VERSION "JSON_REFERENCE_OPTIONAL_3.1.2"

NS_ :

BS_:

BU_:

BO_ 1177 APP_cameraTemperatures: 8 gtw
 SG_ APP_lRepeaterCameraTemperature : 32|8@1+ (1.0,-60.0) [-60|195] "C"  odin
 SG_ APP_rRepeaterCameraTemperature : 24|8@1+ (1.0,-60.0) [-60|195] "C"  odin

BO_ 970 APS_status: 7 gtw
 SG_ APS_canMaster : 8|2@1+ (1.0,0.0) [0|3] ""  odin,sui,ui,vitals

BO_ 818 BMS_bmbMinMax: 6 gtw
 SG_ BMS_bmbMinMaxMultiplexer M : 0|2@1+ (1.0,0.0) [0|2] "" Vector__XXX
 SG_ BMS_brickNumVoltageMax m1 : 32|7@1+ (1,1) [1|128] ""  odin,ui
 SG_ BMS_brickNumVoltageMin m1 : 40|7@1+ (1,1) [1|128] ""  odin,ui
 SG_ BMS_brickVoltageMax m1 : 2|12@1+ (0.002,0.0) [0|5] "V"  odin,ui,vitals
 SG_ BMS_brickVoltageMin m1 : 16|12@1+ (0.002,0.0) [0|5] "V"  odin,ui,vitals

BO_ 562 BMS_contactorRequest: 8 gtw
 SG_ BMS_hvilCoverVSense : 32|16@1+ (0.001,0.0) [0.0|65.534] "V"  odin
 SG_ BMS_internalHvilSenseV : 16|16@1+ (0.001,0.0) [0.0|65.534] "V"  odin

BO_ 306 BMS_hvBusStatus: 8 gtw
 SG_ BMS_packCurrent : 16|16@1- (0.1,0.0) [-3276.7|3276.7] "A"  odin,ui,vitals

BO_ 884 BMS_log1: 8 gtw
 SG_ BMS_log1MuxId M : 0|8@1+ (1.0,0.0) [0|27] "" Vector__XXX
 SG_ BMS_maxModeledPackTemp m10 : 19|11@1+ (0.1,-50.0) [-50|154.7] "C"  odin
 SG_ BMS_minModeledPackTemp m10 : 8|11@1+ (0.1,-50.0) [-50|154.7] "C"  odin

BO_ 914 BMS_packConfig: 8 gtw
 SG_ BMS_packConfigMultiplexer M : 0|8@1+ (1.0,0.0) [0|1] ""  ui
 SG_ BMS_reservedConfig_0 m0 : 8|5@1+ (1.0,0.0) [0|31] ""  odin,ui

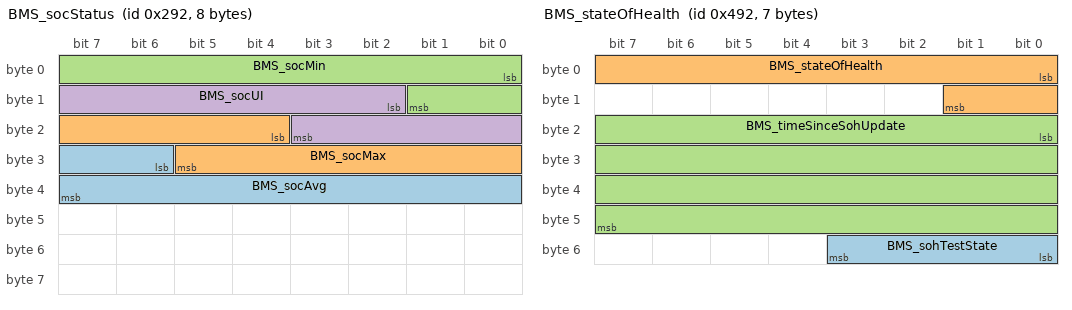
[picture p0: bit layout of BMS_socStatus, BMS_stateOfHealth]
BO_ 658 BMS_socStatus: 8 gtw
 SG_ BMS_socAvg : 30|10@1+ (0.1,0.0) [0|102.2] "%"  odin
 SG_ BMS_socMax : 20|10@1+ (0.1,0.0) [0|102.2] "%"  odin,sui,vitals
 SG_ BMS_socMin : 0|10@1+ (0.1,0.0) [0|102.2] "%"  odin,sui,ui,vitals
 SG_ BMS_socUI : 10|10@1+ (0.1,0.0) [0|100] "%"  odin,ui

BO_ 1170 BMS_stateOfHealth: 7 gtw
 SG_ BMS_sohTestState : 48|4@1+ (1.0,0.0) [0|8] ""  sui
 SG_ BMS_stateOfHealth : 0|10@1+ (0.1,0.0) [0|100] "%"  odin,sui,vitals
 SG_ BMS_timeSinceSohUpdate : 16|32@1+ (1,0) [0|4294967295] "min"  odin,sui,vitals

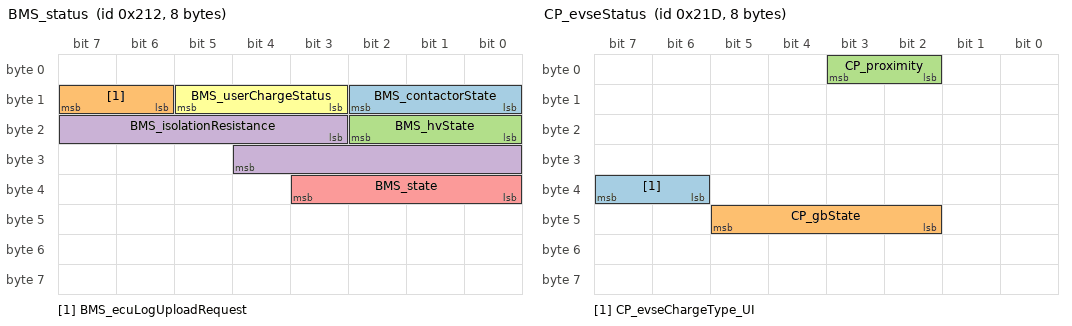
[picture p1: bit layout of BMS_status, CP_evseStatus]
BO_ 530 BMS_status: 8 gtw
 SG_ BMS_contactorState : 8|3@1+ (1.0,0.0) [0|6] ""  odin,sui,ui,vitals
 SG_ BMS_ecuLogUploadRequest : 14|2@1+ (1.0,0.0) [0|3] ""  odin,ui
 SG_ BMS_hvState : 16|3@1+ (1.0,0.0) [0|6] ""  odin,sui,ui,vitals
 SG_ BMS_isolationResistance : 19|10@1+ (10.0,0.0) [0|10000] "kOhm"  odin,sui,ui,vitals
 SG_ BMS_state : 32|4@1+ (1.0,0.0) [0|10] ""  odin,sui,ui,vitals
 SG_ BMS_userChargeStatus : 11|3@1+ (1.0,0.0) [0|6] ""  odin,ui

BO_ 1554 BMS_udsResponse: 8 gtw
 SG_ BMS_udsResponseData : 0|64@0+ (1,0) [0|18446744073709551615] ""  odin

BO_ 1559 CMPD_udsResponse: 8 gtw
 SG_ CMPD_udsResponseData : 7|64@0+ (1,0) [0|18446744073709551615] ""  odin

BO_ 1555 CMP_udsResponse: 8 gtw
 SG_ CMP_udsResponseData : 0|64@0+ (1,0) [0|18446744073709551615] ""  odin

BO_ 541 CP_evseStatus: 8 gtw
 SG_ CP_evseChargeType_UI : 38|2@1+ (1.0,0.0) [0|2] ""  odin,sui,ui
 SG_ CP_gbState : 42|4@1+ (1.0,0.0) [0|15] ""  odin
 SG_ CP_proximity : 2|2@1+ (1.0,0.0) [0|3] ""  odin,sui,ui,vitals

BO_ 1885 CP_loggingFast: 8 gtw
 SG_ CP_chargeCablePresent m0 : 61|1@1+ (1.0,0.0) [0|1] ""  odin,vitals
 SG_ CP_loggingFastSelect M : 0|4@1+ (1.0,0.0) [0|4] "" Vector__XXX

BO_ 528 CP_status: 8 gtw
 SG_ CP_chargeCableState : 14|2@1+ (1.0,0.0) [0|2] ""  odin,ui,vitals

BO_ 1566 CP_udsResponse: 8 gtw
 SG_ CP_udsResponseData : 0|64@0+ (1,0) [0|18446744073709551615] ""  gtwu,odin

BO_ 1625 DAS_udsResponse: 8 gtw
 SG_ DAS_udsResponseData : 0|64@0+ (1,0) [0|18446744073709551615] ""  odin

BO_ 858 DIF_alertMatrix3: 8 gtw
 SG_ DIF_a154_resolver : 25|1@1+ (1,0) [0|1] ""  odin,ui

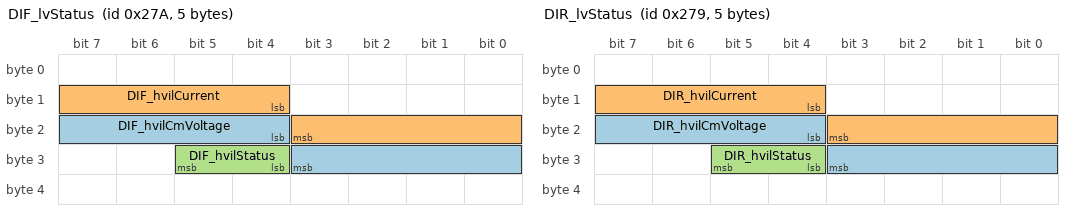
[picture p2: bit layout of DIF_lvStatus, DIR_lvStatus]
BO_ 634 DIF_lvStatus: 5 gtw
 SG_ DIF_hvilCmVoltage : 20|8@1+ (0.08,0.0) [0.0|20.4] "V"  odin
 SG_ DIF_hvilCurrent : 12|8@1+ (0.1,0.0) [0.0|25.5] "mA"  odin
 SG_ DIF_hvilStatus : 28|2@1+ (1.0,0.0) [0|3] ""  odin,vitals

BO_ 725 DIF_status: 7 gtw
 SG_ DIF_wasteState : 32|2@1+ (1.0,0.0) [0|3] ""  odin,sui

BO_ 1557 DIF_udsResponse: 8 gtw
 SG_ DIF_udsResponseData : 7|64@0+ (1,0) [0|18446744073709551615] ""  odin

BO_ 965 DIR_alertMatrix3: 8 gtw
 SG_ DIR_a154_resolver : 25|1@1+ (1,0) [0|1] ""  odin,ui

BO_ 633 DIR_lvStatus: 5 gtw
 SG_ DIR_hvilCmVoltage : 20|8@1+ (0.08,0.0) [0.0|20.4] "V"  odin
 SG_ DIR_hvilCurrent : 12|8@1+ (0.1,0.0) [0.0|25.5] "mA"  odin
 SG_ DIR_hvilStatus : 28|2@1+ (1.0,0.0) [0|3] ""  odin,sui,vitals

BO_ 598 DIR_status: 7 gtw
 SG_ DIR_state : 12|3@1+ (1.0,0.0) [0|4] ""  odin,sui,ui
 SG_ DIR_wasteState : 32|2@1+ (1.0,0.0) [0|3] ""  odin

BO_ 1558 DIR_udsResponse: 8 gtw
 SG_ DIR_udsResponseData : 7|64@0+ (1,0) [0|18446744073709551615] ""  odin

BO_ 599 DI_speed: 8 gtw
 SG_ DI_vehicleSpeed : 43|13@1+ (0.08,-40.0) [-40|480] "kph"  adsp,odin,ui

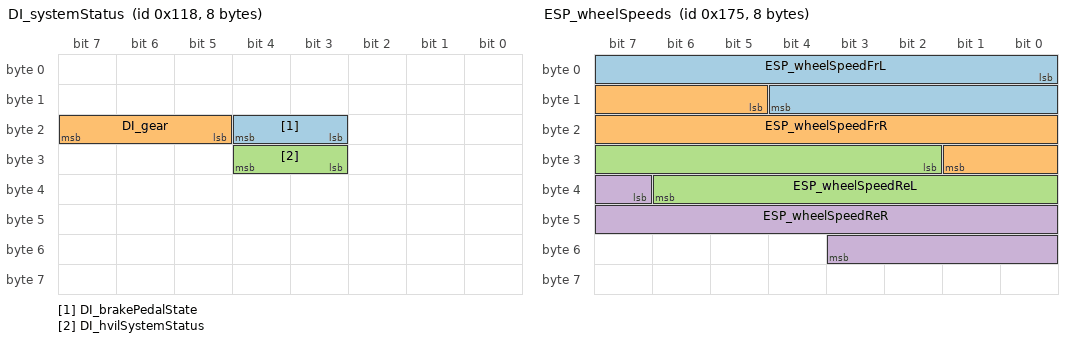
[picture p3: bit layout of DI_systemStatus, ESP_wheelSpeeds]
BO_ 280 DI_systemStatus: 8 gtw
 SG_ DI_brakePedalState : 19|2@1+ (1.0,0.0) [0|2] ""  odin
 SG_ DI_gear : 21|3@1+ (1.0,0.0) [0|7] ""  adsp,odin,sui,ui
 SG_ DI_hvilSystemStatus : 27|2@1+ (1.0,0.0) [0|3] ""  odin

BO_ 615 DI_vehicleEstimates: 8 gtw
 SG_ DI_steeringAngleOffset : 56|8@1- (0.2,0.0) [-25.6|25.4] "Deg"  odin,vitals

BO_ 977 EPAS3P_angleCalibration: 8 gtw
 SG_ EPAS3P_appliedAngleOffset : 0|8@1+ (0.1,-12.8) [-12.8|12.7] "deg"  odin,sui,vitals

BO_ 883 EPAS3P_sysStatus: 8 gtw
 SG_ EPAS3P_internalSAS : 32|14@0+ (0.1,-819.2) [-819.2|819] "deg"  odin
 SG_ EPAS3P_torsionBarTorque : 16|12@0+ (0.01,-20.5) [-20.5|20.45] "Nm"  odin

BO_ 1592 EPAS3P_udsResponseCH: 8 gtw
 SG_ EPAS3P_udsResponseDataCH : 0|64@0+ (1,0) [0|18446744073709551615] ""  odin

BO_ 882 EPAS3S_sysStatus: 8 gtw
 SG_ EPAS3S_torsionBarTorque : 16|12@0+ (0.01,-20.5) [-20.5|20.45] "Nm"  odin

BO_ 1848 EPAS3S_udsResponse: 8 gtw
 SG_ EPAS3S_udsResponseData : 0|64@0+ (1,0) [0|18446744073709551615] ""  odin

BO_ 681 EPBL_status: 8 gtw
 SG_ EPBL_systemStatus : 0|4@1+ (1.0,0.0) [0|8] ""  odin,sui,ui,vitals

BO_ 1573 EPBL_udsResponse: 8 gtw
 SG_ EPBL_udsResponseData_H : 0|32@0+ (1,0) [0|4294967295] ""  odin
 SG_ EPBL_udsResponseData_L : 32|32@0+ (1,0) [0|4294967295] ""  odin

BO_ 744 EPBR_status: 8 gtw
 SG_ EPBR_systemStatus : 0|4@1+ (1.0,0.0) [0|8] ""  odin,sui,ui,vitals

BO_ 1575 EPBR_udsResponse: 8 gtw
 SG_ EPBR_udsResponseData_H : 0|32@0+ (1,0) [0|4294967295] ""  odin
 SG_ EPBR_udsResponseData_L : 32|32@0+ (1,0) [0|4294967295] ""  odin

BO_ 325 ESP_status: 8 gtw
 SG_ ESP_stabilityControlSts2 : 14|2@1+ (1.0,0.0) [0|3] ""  odin,sui

BO_ 1621 ESP_udsResponse: 8 gtw
 SG_ ESP_udsResponseData : 0|64@0+ (1,0) [0|18446744073709551615] ""  odin

BO_ 373 ESP_wheelSpeeds: 8 gtw
 SG_ ESP_wheelSpeedFrL : 0|13@1+ (0.042,0.0) [0|343.98] "km/h"  odin
 SG_ ESP_wheelSpeedFrR : 13|13@1+ (0.042,0.0) [0|343.98] "km/h"  odin
 SG_ ESP_wheelSpeedReL : 26|13@1+ (0.042,0.0) [0|343.98] "km/h"  odin
 SG_ ESP_wheelSpeedReR : 39|13@1+ (0.042,0.0) [0|343.98] "km/h"  odin

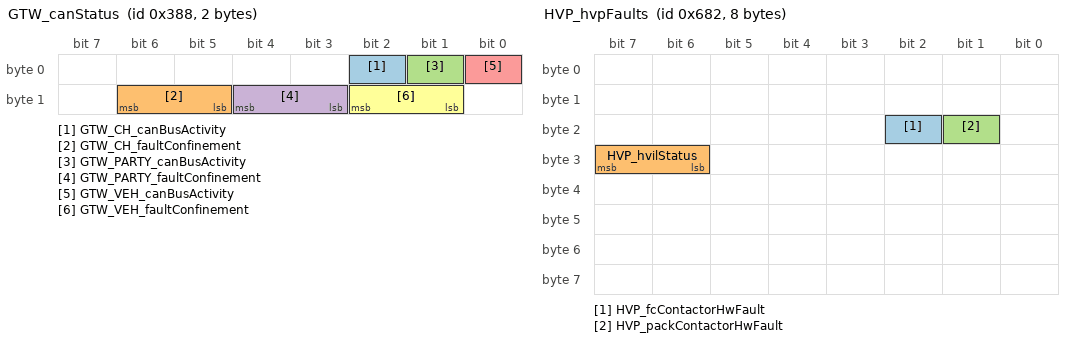
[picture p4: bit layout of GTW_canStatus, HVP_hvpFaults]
BO_ 904 GTW_canStatus: 2 gtw
 SG_ GTW_CH_canBusActivity : 2|1@1+ (1,0) [0|1] ""  odin,sui,ui
 SG_ GTW_CH_faultConfinement : 13|2@1+ (1.0,0.0) [0|2] ""  odin,ui
 SG_ GTW_PARTY_canBusActivity : 1|1@1+ (1,0) [0|1] ""  odin,sui,ui
 SG_ GTW_PARTY_faultConfinement : 11|2@1+ (1.0,0.0) [0|2] ""  odin,ui
 SG_ GTW_VEH_canBusActivity : 0|1@1+ (1,0) [0|1] ""  odin,sui,ui
 SG_ GTW_VEH_faultConfinement : 9|2@1+ (1.0,0.0) [0|2] ""  odin,ui

BO_ 2047 GTW_carConfig: 8 gtw
 SG_ GTW_carConfigMultiplexer M : 0|8@1+ (1,0) [0|255] ""  ui,vitals
 SG_ GTW_chassisType m3 : 18|3@1+ (1.0,0.0) [0|6] ""  odin,ui,vitals
 SG_ GTW_deliveryStatus m1 : 8|1@1+ (1.0,0.0) [0|1] ""  odin,ui,vitals
 SG_ GTW_drivetrainType m1 : 56|4@1+ (1.0,0.0) [0|2] ""  odin,ui,vitals
 SG_ GTW_epasType m6 : 33|3@1+ (1.0,0.0) [0|5] ""  odin,ui,vitals
 SG_ GTW_headlightLevelerType m2 : 59|2@1+ (1.0,0.0) [0|2] ""  odin,ui,vitals
 SG_ GTW_mapRegion m3 : 8|4@1+ (1.0,0.0) [0|12] ""  odin,ui,vitals
 SG_ GTW_numberHVILNodes m2 : 62|2@1+ (1.0,0.0) [0|3] ""  odin,ui,vitals

BO_ 1638 GTW_diagSession: 4 gtw
 SG_ GTW_diagLevel : 17|7@1+ (1.0,0.0) [0|100] ""  odin,sui,ui
 SG_ GTW_diagRemainingSeconds : 0|16@1+ (1,0) [0|65535] "seconds"  odin,sui,ui

BO_ 1376 GTW_factoryEcuPresent: 4 gtw
 SG_ GTW_BMSpresent : 3|1@1+ (1,0) [0|1] ""  odin
 SG_ GTW_CMPpresent : 20|1@1+ (1,0) [0|1] ""  odin
 SG_ GTW_CPpresent : 4|1@1+ (1,0) [0|1] ""  odin
 SG_ GTW_DASpresent : 21|1@1+ (1,0) [0|1] ""  odin
 SG_ GTW_DIFpresent : 28|1@1+ (1,0) [0|1] ""  odin
 SG_ GTW_DIRpresent : 27|1@1+ (1,0) [0|1] ""  odin
 SG_ GTW_EPAS3Ppresent : 8|1@1+ (1,0) [0|1] ""  odin
 SG_ GTW_EPAS3Spresent : 19|1@1+ (1,0) [0|1] ""  odin
 SG_ GTW_EPBLpresent : 9|1@1+ (1,0) [0|1] ""  odin
 SG_ GTW_EPBRpresent : 10|1@1+ (1,0) [0|1] ""  odin
 SG_ GTW_ESPpresent : 11|1@1+ (1,0) [0|1] ""  odin
 SG_ GTW_HVPpresent : 2|1@1+ (1,0) [0|1] ""  odin
 SG_ GTW_IBSTpresent : 12|1@1+ (1,0) [0|1] ""  odin
 SG_ GTW_OCS1Ppresent : 0|1@1+ (1,0) [0|1] ""  odin
 SG_ GTW_PARKpresent : 13|1@1+ (1,0) [0|1] ""  odin
 SG_ GTW_PCSpresent : 1|1@1+ (1,0) [0|1] ""  odin
 SG_ GTW_PMFpresent : 26|1@1+ (1,0) [0|1] ""  odin
 SG_ GTW_PMRpresent : 25|1@1+ (1,0) [0|1] ""  odin
 SG_ GTW_PTCpresent : 22|1@1+ (1,0) [0|1] ""  odin
 SG_ GTW_RADCpresent : 14|1@1+ (1,0) [0|1] ""  odin
 SG_ GTW_RCMpresent : 5|1@1+ (1,0) [0|1] ""  odin
 SG_ GTW_SCCMpresent : 6|1@1+ (1,0) [0|1] ""  odin
 SG_ GTW_SWCpresent : 23|1@1+ (1,0) [0|1] ""  odin
 SG_ GTW_TPMSpresent : 15|1@1+ (1,0) [0|1] ""  odin
 SG_ GTW_VCFRONTpresent : 16|1@1+ (1,0) [0|1] ""  odin
 SG_ GTW_VCLEFTpresent : 17|1@1+ (1,0) [0|1] ""  odin
 SG_ GTW_VCRIGHTpresent : 18|1@1+ (1,0) [0|1] ""  odin
 SG_ GTW_VCSECpresent : 7|1@1+ (1,0) [0|1] ""  odin

BO_ 522 HVP_contactorState: 6 gtw
 SG_ HVP_hvilDiag : 40|4@1+ (1.0,0.0) [0|14] ""  odin,ui,vitals

BO_ 1962 HVP_debugMessage: 8 gtw
 SG_ HVP_debugMessageMultiplexer M : 0|4@1+ (1.0,0.0) [0|12] "" Vector__XXX
 SG_ HVP_ecuLogUploadRequest m0 : 46|2@1+ (1.0,0.0) [0|3] ""  odin,ui
 SG_ HVP_hvilInVoltage m4 : 28|12@1+ (0.1,0.0) [0|30] "V"  odin,ui,vitals
 SG_ HVP_hvilOutVoltage m4 : 40|12@1+ (0.1,0.0) [0|30] "V"  odin,ui,vitals

BO_ 1666 HVP_hvpFaults: 8 gtw
 SG_ HVP_fcContactorHwFault : 18|1@1+ (1,0) [0|1] ""  odin
 SG_ HVP_hvilStatus : 30|2@1+ (1.0,0.0) [0|2] ""  odin,sui
 SG_ HVP_packContactorHwFault : 17|1@1+ (1,0) [0|1] ""  odin

BO_ 1553 HVP_udsResponse: 8 gtw
 SG_ HVP_udsResponseData : 0|64@0+ (1,0) [0|18446744073709551615] ""  gtwu,odin

BO_ 925 IBST_status: 5 gtw
 SG_ IBST_driverBrakeApply : 16|2@1+ (1.0,0.0) [0|3] ""  odin,sui
 SG_ IBST_iBoosterStatus : 12|3@1+ (1.0,0.0) [0|6] ""  odin,sui,ui

BO_ 1629 IBST_udsResponse: 8 gtw
 SG_ IBST_udsResponseData : 0|64@0+ (1,0) [0|18446744073709551615] ""  odin

BO_ 1624 ICR_udsResponse: 8 gtw
 SG_ ICR_udsResponseData : 7|64@0+ (1,0) [0|18446744073709551615] ""  odin

BO_ 771 OCS1P_status: 8 gtw
 SG_ OCS1P_occupiedState : 9|2@1+ (1.0,0.0) [0|3] ""  odin

BO_ 1619 OCS1P_udsResponse: 8 gtw
 SG_ OCS1P_udsResponseData : 0|64@1+ (1,0) [0|18446744073709551615] ""  odin

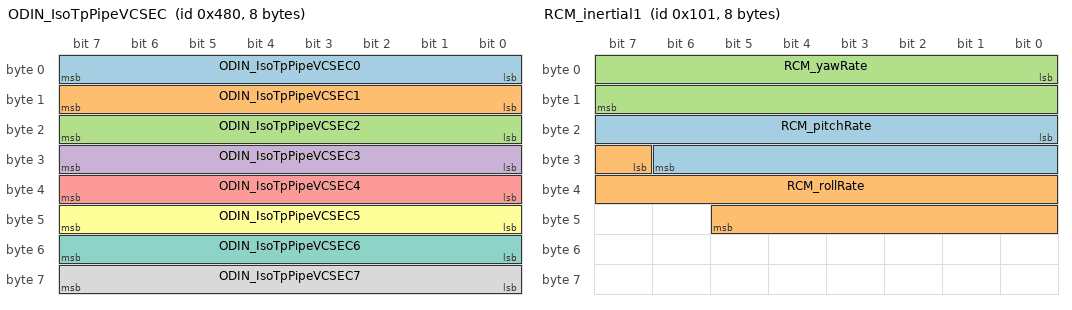
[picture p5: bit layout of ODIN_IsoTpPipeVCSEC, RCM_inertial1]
BO_ 1152 ODIN_IsoTpPipeVCSEC: 8 odin
 SG_ ODIN_IsoTpPipeVCSEC0 : 0|8@1+ (1,0) [0|255] ""  gtw
 SG_ ODIN_IsoTpPipeVCSEC1 : 8|8@1+ (1,0) [0|255] ""  gtw
 SG_ ODIN_IsoTpPipeVCSEC2 : 16|8@1+ (1,0) [0|255] ""  gtw
 SG_ ODIN_IsoTpPipeVCSEC3 : 24|8@1+ (1,0) [0|255] ""  gtw
 SG_ ODIN_IsoTpPipeVCSEC4 : 32|8@1+ (1,0) [0|255] ""  gtw
 SG_ ODIN_IsoTpPipeVCSEC5 : 40|8@1+ (1,0) [0|255] ""  gtw
 SG_ ODIN_IsoTpPipeVCSEC6 : 48|8@1+ (1,0) [0|255] ""  gtw
 SG_ ODIN_IsoTpPipeVCSEC7 : 56|8@1+ (1,0) [0|255] ""  gtw

BO_ 782 PARK_status2: 8 gtw
 SG_ PARK_sdiActive : 24|1@1+ (1.0,0.0) [0|1] ""  odin,sui,ui

BO_ 1630 PARK_udsResponse: 8 gtw
 SG_ PARK_udsResponseData : 0|64@1+ (1,0) [0|18446744073709551615] ""  odin

BO_ 692 PCS_dcdcRailStatus: 6 gtw
 SG_ PCS_dcdcLvBusVolt : 0|13@1+ (0.01,0.0) [0|80] "V"  odin,sui,ui,vitals
 SG_ PCS_dcdcLvOutputCurrent : 32|13@1- (0.1,0.0) [-400|400] "A"  odin,sui,ui,vitals

BO_ 548 PCS_dcdcStatus: 8 gtw
 SG_ PCS_dcdcLvSupportStatus : 2|2@1+ (1.0,0.0) [0|2] ""  odin,sui,ui,vitals
 SG_ PCS_ecuLogUploadRequest : 54|2@1+ (1.0,0.0) [0|3] ""  odin,ui

BO_ 1577 PCS_udsResponse: 8 gtw
 SG_ PCS_udsResponseData : 0|64@0+ (1,0) [0|18446744073709551615] ""  gtwu,odin

BO_ 1635 PLG_udsResponse: 8 gtw
 SG_ PLG_udsResponseData : 7|64@0+ (1,0) [0|18446744073709551615] ""  odin

BO_ 469 PMF_state4: 8 gtw
 SG_ PMF_hvilStatus : 37|2@1+ (1.0,0.0) [0|3] ""  odin

BO_ 1620 PMF_udsResponse: 8 gtw
 SG_ PMF_udsResponseData : 7|64@0+ (1,0) [0|18446744073709551615] ""  odin

BO_ 472 PMR_state4: 8 gtw
 SG_ PMR_hvilStatus : 37|2@1+ (1.0,0.0) [0|3] ""  odin

BO_ 1556 PMR_udsResponse: 8 gtw
 SG_ PMR_udsResponseData : 7|64@0+ (1,0) [0|18446744073709551615] ""  odin

BO_ 463 PM_systemState: 8 gtw
 SG_ PM_hvilSystemStatus : 24|2@1+ (1.0,0.0) [0|3] ""  odin

BO_ 1600 PM_udsResponse: 8 gtw
 SG_ PM_udsResponseData : 7|64@0+ (1,0) [0|18446744073709551615] ""  odin

BO_ 1750 PTC_udsResponse: 8 gtw
 SG_ PTC_udsResponseData : 0|64@0+ (1,0) [0|18446744073709551615] ""  odin

BO_ 1665 RADC_udsResponse: 8 gtw
 SG_ RADC_udsResponseData : 0|64@0+ (1,0) [0|18446744073709551615] ""  gtwu,odin

BO_ 257 RCM_inertial1: 8 gtw
 SG_ RCM_pitchRate : 16|15@1- (0.00025,0.0) [-4.096|4.09575] "rad/s"  odin,ui
 SG_ RCM_rollRate : 31|15@1- (0.00025,0.0) [-4.096|4.09575] "rad/s"  odin,ui
 SG_ RCM_yawRate : 0|16@1- (0.0001,0.0) [-3.2766|3.2766] "rad/s"  odin,ui

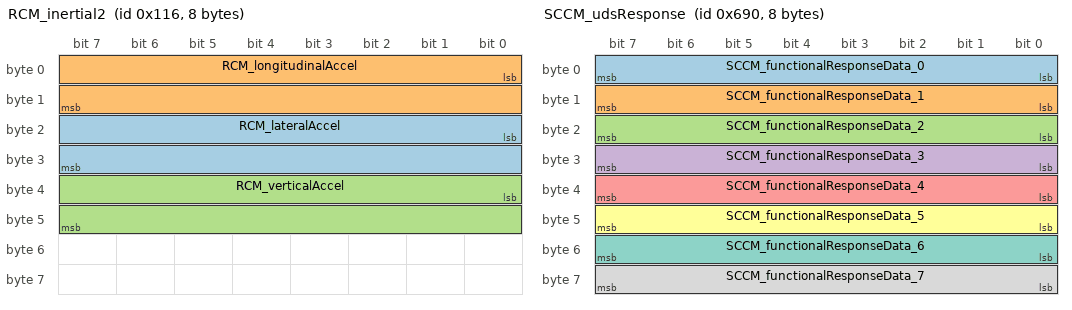
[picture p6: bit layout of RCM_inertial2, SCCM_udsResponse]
BO_ 278 RCM_inertial2: 8 gtw
 SG_ RCM_lateralAccel : 16|16@1- (0.00125,0.0) [-40.9575|40.9575] "m/s^2"  odin,ui
 SG_ RCM_longitudinalAccel : 0|16@1- (0.00125,0.0) [-40.9575|40.9575] "m/s^2"  odin,ui
 SG_ RCM_verticalAccel : 32|16@1- (0.00125,0.0) [-40.9575|40.9575] "m/s^2"  odin,ui

BO_ 529 RCM_status: 6 gtw
 SG_ RCM_armStatus : 12|2@1+ (1.0,0.0) [0|3] ""  odin,sui,ui

BO_ 1617 RCM_udsResponse: 8 gtw
 SG_ RCM_udsResponseData : 0|64@0+ (1,0) [0|18446744073709551615] ""  odin

BO_ 297 SCCM_steeringAngleSensor: 8 gtw
 SG_ SCCM_steeringAngle : 16|14@1+ (0.1,-819.2) [-819.2|819] "deg"  odin,sui,ui

BO_ 1680 SCCM_udsResponse: 8 gtw
 SG_ SCCM_functionalResponseData_0 : 0|8@1+ (1,0) [0|255] ""  odin
 SG_ SCCM_functionalResponseData_1 : 8|8@1+ (1,0) [0|255] ""  odin
 SG_ SCCM_functionalResponseData_2 : 16|8@1+ (1,0) [0|255] ""  odin
 SG_ SCCM_functionalResponseData_3 : 24|8@1+ (1,0) [0|255] ""  odin
 SG_ SCCM_functionalResponseData_4 : 32|8@1+ (1,0) [0|255] ""  odin
 SG_ SCCM_functionalResponseData_5 : 40|8@1+ (1,0) [0|255] ""  odin
 SG_ SCCM_functionalResponseData_6 : 48|8@1+ (1,0) [0|255] ""  odin
 SG_ SCCM_functionalResponseData_7 : 56|8@1+ (1,0) [0|255] ""  odin

BO_ 1787 SDCR_udsResponse: 8 gtw
 SG_ SDCR_udsResponseData : 7|64@0+ (1,0) [0|18446744073709551615] ""  odin

BO_ 1627 TAS_udsResponse: 8 gtw
 SG_ TAS_udsResponseData : 0|64@0+ (1,0) [0|18446744073709551615] ""  odin

BO_ 1631 TPMS_udsResponse: 8 gtw
 SG_ TPMS_udsResponseData : 0|64@0+ (1,0) [0|18446744073709551615] ""  odin

BO_ 1641 UDS_KOSTIAsccmRequest: 8 odin
 SG_ UDS_KOSTIAsccmRequestData : 0|64@0+ (1,0) [0|18446744073709551615] ""  gtw

BO_ 1538 UDS_bmsRequest: 8 odin
 SG_ UDS_bmsRequestData : 0|64@0+ (1,0) [0|18446744073709551615] ""  gtw

BO_ 1579 UDS_ccRequest: 8 odin
 SG_ UDS_ccRequestData : 0|64@0+ (1,0) [0|18446744073709551615] ""  gtw

BO_ 1539 UDS_cmpRequest: 8 odin
 SG_ UDS_cmpRequestData : 0|64@0+ (1,0) [0|18446744073709551615] ""  gtw

BO_ 1543 UDS_cmpdRequest: 8 odin
 SG_ UDS_cmpdRequestData : 7|64@0+ (1,0) [0|18446744073709551615] ""  gtw

BO_ 1550 UDS_cpRequest: 8 odin
 SG_ UDS_cpRequestData : 0|64@0+ (1,0) [0|18446744073709551615] ""  gtw

BO_ 1609 UDS_dasRequest: 8 odin
 SG_ UDS_dasRequestData : 0|64@0+ (1,0) [0|18446744073709551615] ""  gtw

BO_ 1589 UDS_diRequest: 8 odin
 SG_ UDS_diRequestData : 7|64@0+ (1,0) [0|18446744073709551615] ""  gtw

BO_ 1541 UDS_difRequest: 8 odin
 SG_ UDS_difRequestData : 7|64@0+ (1,0) [0|18446744073709551615] ""  gtw

BO_ 1542 UDS_dirRequest: 8 odin
 SG_ UDS_dirRequestData : 7|64@0+ (1,0) [0|18446744073709551615] ""  gtw

BO_ 1584 UDS_epas3pRequest: 8 odin
 SG_ UDS_epas3pRequestData : 0|64@0+ (1,0) [0|18446744073709551615] ""  gtw

BO_ 1840 UDS_epas3sRequest: 8 odin
 SG_ UDS_epas3sRequestData : 0|64@0+ (1,0) [0|18446744073709551615] ""  gtw

BO_ 1572 UDS_epblRequest: 8 odin
 SG_ UDS_epblRequestData_H : 0|32@0+ (1,0) [0|4294967295] ""  gtw
 SG_ UDS_epblRequestData_L : 32|32@0+ (1,0) [0|4294967295] ""  gtw

BO_ 1574 UDS_epbrRequest: 8 odin
 SG_ UDS_epbrRequestData_H : 0|32@0+ (1,0) [0|4294967295] ""  gtw
 SG_ UDS_epbrRequestData_L : 32|32@0+ (1,0) [0|4294967295] ""  gtw

BO_ 1605 UDS_espRequest: 8 odin
 SG_ UDS_espRequestData : 0|64@0+ (1,0) [0|18446744073709551615] ""  gtw

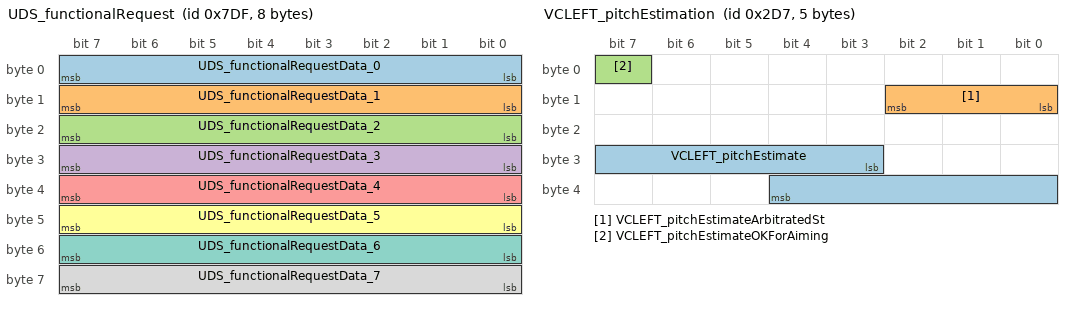
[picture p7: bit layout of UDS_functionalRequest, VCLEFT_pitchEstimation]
BO_ 2015 UDS_functionalRequest: 8 odin
 SG_ UDS_functionalRequestData_0 : 0|8@1+ (1,0) [0|255] ""  gtw
 SG_ UDS_functionalRequestData_1 : 8|8@1+ (1,0) [0|255] ""  gtw
 SG_ UDS_functionalRequestData_2 : 16|8@1+ (1,0) [0|255] ""  gtw
 SG_ UDS_functionalRequestData_3 : 24|8@1+ (1,0) [0|255] ""  gtw
 SG_ UDS_functionalRequestData_4 : 32|8@1+ (1,0) [0|255] ""  gtw
 SG_ UDS_functionalRequestData_5 : 40|8@1+ (1,0) [0|255] ""  gtw
 SG_ UDS_functionalRequestData_6 : 48|8@1+ (1,0) [0|255] ""  gtw
 SG_ UDS_functionalRequestData_7 : 56|8@1+ (1,0) [0|255] ""  gtw

BO_ 2014 UDS_functionalRequest_CH: 8 odin
 SG_ UDS_functionalRequestDataCH : 7|64@0+ (1,0) [0|18446744073709551615] ""  gtw

BO_ 1552 UDS_hvpRequest: 8 odin
 SG_ UDS_hvpRequestData : 0|64@0+ (1,0) [0|18446744073709551615] ""  gtw

BO_ 1613 UDS_ibstRequest: 8 odin
 SG_ UDS_ibstRequestData : 0|64@0+ (1,0) [0|18446744073709551615] ""  gtw

BO_ 1560 UDS_icrRequest: 8 odin
 SG_ UDS_icrRequestData : 7|64@0+ (1,0) [0|18446744073709551615] ""  gtw

BO_ 1603 UDS_ocs1pRequest: 8 odin
 SG_ UDS_ocs1pRequestData : 0|64@0+ (1,0) [0|18446744073709551615] ""  gtw

BO_ 1614 UDS_parkRequest: 8 odin
 SG_ UDS_parkRequestData : 0|64@0+ (1,0) [0|18446744073709551615] ""  gtw

BO_ 1576 UDS_pcsRequest: 8 odin
 SG_ UDS_pcsRequestData : 0|64@0+ (1,0) [0|18446744073709551615] ""  gtw

BO_ 1634 UDS_plgRequest: 8 odin
 SG_ UDS_plgRequestData : 7|64@0+ (1,0) [0|18446744073709551615] ""  gtw

BO_ 1568 UDS_pmRequest: 8 odin
 SG_ UDS_pmRequestData : 7|64@0+ (1,0) [0|18446744073709551615] ""  gtw

BO_ 1604 UDS_pmfRequest: 8 odin
 SG_ UDS_pmfRequestData : 7|64@0+ (1,0) [0|18446744073709551615] ""  gtw

BO_ 1540 UDS_pmrRequest: 8 odin
 SG_ UDS_pmrRequestData : 7|64@0+ (1,0) [0|18446744073709551615] ""  gtw

BO_ 1734 UDS_ptcRequest: 8 odin
 SG_ UDS_ptcRequestData : 0|64@0+ (1,0) [0|18446744073709551615] ""  gtw

BO_ 1649 UDS_radcRequest: 8 odin
 SG_ UDS_radcRequestData : 0|64@0+ (1,0) [0|18446744073709551615] ""  gtw

BO_ 1601 UDS_rcmRequest: 8 odin
 SG_ UDS_rcmRequestData : 0|64@0+ (1,0) [0|18446744073709551615] ""  gtw

BO_ 1664 UDS_sccmRequest: 8 odin
 SG_ UDS_sccmRequestData : 0|64@0+ (1,0) [0|18446744073709551615] ""  gtw

BO_ 1723 UDS_sdcrRequest: 8 odin
 SG_ UDS_sdcrRequestData : 7|64@0+ (1,0) [0|18446744073709551615] ""  gtw

BO_ 1611 UDS_tasRequest: 8 odin
 SG_ UDS_tasRequestData : 0|64@0+ (1,0) [0|18446744073709551615] ""  gtw

BO_ 1551 UDS_thcRequest: 8 odin
 SG_ UDS_thcRequestData_H : 0|32@0+ (1,0) [0|4294967295] "" Vector__XXX
 SG_ UDS_thcRequestData_L : 32|32@0+ (1,0) [0|4294967295] "" Vector__XXX

BO_ 1615 UDS_tpmsRequest: 8 odin
 SG_ UDS_tpmsRequestData : 0|64@0+ (1,0) [0|18446744073709551615] ""  gtw

BO_ 1536 UDS_vcfrontRequest: 8 odin
 SG_ UDS_vcfrontRequestData : 0|64@0+ (1,0) [0|18446744073709551615] ""  gtw

BO_ 1570 UDS_vcleftRequest: 8 odin
 SG_ UDS_vcleftRequestData_H : 0|32@0+ (1,0) [0|4294967295] ""  gtw
 SG_ UDS_vcleftRequestData_L : 32|32@0+ (1,0) [0|4294967295] ""  gtw

BO_ 1544 UDS_vcrightRequest: 8 odin
 SG_ UDS_vcrightRequestData_H : 0|32@0+ (1,0) [0|4294967295] ""  gtw
 SG_ UDS_vcrightRequestData_L : 32|32@0+ (1,0) [0|4294967295] ""  gtw

BO_ 1546 UDS_vcsecRequest: 8 odin
 SG_ UDS_vcsecRequestData : 0|64@0+ (1,0) [0|18446744073709551615] ""  gtw

BO_ 1056 UIS_log: 8 uis
 SG_ UIS_amdSocPkgPower m246 : 32|32@1+ (1,0) [0|4294967295] ""  gtw,odin
 SG_ UIS_logMux M : 0|32@1+ (1.0,0.0) [0|247] "" Vector__XXX
 SG_ UIS_odinAuthCount m95 : 32|32@1+ (1,0) [0|4294967295] ""  gtw
 SG_ UIS_odinAuthFailCount m94 : 32|32@1+ (1,0) [0|4294967295] ""  gtw
 SG_ UIS_odinCPUUsage m93 : 32|32@1+ (1,0) [0|4294967295] ""  gtw
 SG_ UIS_odinGatewayConnectionState m92 : 32|32@1+ (1.0,0.0) [0|2] ""  gtw
 SG_ UIS_odinHermesConnectionState m91 : 32|32@1+ (1.0,0.0) [0|3] ""  gtw
 SG_ UIS_odinListTasksCmdDurationMs m90 : 32|32@1+ (1,0) [0|4294967295] ""  gtw
 SG_ UIS_odinListTasksCmdResult m89 : 32|32@1+ (1.0,0.0) [0|2] ""  gtw
 SG_ UIS_odinMemUsage m88 : 32|32@1+ (1,0) [0|4294967295] ""  gtw
 SG_ UIS_odinNetworkFailCount m87 : 32|32@1+ (1,0) [0|4294967295] ""  gtw
 SG_ UIS_odinNetworkStartCount m86 : 32|32@1+ (1,0) [0|4294967295] ""  gtw
 SG_ UIS_odinOrchestratorFailCount m85 : 32|32@1+ (1,0) [0|4294967295] ""  gtw
 SG_ UIS_odinOrchestratorStartCount m84 : 32|32@1+ (1,0) [0|4294967295] ""  gtw
 SG_ UIS_odinProcessState m83 : 32|32@1+ (1.0,0.0) [0|4] ""  gtw
 SG_ UIS_odinStatusCmdDurationMs m82 : 32|32@1+ (1,0) [0|4294967295] ""  gtw
 SG_ UIS_odinStatusCmdResult m81 : 32|32@1+ (1.0,0.0) [0|2] ""  gtw
 SG_ UIS_odincefCPUUsage m80 : 32|32@1+ (1,0) [0|4294967295] ""  gtw
 SG_ UIS_odincefMemUsage m79 : 32|32@1+ (1,0) [0|4294967295] ""  gtw

BO_ 545 VCFRONT_LVPowerState: 8 gtw
 SG_ VCFRONT_LVPowerStateIndex M : 0|5@1+ (1.0,0.0) [0|1] "" Vector__XXX
 SG_ VCFRONT_dirLVRequest m0 : 34|2@1+ (1.0,0.0) [0|3] ""  odin
 SG_ VCFRONT_vehiclePowerState : 5|2@1+ (1.0,0.0) [0|3] ""  odin,sui,ui,vitals

BO_ 832 VCFRONT_alertMatrix: 8 gtw
 SG_ VCFRONT_a127_vcleftEFuseTrip m2 : 10|1@1+ (1,0) [0|1] ""  odin,ui
 SG_ VCFRONT_a128_vcrightEFuseTrip m2 : 11|1@1+ (1,0) [0|1] ""  odin,ui
 SG_ VCFRONT_a199_PRVCANUndertrminate m3 : 22|1@1+ (1,0) [0|1] ""  odin,ui
 SG_ VCFRONT_a208_brakeFluidLow m3 : 31|1@1+ (1,0) [0|1] ""  odin,ui
 SG_ VCFRONT_a355_coolantSysLockout m5 : 58|1@1+ (1,0) [0|1] ""  odin,ui
 SG_ VCFRONT_a356_refrigSysLockout m5 : 59|1@1+ (1,0) [0|1] ""  odin,ui
 SG_ VCFRONT_matrixIndex M : 0|4@1+ (1.0,0.0) [0|15] ""  ui

BO_ 1014 VCFRONT_lightStatus: 5 gtw
 SG_ VCFRONT_turnSignalLeftStatus : 22|2@1+ (1.0,0.0) [0|3] ""  odin,ui
 SG_ VCFRONT_turnSignalRightStatus : 24|2@1+ (1.0,0.0) [0|3] ""  odin,ui

BO_ 897 VCFRONT_logging1Hz: 8 gtw
 SG_ VCFRONT_currentHorizPositionHCML m19 : 26|10@1+ (1.0,0.0) [0|1022] "Steps"  odin
 SG_ VCFRONT_currentHorizPositionHCMR m19 : 36|10@1+ (1.0,0.0) [0|1022] "Steps"  odin
 SG_ VCFRONT_logging1HzIndex M : 0|5@1+ (1.0,0.0) [0|30] "" Vector__XXX
 SG_ VCFRONT_pumpPowertrainRPMTarget m25 : 35|8@1+ (30.0,0.0) [0|7500] "rpm"  odin
 SG_ VCFRONT_radiatorFanRPMTarget m25 : 51|8@1+ (40.0,0.0) [0|10000] "rpm"  odin

BO_ 513 VCFRONT_loggingAndVitals10Hz: 8 gtw
 SG_ VCFRONT_activeLouverOpenPos m0 : 47|7@1+ (1,0) [0|100] "%"  odin,ui,vitals
 SG_ VCFRONT_coolantValveMode m1 : 32|2@1+ (1.0,0.0) [0|3] ""  odin,sui,ui,vitals
 SG_ VCFRONT_loggingAndVitals10HzInde M : 0|3@1+ (1.0,0.0) [0|4] "" Vector__XXX
 SG_ VCFRONT_pumpPowertrainRPMActual m0 : 16|8@1+ (30.0,0.0) [0|7500] "rpm"  odin,sui,ui,vitals
 SG_ VCFRONT_radiatorFanRPMActual m0 : 24|8@1+ (40.0,0.0) [0|10000] "rpm"  odin,sui,ui,vitals

BO_ 801 VCFRONT_sensors: 8 gtw
 SG_ VCFRONT_tempCoolantBatInlet : 0|10@1+ (0.125,-40.0) [-40|85] "degC"  odin,sui,ui,vitals
 SG_ VCFRONT_tempCoolantPTInlet : 10|11@1+ (0.125,-40.0) [-40|200] "degC"  odin,sui,ui,vitals

BO_ 737 VCFRONT_status: 8 gtw
 SG_ VCFRONT_anyClosureOpen m0 : 49|1@1+ (1,0) [0|1] ""  odin
 SG_ VCFRONT_coolantFillRoutineStatus m3 : 52|2@1+ (1.0,0.0) [0|3] ""  odin,sui,ui
 SG_ VCFRONT_frunkLatchStatus m0 : 3|4@1+ (1.0,0.0) [0|8] ""  odin,ui
 SG_ VCFRONT_refrigFillRoutineStatus m3 : 54|2@1+ (1.0,0.0) [0|3] ""  odin,sui,ui
 SG_ VCFRONT_statusIndex M : 0|3@1+ (1.0,0.0) [0|7] "" Vector__XXX

BO_ 1537 VCFRONT_udsResponse: 8 gtw
 SG_ VCFRONT_udsResponseData : 0|64@0+ (1,0) [0|18446744073709551615] ""  odin

BO_ 864 VCLEFT_alertMatrix: 8 gtw
 SG_ VCLEFT_a251_seatUncalTrack m4 : 14|1@1+ (1,0) [0|1] ""  odin,ui
 SG_ VCLEFT_a252_seatUncalBack m4 : 15|1@1+ (1,0) [0|1] ""  odin,ui
 SG_ VCLEFT_a253_seatUncalTilt m4 : 16|1@1+ (1,0) [0|1] ""  odin,ui
 SG_ VCLEFT_a254_seatUncalLift m4 : 17|1@1+ (1,0) [0|1] ""  odin,ui
 SG_ VCLEFT_a306_handleDisconnectedF m5 : 9|1@1+ (1,0) [0|1] ""  odin,ui
 SG_ VCLEFT_a307_handleDisconnectedR m5 : 10|1@1+ (1,0) [0|1] ""  odin,ui
 SG_ VCLEFT_matrixIndex M : 0|4@1+ (1.0,0.0) [0|15] ""  ui

BO_ 258 VCLEFT_doorStatus: 8 gtw
 SG_ VCLEFT_frontLatchStatus : 14|4@1+ (1.0,0.0) [0|8] ""  odin,sui,ui
 SG_ VCLEFT_rearLatchStatus : 18|4@1+ (1.0,0.0) [0|8] ""  odin,ui

BO_ 322 VCLEFT_liftgateStatus: 8 gtw
 SG_ VCLEFT_liftgateState m0 : 3|4@1+ (1.0,0.0) [0|13] ""  odin
 SG_ VCLEFT_liftgateStatusIndex M : 0|2@1+ (1.0,0.0) [0|2] "" Vector__XXX

BO_ 727 VCLEFT_pitchEstimation: 5 gtw
 SG_ VCLEFT_pitchEstimate : 27|10@1- (0.0002,0.0) [-0.1022|0.1022] "rad"  odin
 SG_ VCLEFT_pitchEstimateArbitratedSt : 8|3@1+ (1.0,0.0) [0|7] ""  odin
 SG_ VCLEFT_pitchEstimateOKForAiming : 7|1@1+ (1,0) [0|1] ""  odin,ui

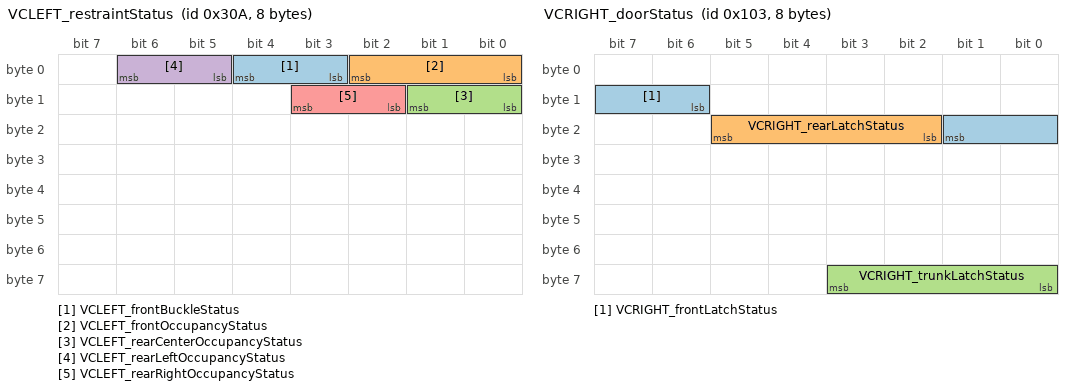
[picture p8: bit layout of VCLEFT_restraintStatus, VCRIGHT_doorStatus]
BO_ 778 VCLEFT_restraintStatus: 8 gtw
 SG_ VCLEFT_frontBuckleStatus : 3|2@1+ (1.0,0.0) [0|3] ""  odin,sui,ui
 SG_ VCLEFT_frontOccupancyStatus : 0|3@1+ (1.0,0.0) [0|7] ""  odin,sui,ui
 SG_ VCLEFT_rearCenterOccupancyStatus : 8|2@1+ (1.0,0.0) [0|3] ""  odin,sui,ui
 SG_ VCLEFT_rearLeftOccupancyStatus : 5|2@1+ (1.0,0.0) [0|3] ""  odin,sui,ui
 SG_ VCLEFT_rearRightOccupancyStatus : 10|2@1+ (1.0,0.0) [0|3] ""  odin,sui,ui

BO_ 1250 VCLEFT_seatStatus: 8 gtw
 SG_ VCLEFT_frontSeatBackPos m1 : 8|16@1- (1,0) [-32768|32767] ""  odin
 SG_ VCLEFT_frontSeatLiftPos m2 : 8|16@1- (1,0) [-32768|32767] ""  odin
 SG_ VCLEFT_frontSeatTiltPos m3 : 8|16@1- (1,0) [-32768|32767] ""  odin
 SG_ VCLEFT_frontSeatTrackPos m0 : 8|16@1- (1,0) [-32768|32767] ""  odin
 SG_ VCLEFT_seatStatusIndex M : 0|3@1+ (1.0,0.0) [0|6] "" Vector__XXX

BO_ 962 VCLEFT_switchStatus: 8 gtw
 SG_ VCLEFT_frontBuckleSwitch m0 : 48|2@1+ (1.0,0.0) [0|3] ""  odin
 SG_ VCLEFT_hornSwitchPressed m0 : 2|1@1+ (1,0) [0|1] ""  adsp,odin,ui
 SG_ VCLEFT_rearCenterBuckleSwitch m0 : 62|2@1+ (1.0,0.0) [0|3] ""  odin
 SG_ VCLEFT_rearCenterOccupancySwitch m0 : 54|2@1+ (1.0,0.0) [0|3] ""  odin
 SG_ VCLEFT_rearLeftBuckleSwitch m0 : 52|2@1+ (1.0,0.0) [0|3] ""  odin
 SG_ VCLEFT_rearLeftOccupancySwitch m0 : 56|2@1+ (1.0,0.0) [0|3] ""  odin
 SG_ VCLEFT_rearRightOccupancySwitch m0 : 58|2@1+ (1.0,0.0) [0|3] ""  odin
 SG_ VCLEFT_switchStatusIndex M : 0|1@1+ (1.0,0.0) [0|1] "" Vector__XXX

BO_ 1571 VCLEFT_udsResponse: 8 gtw
 SG_ VCLEFT_udsResponseData_H : 0|32@0+ (1,0) [0|4294967295] ""  odin
 SG_ VCLEFT_udsResponseData_L : 32|32@0+ (1,0) [0|4294967295] ""  odin

BO_ 706 VCLEFT_windowStatus: 8 gtw
 SG_ VCLEFT_windowCalibratedLF m0 : 32|1@1+ (1,0) [0|1] ""  odin,sui,ui
 SG_ VCLEFT_windowCalibratedLR m0 : 63|1@1+ (1,0) [0|1] ""  odin,sui,ui
 SG_ VCLEFT_windowPositionLF m0 : 22|9@1- (1.25,265.0) [-50|580] "mm"  odin,ui
 SG_ VCLEFT_windowPositionLR m0 : 54|9@1- (1.25,265.0) [-50|580] "mm"  odin,ui
 SG_ VCLEFT_windowStatusIndex M : 0|1@1+ (1.0,0.0) [0|1] "" Vector__XXX

BO_ 960 VCRIGHT_alertMatrix: 8 gtw
 SG_ VCRIGHT_a196_VEHCANOverterminate m3 : 19|1@1+ (1,0) [0|1] ""  odin,ui
 SG_ VCRIGHT_a198_PRVCANOverterminate m3 : 21|1@1+ (1,0) [0|1] ""  odin,ui
 SG_ VCRIGHT_a251_seatUncalTrack m4 : 14|1@1+ (1,0) [0|1] ""  odin,ui
 SG_ VCRIGHT_a252_seatUncalBack m4 : 15|1@1+ (1,0) [0|1] ""  odin,ui
 SG_ VCRIGHT_a253_seatUncalTilt m4 : 16|1@1+ (1,0) [0|1] ""  odin,ui
 SG_ VCRIGHT_a254_seatUncalLift m4 : 17|1@1+ (1,0) [0|1] ""  odin,ui
 SG_ VCRIGHT_a306_handleDisconnectedF m5 : 9|1@1+ (1,0) [0|1] ""  odin,ui
 SG_ VCRIGHT_a307_handleDisconnectedR m5 : 10|1@1+ (1,0) [0|1] ""  odin,ui
 SG_ VCRIGHT_matrixIndex M : 0|4@1+ (1.0,0.0) [0|15] ""  ui

BO_ 259 VCRIGHT_doorStatus: 8 gtw
 SG_ VCRIGHT_frontLatchStatus : 14|4@1+ (1.0,0.0) [0|8] ""  odin,sui,ui
 SG_ VCRIGHT_rearLatchStatus : 18|4@1+ (1.0,0.0) [0|8] ""  odin,ui
 SG_ VCRIGHT_trunkLatchStatus : 56|4@1+ (1.0,0.0) [0|8] ""  odin,ui

BO_ 1251 VCRIGHT_seatStatus: 8 gtw
 SG_ VCRIGHT_frontSeatBackPos m1 : 8|16@1- (1,0) [-32768|32767] ""  odin
 SG_ VCRIGHT_frontSeatLiftPos m2 : 8|16@1- (1,0) [-32768|32767] ""  odin
 SG_ VCRIGHT_frontSeatTiltPos m3 : 8|16@1- (1,0) [-32768|32767] ""  odin
 SG_ VCRIGHT_frontSeatTrackPos m0 : 8|16@1- (1,0) [-32768|32767] ""  odin
 SG_ VCRIGHT_seatStatusIndex M : 0|3@1+ (1.0,0.0) [0|6] "" Vector__XXX

BO_ 963 VCRIGHT_switchStatus: 8 gtw
 SG_ VCRIGHT_frontBuckleSwitch m0 : 40|2@1+ (1.0,0.0) [0|3] ""  odin
 SG_ VCRIGHT_rearCenterBuckleSwitch m0 : 44|2@1+ (1.0,0.0) [0|3] ""  odin
 SG_ VCRIGHT_rearRightBuckleSwitch m0 : 46|2@1+ (1.0,0.0) [0|3] ""  odin
 SG_ VCRIGHT_switchStatusIndex M : 0|1@1+ (1.0,0.0) [0|1] "" Vector__XXX

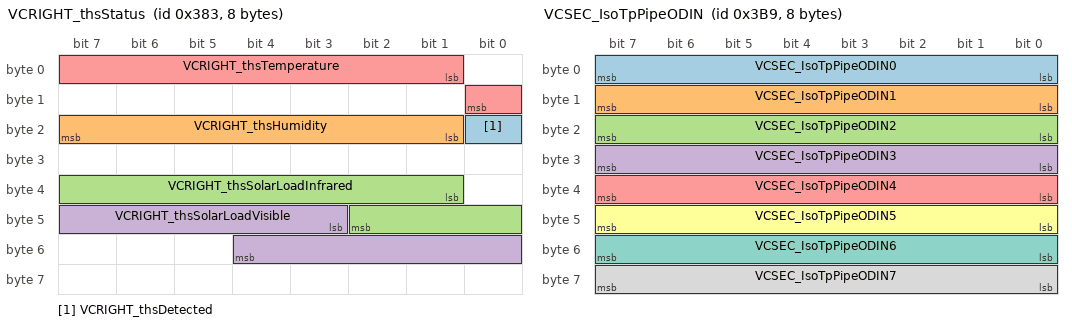
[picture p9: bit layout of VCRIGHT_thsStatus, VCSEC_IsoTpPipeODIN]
BO_ 899 VCRIGHT_thsStatus: 8 gtw
 SG_ VCRIGHT_thsDetected : 16|1@1+ (1,0) [0|1] ""  odin
 SG_ VCRIGHT_thsHumidity : 17|7@1+ (1.0,0.0) [0|100] "%"  odin,ui,vitals
 SG_ VCRIGHT_thsSolarLoadInfrared : 33|10@1+ (1.0,0.0) [0|1022] "W/m2"  odin,ui,vitals
 SG_ VCRIGHT_thsSolarLoadVisible : 43|10@1+ (1.0,0.0) [0|1022] "W/m2"  odin,ui,vitals
 SG_ VCRIGHT_thsTemperature : 1|8@1+ (1.0,-40.0) [-40|150] "degC"  odin,ui,vitals

BO_ 1545 VCRIGHT_udsResponse: 8 gtw
 SG_ VCRIGHT_udsResponseData_H : 0|32@0+ (1,0) [0|4294967295] ""  odin
 SG_ VCRIGHT_udsResponseData_L : 32|32@0+ (1,0) [0|4294967295] ""  odin

BO_ 707 VCRIGHT_windowStatus: 8 gtw
 SG_ VCRIGHT_windowCalibratedRF m0 : 32|1@1+ (1,0) [0|1] ""  odin,sui,ui
 SG_ VCRIGHT_windowCalibratedRR m0 : 63|1@1+ (1,0) [0|1] ""  odin,sui,ui
 SG_ VCRIGHT_windowPositionRF m0 : 22|9@1- (1.25,265.0) [-50|580] "mm"  odin,ui
 SG_ VCRIGHT_windowPositionRR m0 : 54|9@1- (1.25,265.0) [-50|580] "mm"  odin,ui
 SG_ VCRIGHT_windowStatusIndex M : 0|1@1+ (1.0,0.0) [0|1] "" Vector__XXX

BO_ 953 VCSEC_IsoTpPipeODIN: 8 gtw
 SG_ VCSEC_IsoTpPipeODIN0 : 0|8@1+ (1,0) [0|255] ""  odin
 SG_ VCSEC_IsoTpPipeODIN1 : 8|8@1+ (1,0) [0|255] ""  odin
 SG_ VCSEC_IsoTpPipeODIN2 : 16|8@1+ (1,0) [0|255] ""  odin
 SG_ VCSEC_IsoTpPipeODIN3 : 24|8@1+ (1,0) [0|255] ""  odin
 SG_ VCSEC_IsoTpPipeODIN4 : 32|8@1+ (1,0) [0|255] ""  odin
 SG_ VCSEC_IsoTpPipeODIN5 : 40|8@1+ (1,0) [0|255] ""  odin
 SG_ VCSEC_IsoTpPipeODIN6 : 48|8@1+ (1,0) [0|255] ""  odin
 SG_ VCSEC_IsoTpPipeODIN7 : 56|8@1+ (1,0) [0|255] ""  odin

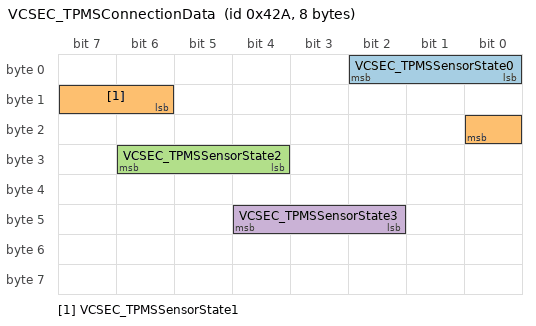
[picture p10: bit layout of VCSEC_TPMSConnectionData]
BO_ 1066 VCSEC_TPMSConnectionData: 8 gtw
 SG_ VCSEC_TPMSSensorState0 : 0|3@1+ (1.0,0.0) [0|5] ""  odin,ui,vitals
 SG_ VCSEC_TPMSSensorState1 : 14|3@1+ (1.0,0.0) [0|5] ""  odin,ui,vitals
 SG_ VCSEC_TPMSSensorState2 : 28|3@1+ (1.0,0.0) [0|5] ""  odin,ui,vitals
 SG_ VCSEC_TPMSSensorState3 : 42|3@1+ (1.0,0.0) [0|5] ""  odin,ui,vitals

BO_ 570 VCSEC_TPMSStatus: 8 gtw
 SG_ VCSEC_TPMSSensorMACAddress0 m0 : 8|48@1+ (1,0) [0|281474976710655] ""  odin,ui,vitals
 SG_ VCSEC_TPMSSensorMACAddress1 m1 : 8|48@1+ (1,0) [0|281474976710655] ""  odin,ui,vitals
 SG_ VCSEC_TPMSSensorMACAddress2 m2 : 8|48@1+ (1,0) [0|281474976710655] ""  odin,ui,vitals
 SG_ VCSEC_TPMSSensorMACAddress3 m3 : 8|48@1+ (1,0) [0|281474976710655] ""  odin,ui,vitals
 SG_ VCSEC_TPMSStatusIndex M : 0|5@1+ (1.0,0.0) [0|19] "" Vector__XXX

BO_ 1547 VCSEC_udsResponse: 8 gtw
 SG_ VCSEC_udsResponseData : 0|64@0+ (1,0) [0|18446744073709551615] ""  odin

BO_ 1655 VC_LVBMS_statusHigh: 8 gtw
 SG_ VC_LVBMS_MOSState m4 : 10|2@1+ (1.0,0.0) [0|3] ""  odin,sui,ui,vitals
 SG_ VC_LVBMS_packCurrent m0 : 3|22@1+ (0.001,-2000.0) [-2000.0|2194.302] "A"  odin,sui,ui,vitals
 SG_ VC_LVBMS_packVoltage m0 : 25|16@1+ (0.001,0.0) [0.0|65.534] "V"  odin,sui,ui,vitals
 SG_ VC_lvbmsStatusHighIndex M : 0|3@1+ (1.0,0.0) [0|6] "" Vector__XXX

BO_ 1816 VC_LVBMS_statusLow: 7 gtw
 SG_ VC_LVBMS_SOC m0 : 8|7@1+ (1.0,0.0) [0|126] "%"  odin,sui,ui,vitals
 SG_ VC_lvbmsStatusLowIndex M : 0|3@1+ (1.0,0.0) [0|6] "" Vector__XXX

CM_ BO_ 1177 "REFERENCE_OPTIONAL converted from Model3_ETH.compact.json; product=Model3; version=3.1.2; bus=eth; not an authoritative vehicle definition";
CM_ SG_ 1177 APP_lRepeaterCameraTemperature "REFERENCE_OPTIONAL; source=Model3_ETH.compact.json; json_start_position=32; conversion_policy=JSON_DIRECT";
CM_ SG_ 1177 APP_rRepeaterCameraTemperature "REFERENCE_OPTIONAL; source=Model3_ETH.compact.json; json_start_position=24; conversion_policy=JSON_DIRECT";
CM_ BO_ 970 "REFERENCE_OPTIONAL converted from Model3_ETH.compact.json; product=Model3; version=3.1.2; bus=eth; not an authoritative vehicle definition";
CM_ SG_ 970 APS_canMaster "REFERENCE_OPTIONAL; source=Model3_ETH.compact.json; json_start_position=8; conversion_policy=JSON_DIRECT";
CM_ BO_ 818 "REFERENCE_OPTIONAL converted from Model3_ETH.compact.json; product=Model3; version=3.1.2; bus=eth; not an authoritative vehicle definition";
CM_ SG_ 818 BMS_brickNumVoltageMin "REFERENCE_OPTIONAL; source=Model3_ETH.compact.json; json_start_position=40; conversion_policy=JSON_DIRECT";
CM_ SG_ 818 BMS_brickNumVoltageMax "REFERENCE_OPTIONAL; source=Model3_ETH.compact.json; json_start_position=32; conversion_policy=JSON_DIRECT";
CM_ SG_ 818 BMS_brickVoltageMin "REFERENCE_OPTIONAL; source=Model3_ETH.compact.json; json_start_position=16; conversion_policy=JSON_DIRECT";
CM_ SG_ 818 BMS_brickVoltageMax "REFERENCE_OPTIONAL; source=Model3_ETH.compact.json; json_start_position=2; conversion_policy=JSON_DIRECT";
CM_ SG_ 818 BMS_bmbMinMaxMultiplexer "REFERENCE_OPTIONAL; source=Model3_ETH.compact.json; json_start_position=0; conversion_policy=JSON_DIRECT";
CM_ BO_ 562 "REFERENCE_OPTIONAL converted from Model3_ETH.compact.json; product=Model3; version=3.1.2; bus=eth; not an authoritative vehicle definition";
CM_ SG_ 562 BMS_hvilCoverVSense "REFERENCE_OPTIONAL; source=Model3_ETH.compact.json; json_start_position=32; conversion_policy=JSON_DIRECT";
CM_ SG_ 562 BMS_internalHvilSenseV "REFERENCE_OPTIONAL; source=Model3_ETH.compact.json; json_start_position=16; conversion_policy=JSON_DIRECT";
CM_ BO_ 306 "REFERENCE_OPTIONAL converted from Model3_ETH.compact.json; product=Model3; version=3.1.2; bus=eth; not an authoritative vehicle definition";
CM_ SG_ 306 BMS_packCurrent "REFERENCE_OPTIONAL; source=Model3_ETH.compact.json; json_start_position=16; conversion_policy=JSON_DIRECT";
CM_ BO_ 884 "REFERENCE_OPTIONAL converted from Model3_ETH.compact.json; product=Model3; version=3.1.2; bus=eth; not an authoritative vehicle definition";
CM_ SG_ 884 BMS_maxModeledPackTemp "REFERENCE_OPTIONAL; source=Model3_ETH.compact.json; json_start_position=19; conversion_policy=JSON_DIRECT";
CM_ SG_ 884 BMS_minModeledPackTemp "REFERENCE_OPTIONAL; source=Model3_ETH.compact.json; json_start_position=8; conversion_policy=JSON_DIRECT";
CM_ SG_ 884 BMS_log1MuxId "REFERENCE_OPTIONAL; source=Model3_ETH.compact.json; json_start_position=0; conversion_policy=JSON_DIRECT";
CM_ BO_ 914 "REFERENCE_OPTIONAL converted from Model3_ETH.compact.json; product=Model3; version=3.1.2; bus=eth; not an authoritative vehicle definition";
CM_ SG_ 914 BMS_reservedConfig_0 "REFERENCE_OPTIONAL; source=Model3_ETH.compact.json; json_start_position=8; conversion_policy=JSON_DIRECT";
CM_ SG_ 914 BMS_packConfigMultiplexer "REFERENCE_OPTIONAL; source=Model3_ETH.compact.json; json_start_position=0; conversion_policy=JSON_DIRECT";
CM_ BO_ 658 "REFERENCE_OPTIONAL converted from Model3_ETH.compact.json; product=Model3; version=3.1.2; bus=eth; not an authoritative vehicle definition";
CM_ SG_ 658 BMS_socAvg "REFERENCE_OPTIONAL; source=Model3_ETH.compact.json; json_start_position=30; conversion_policy=JSON_DIRECT";
CM_ SG_ 658 BMS_socMax "REFERENCE_OPTIONAL; source=Model3_ETH.compact.json; json_start_position=20; conversion_policy=JSON_DIRECT";
CM_ SG_ 658 BMS_socUI "REFERENCE_OPTIONAL; source=Model3_ETH.compact.json; json_start_position=10; conversion_policy=JSON_DIRECT";
CM_ SG_ 658 BMS_socMin "REFERENCE_OPTIONAL; source=Model3_ETH.compact.json; json_start_position=0; conversion_policy=JSON_DIRECT";
CM_ BO_ 1170 "REFERENCE_OPTIONAL converted from Model3_ETH.compact.json; product=Model3; version=3.1.2; bus=eth; not an authoritative vehicle definition";
CM_ SG_ 1170 BMS_sohTestState "REFERENCE_OPTIONAL; source=Model3_ETH.compact.json; json_start_position=48; conversion_policy=JSON_DIRECT";
CM_ SG_ 1170 BMS_timeSinceSohUpdate "REFERENCE_OPTIONAL; source=Model3_ETH.compact.json; json_start_position=16; conversion_policy=JSON_DIRECT";
CM_ SG_ 1170 BMS_stateOfHealth "REFERENCE_OPTIONAL; source=Model3_ETH.compact.json; json_start_position=0; conversion_policy=JSON_DIRECT";
CM_ BO_ 530 "REFERENCE_OPTIONAL converted from Model3_ETH.compact.json; product=Model3; version=3.1.2; bus=eth; not an authoritative vehicle definition";
CM_ SG_ 530 BMS_state "REFERENCE_OPTIONAL; source=Model3_ETH.compact.json; json_start_position=32; conversion_policy=JSON_DIRECT";
CM_ SG_ 530 BMS_isolationResistance "REFERENCE_OPTIONAL; source=Model3_ETH.compact.json; json_start_position=19; conversion_policy=JSON_DIRECT";
CM_ SG_ 530 BMS_hvState "REFERENCE_OPTIONAL; source=Model3_ETH.compact.json; json_start_position=16; conversion_policy=JSON_DIRECT";
CM_ SG_ 530 BMS_ecuLogUploadRequest "REFERENCE_OPTIONAL; source=Model3_ETH.compact.json; json_start_position=14; conversion_policy=JSON_DIRECT";
CM_ SG_ 530 BMS_userChargeStatus "REFERENCE_OPTIONAL; source=Model3_ETH.compact.json; json_start_position=11; conversion_policy=JSON_DIRECT";
CM_ SG_ 530 BMS_contactorState "REFERENCE_OPTIONAL; source=Model3_ETH.compact.json; json_start_position=8; conversion_policy=JSON_DIRECT";
CM_ BO_ 1554 "REFERENCE_OPTIONAL converted from Model3_ETH.compact.json; product=Model3; version=3.1.2; bus=eth; not an authoritative vehicle definition";
CM_ SG_ 1554 BMS_udsResponseData "REFERENCE_OPTIONAL; source=Model3_ETH.compact.json; json_start_position=7; conversion_policy=LOCAL_DBC_START_BIT_ADAPTATION";
CM_ BO_ 1559 "REFERENCE_OPTIONAL converted from Model3_ETH.compact.json; product=Model3; version=3.1.2; bus=eth; not an authoritative vehicle definition";
CM_ SG_ 1559 CMPD_udsResponseData "REFERENCE_OPTIONAL; source=Model3_ETH.compact.json; json_start_position=7; conversion_policy=JSON_BIG_ENDIAN_UNVERIFIED_START";
CM_ BO_ 1555 "REFERENCE_OPTIONAL converted from Model3_ETH.compact.json; product=Model3; version=3.1.2; bus=eth; not an authoritative vehicle definition";
CM_ SG_ 1555 CMP_udsResponseData "REFERENCE_OPTIONAL; source=Model3_ETH.compact.json; json_start_position=7; conversion_policy=LOCAL_DBC_START_BIT_ADAPTATION";
CM_ BO_ 541 "REFERENCE_OPTIONAL converted from Model3_ETH.compact.json; product=Model3; version=3.1.2; bus=eth; not an authoritative vehicle definition";
CM_ SG_ 541 CP_gbState "REFERENCE_OPTIONAL; source=Model3_ETH.compact.json; json_start_position=42; conversion_policy=JSON_DIRECT";
CM_ SG_ 541 CP_evseChargeType_UI "REFERENCE_OPTIONAL; source=Model3_ETH.compact.json; json_start_position=38; conversion_policy=JSON_DIRECT";
CM_ SG_ 541 CP_proximity "REFERENCE_OPTIONAL; source=Model3_ETH.compact.json; json_start_position=2; conversion_policy=JSON_DIRECT";
CM_ BO_ 1885 "REFERENCE_OPTIONAL converted from Model3_ETH.compact.json; product=Model3; version=3.1.2; bus=eth; not an authoritative vehicle definition";
CM_ SG_ 1885 CP_chargeCablePresent "REFERENCE_OPTIONAL; source=Model3_ETH.compact.json; json_start_position=61; conversion_policy=JSON_DIRECT";
CM_ SG_ 1885 CP_loggingFastSelect "REFERENCE_OPTIONAL; source=Model3_ETH.compact.json; json_start_position=0; conversion_policy=JSON_DIRECT";
CM_ BO_ 528 "REFERENCE_OPTIONAL converted from Model3_ETH.compact.json; product=Model3; version=3.1.2; bus=eth; not an authoritative vehicle definition";
CM_ SG_ 528 CP_chargeCableState "REFERENCE_OPTIONAL; source=Model3_ETH.compact.json; json_start_position=14; conversion_policy=JSON_DIRECT";
CM_ BO_ 1566 "REFERENCE_OPTIONAL converted from Model3_ETH.compact.json; product=Model3; version=3.1.2; bus=eth; not an authoritative vehicle definition";
CM_ SG_ 1566 CP_udsResponseData "REFERENCE_OPTIONAL; source=Model3_ETH.compact.json; json_start_position=7; conversion_policy=LOCAL_DBC_START_BIT_ADAPTATION";
CM_ BO_ 1625 "REFERENCE_OPTIONAL converted from Model3_ETH.compact.json; product=Model3; version=3.1.2; bus=eth; not an authoritative vehicle definition";
CM_ SG_ 1625 DAS_udsResponseData "REFERENCE_OPTIONAL; source=Model3_ETH.compact.json; json_start_position=7; conversion_policy=LOCAL_DBC_START_BIT_ADAPTATION";
CM_ BO_ 858 "REFERENCE_OPTIONAL converted from Model3_ETH.compact.json; product=Model3; version=3.1.2; bus=eth; not an authoritative vehicle definition";
CM_ SG_ 858 DIF_a154_resolver "REFERENCE_OPTIONAL; source=Model3_ETH.compact.json; json_start_position=25; conversion_policy=JSON_DIRECT";
CM_ BO_ 634 "REFERENCE_OPTIONAL converted from Model3_ETH.compact.json; product=Model3; version=3.1.2; bus=eth; not an authoritative vehicle definition";
CM_ SG_ 634 DIF_hvilStatus "REFERENCE_OPTIONAL; source=Model3_ETH.compact.json; json_start_position=28; conversion_policy=JSON_DIRECT";
CM_ SG_ 634 DIF_hvilCmVoltage "REFERENCE_OPTIONAL; source=Model3_ETH.compact.json; json_start_position=20; conversion_policy=JSON_DIRECT";
CM_ SG_ 634 DIF_hvilCurrent "REFERENCE_OPTIONAL; source=Model3_ETH.compact.json; json_start_position=12; conversion_policy=JSON_DIRECT";
CM_ BO_ 725 "REFERENCE_OPTIONAL converted from Model3_ETH.compact.json; product=Model3; version=3.1.2; bus=eth; not an authoritative vehicle definition";
CM_ SG_ 725 DIF_wasteState "REFERENCE_OPTIONAL; source=Model3_ETH.compact.json; json_start_position=32; conversion_policy=JSON_DIRECT";
CM_ BO_ 1557 "REFERENCE_OPTIONAL converted from Model3_ETH.compact.json; product=Model3; version=3.1.2; bus=eth; not an authoritative vehicle definition";
CM_ SG_ 1557 DIF_udsResponseData "REFERENCE_OPTIONAL; source=Model3_ETH.compact.json; json_start_position=7; conversion_policy=JSON_BIG_ENDIAN_UNVERIFIED_START";
CM_ BO_ 965 "REFERENCE_OPTIONAL converted from Model3_ETH.compact.json; product=Model3; version=3.1.2; bus=eth; not an authoritative vehicle definition";
CM_ SG_ 965 DIR_a154_resolver "REFERENCE_OPTIONAL; source=Model3_ETH.compact.json; json_start_position=25; conversion_policy=JSON_DIRECT";
CM_ BO_ 633 "REFERENCE_OPTIONAL converted from Model3_ETH.compact.json; product=Model3; version=3.1.2; bus=eth; not an authoritative vehicle definition";
CM_ SG_ 633 DIR_hvilStatus "REFERENCE_OPTIONAL; source=Model3_ETH.compact.json; json_start_position=28; conversion_policy=JSON_DIRECT";
CM_ SG_ 633 DIR_hvilCmVoltage "REFERENCE_OPTIONAL; source=Model3_ETH.compact.json; json_start_position=20; conversion_policy=JSON_DIRECT";
CM_ SG_ 633 DIR_hvilCurrent "REFERENCE_OPTIONAL; source=Model3_ETH.compact.json; json_start_position=12; conversion_policy=JSON_DIRECT";
CM_ BO_ 598 "REFERENCE_OPTIONAL converted from Model3_ETH.compact.json; product=Model3; version=3.1.2; bus=eth; not an authoritative vehicle definition";
CM_ SG_ 598 DIR_wasteState "REFERENCE_OPTIONAL; source=Model3_ETH.compact.json; json_start_position=32; conversion_policy=JSON_DIRECT";
CM_ SG_ 598 DIR_state "REFERENCE_OPTIONAL; source=Model3_ETH.compact.json; json_start_position=12; conversion_policy=JSON_DIRECT";
CM_ BO_ 1558 "REFERENCE_OPTIONAL converted from Model3_ETH.compact.json; product=Model3; version=3.1.2; bus=eth; not an authoritative vehicle definition";
CM_ SG_ 1558 DIR_udsResponseData "REFERENCE_OPTIONAL; source=Model3_ETH.compact.json; json_start_position=7; conversion_policy=JSON_BIG_ENDIAN_UNVERIFIED_START";
CM_ BO_ 599 "REFERENCE_OPTIONAL converted from Model3_ETH.compact.json; product=Model3; version=3.1.2; bus=eth; not an authoritative vehicle definition";
CM_ SG_ 599 DI_vehicleSpeed "REFERENCE_OPTIONAL; source=Model3_ETH.compact.json; json_start_position=43; conversion_policy=JSON_DIRECT";
CM_ BO_ 280 "REFERENCE_OPTIONAL converted from Model3_ETH.compact.json; product=Model3; version=3.1.2; bus=eth; not an authoritative vehicle definition";
CM_ SG_ 280 DI_hvilSystemStatus "REFERENCE_OPTIONAL; source=Model3_ETH.compact.json; json_start_position=27; conversion_policy=JSON_DIRECT";
CM_ SG_ 280 DI_gear "REFERENCE_OPTIONAL; source=Model3_ETH.compact.json; json_start_position=21; conversion_policy=JSON_DIRECT";
CM_ SG_ 280 DI_brakePedalState "REFERENCE_OPTIONAL; source=Model3_ETH.compact.json; json_start_position=19; conversion_policy=JSON_DIRECT";
CM_ BO_ 615 "REFERENCE_OPTIONAL converted from Model3_ETH.compact.json; product=Model3; version=3.1.2; bus=eth; not an authoritative vehicle definition";
CM_ SG_ 615 DI_steeringAngleOffset "REFERENCE_OPTIONAL; source=Model3_ETH.compact.json; json_start_position=56; conversion_policy=JSON_DIRECT";
CM_ BO_ 977 "REFERENCE_OPTIONAL converted from Model3_ETH.compact.json; product=Model3; version=3.1.2; bus=eth; not an authoritative vehicle definition";
CM_ SG_ 977 EPAS3P_appliedAngleOffset "REFERENCE_OPTIONAL; source=Model3_ETH.compact.json; json_start_position=0; conversion_policy=JSON_DIRECT";
CM_ BO_ 883 "REFERENCE_OPTIONAL converted from Model3_ETH.compact.json; product=Model3; version=3.1.2; bus=eth; not an authoritative vehicle definition";
CM_ SG_ 883 EPAS3P_internalSAS "REFERENCE_OPTIONAL; source=Model3_ETH.compact.json; json_start_position=37; conversion_policy=LOCAL_DBC_START_BIT_ADAPTATION";
CM_ SG_ 883 EPAS3P_torsionBarTorque "REFERENCE_OPTIONAL; source=Model3_ETH.compact.json; json_start_position=19; conversion_policy=LOCAL_DBC_START_BIT_ADAPTATION";
CM_ BO_ 1592 "REFERENCE_OPTIONAL converted from Model3_ETH.compact.json; product=Model3; version=3.1.2; bus=eth; not an authoritative vehicle definition";
CM_ SG_ 1592 EPAS3P_udsResponseDataCH "REFERENCE_OPTIONAL; source=Model3_ETH.compact.json; json_start_position=7; conversion_policy=LOCAL_DBC_START_BIT_ADAPTATION";
CM_ BO_ 882 "REFERENCE_OPTIONAL converted from Model3_ETH.compact.json; product=Model3; version=3.1.2; bus=eth; not an authoritative vehicle definition";
CM_ SG_ 882 EPAS3S_torsionBarTorque "REFERENCE_OPTIONAL; source=Model3_ETH.compact.json; json_start_position=19; conversion_policy=LOCAL_DBC_START_BIT_ADAPTATION";
CM_ BO_ 1848 "REFERENCE_OPTIONAL converted from Model3_ETH.compact.json; product=Model3; version=3.1.2; bus=eth; not an authoritative vehicle definition";
CM_ SG_ 1848 EPAS3S_udsResponseData "REFERENCE_OPTIONAL; source=Model3_ETH.compact.json; json_start_position=7; conversion_policy=LOCAL_DBC_START_BIT_ADAPTATION";
CM_ BO_ 681 "REFERENCE_OPTIONAL converted from Model3_ETH.compact.json; product=Model3; version=3.1.2; bus=eth; not an authoritative vehicle definition";
CM_ SG_ 681 EPBL_systemStatus "REFERENCE_OPTIONAL; source=Model3_ETH.compact.json; json_start_position=0; conversion_policy=JSON_DIRECT";
CM_ BO_ 1573 "REFERENCE_OPTIONAL converted from Model3_ETH.compact.json; product=Model3; version=3.1.2; bus=eth; not an authoritative vehicle definition";
CM_ SG_ 1573 EPBL_udsResponseData_L "REFERENCE_OPTIONAL; source=Model3_ETH.compact.json; json_start_position=39; conversion_policy=LOCAL_DBC_START_BIT_ADAPTATION";
CM_ SG_ 1573 EPBL_udsResponseData_H "REFERENCE_OPTIONAL; source=Model3_ETH.compact.json; json_start_position=7; conversion_policy=LOCAL_DBC_START_BIT_ADAPTATION";
CM_ BO_ 744 "REFERENCE_OPTIONAL converted from Model3_ETH.compact.json; product=Model3; version=3.1.2; bus=eth; not an authoritative vehicle definition";
CM_ SG_ 744 EPBR_systemStatus "REFERENCE_OPTIONAL; source=Model3_ETH.compact.json; json_start_position=0; conversion_policy=JSON_DIRECT";
CM_ BO_ 1575 "REFERENCE_OPTIONAL converted from Model3_ETH.compact.json; product=Model3; version=3.1.2; bus=eth; not an authoritative vehicle definition";
CM_ SG_ 1575 EPBR_udsResponseData_L "REFERENCE_OPTIONAL; source=Model3_ETH.compact.json; json_start_position=39; conversion_policy=LOCAL_DBC_START_BIT_ADAPTATION";
CM_ SG_ 1575 EPBR_udsResponseData_H "REFERENCE_OPTIONAL; source=Model3_ETH.compact.json; json_start_position=7; conversion_policy=LOCAL_DBC_START_BIT_ADAPTATION";
CM_ BO_ 325 "REFERENCE_OPTIONAL converted from Model3_ETH.compact.json; product=Model3; version=3.1.2; bus=eth; not an authoritative vehicle definition";
CM_ SG_ 325 ESP_stabilityControlSts2 "REFERENCE_OPTIONAL; source=Model3_ETH.compact.json; json_start_position=14; conversion_policy=JSON_DIRECT";
CM_ BO_ 1621 "REFERENCE_OPTIONAL converted from Model3_ETH.compact.json; product=Model3; version=3.1.2; bus=eth; not an authoritative vehicle definition";
CM_ SG_ 1621 ESP_udsResponseData "REFERENCE_OPTIONAL; source=Model3_ETH.compact.json; json_start_position=7; conversion_policy=LOCAL_DBC_START_BIT_ADAPTATION";
CM_ BO_ 373 "REFERENCE_OPTIONAL converted from Model3_ETH.compact.json; product=Model3; version=3.1.2; bus=eth; not an authoritative vehicle definition";
CM_ SG_ 373 ESP_wheelSpeedReR "REFERENCE_OPTIONAL; source=Model3_ETH.compact.json; json_start_position=39; conversion_policy=JSON_DIRECT";
CM_ SG_ 373 ESP_wheelSpeedReL "REFERENCE_OPTIONAL; source=Model3_ETH.compact.json; json_start_position=26; conversion_policy=JSON_DIRECT";
CM_ SG_ 373 ESP_wheelSpeedFrR "REFERENCE_OPTIONAL; source=Model3_ETH.compact.json; json_start_position=13; conversion_policy=JSON_DIRECT";
CM_ SG_ 373 ESP_wheelSpeedFrL "REFERENCE_OPTIONAL; source=Model3_ETH.compact.json; json_start_position=0; conversion_policy=JSON_DIRECT";
CM_ BO_ 904 "REFERENCE_OPTIONAL converted from Model3_ETH.compact.json; product=Model3; version=3.1.2; bus=eth; not an authoritative vehicle definition";
CM_ SG_ 904 GTW_CH_faultConfinement "REFERENCE_OPTIONAL; source=Model3_ETH.compact.json; json_start_position=13; conversion_policy=JSON_DIRECT";
CM_ SG_ 904 GTW_PARTY_faultConfinement "REFERENCE_OPTIONAL; source=Model3_ETH.compact.json; json_start_position=11; conversion_policy=JSON_DIRECT";
CM_ SG_ 904 GTW_VEH_faultConfinement "REFERENCE_OPTIONAL; source=Model3_ETH.compact.json; json_start_position=9; conversion_policy=JSON_DIRECT";
CM_ SG_ 904 GTW_CH_canBusActivity "REFERENCE_OPTIONAL; source=Model3_ETH.compact.json; json_start_position=2; conversion_policy=JSON_DIRECT";
CM_ SG_ 904 GTW_PARTY_canBusActivity "REFERENCE_OPTIONAL; source=Model3_ETH.compact.json; json_start_position=1; conversion_policy=JSON_DIRECT";
CM_ SG_ 904 GTW_VEH_canBusActivity "REFERENCE_OPTIONAL; source=Model3_ETH.compact.json; json_start_position=0; conversion_policy=JSON_DIRECT";
CM_ BO_ 2047 "REFERENCE_OPTIONAL converted from Model3_ETH.compact.json; product=Model3; version=3.1.2; bus=eth; not an authoritative vehicle definition";
CM_ SG_ 2047 GTW_numberHVILNodes "REFERENCE_OPTIONAL; source=Model3_ETH.compact.json; json_start_position=62; conversion_policy=JSON_DIRECT";
CM_ SG_ 2047 GTW_headlightLevelerType "REFERENCE_OPTIONAL; source=Model3_ETH.compact.json; json_start_position=59; conversion_policy=JSON_DIRECT";
CM_ SG_ 2047 GTW_drivetrainType "REFERENCE_OPTIONAL; source=Model3_ETH.compact.json; json_start_position=56; conversion_policy=JSON_DIRECT";
CM_ SG_ 2047 GTW_epasType "REFERENCE_OPTIONAL; source=Model3_ETH.compact.json; json_start_position=33; conversion_policy=JSON_DIRECT";
CM_ SG_ 2047 GTW_chassisType "REFERENCE_OPTIONAL; source=Model3_ETH.compact.json; json_start_position=18; conversion_policy=JSON_DIRECT";
CM_ SG_ 2047 GTW_mapRegion "REFERENCE_OPTIONAL; source=Model3_ETH.compact.json; json_start_position=8; conversion_policy=JSON_DIRECT";
CM_ SG_ 2047 GTW_deliveryStatus "REFERENCE_OPTIONAL; source=Model3_ETH.compact.json; json_start_position=8; conversion_policy=JSON_DIRECT";
CM_ SG_ 2047 GTW_carConfigMultiplexer "REFERENCE_OPTIONAL; source=Model3_ETH.compact.json; json_start_position=0; conversion_policy=JSON_DIRECT";
CM_ BO_ 1638 "REFERENCE_OPTIONAL converted from Model3_ETH.compact.json; product=Model3; version=3.1.2; bus=eth; not an authoritative vehicle definition";
CM_ SG_ 1638 GTW_diagLevel "REFERENCE_OPTIONAL; source=Model3_ETH.compact.json; json_start_position=17; conversion_policy=JSON_DIRECT";
CM_ SG_ 1638 GTW_diagRemainingSeconds "REFERENCE_OPTIONAL; source=Model3_ETH.compact.json; json_start_position=0; conversion_policy=JSON_DIRECT";
CM_ BO_ 1376 "REFERENCE_OPTIONAL converted from Model3_ETH.compact.json; product=Model3; version=3.1.2; bus=eth; not an authoritative vehicle definition";
CM_ SG_ 1376 GTW_DIFpresent "REFERENCE_OPTIONAL; source=Model3_ETH.compact.json; json_start_position=28; conversion_policy=JSON_DIRECT";
CM_ SG_ 1376 GTW_DIRpresent "REFERENCE_OPTIONAL; source=Model3_ETH.compact.json; json_start_position=27; conversion_policy=JSON_DIRECT";
CM_ SG_ 1376 GTW_PMFpresent "REFERENCE_OPTIONAL; source=Model3_ETH.compact.json; json_start_position=26; conversion_policy=JSON_DIRECT";
CM_ SG_ 1376 GTW_PMRpresent "REFERENCE_OPTIONAL; source=Model3_ETH.compact.json; json_start_position=25; conversion_policy=JSON_DIRECT";
CM_ SG_ 1376 GTW_SWCpresent "REFERENCE_OPTIONAL; source=Model3_ETH.compact.json; json_start_position=23; conversion_policy=JSON_DIRECT";
CM_ SG_ 1376 GTW_PTCpresent "REFERENCE_OPTIONAL; source=Model3_ETH.compact.json; json_start_position=22; conversion_policy=JSON_DIRECT";
CM_ SG_ 1376 GTW_DASpresent "REFERENCE_OPTIONAL; source=Model3_ETH.compact.json; json_start_position=21; conversion_policy=JSON_DIRECT";
CM_ SG_ 1376 GTW_CMPpresent "REFERENCE_OPTIONAL; source=Model3_ETH.compact.json; json_start_position=20; conversion_policy=JSON_DIRECT";
CM_ SG_ 1376 GTW_EPAS3Spresent "REFERENCE_OPTIONAL; source=Model3_ETH.compact.json; json_start_position=19; conversion_policy=JSON_DIRECT";
CM_ SG_ 1376 GTW_VCRIGHTpresent "REFERENCE_OPTIONAL; source=Model3_ETH.compact.json; json_start_position=18; conversion_policy=JSON_DIRECT";
CM_ SG_ 1376 GTW_VCLEFTpresent "REFERENCE_OPTIONAL; source=Model3_ETH.compact.json; json_start_position=17; conversion_policy=JSON_DIRECT";
CM_ SG_ 1376 GTW_VCFRONTpresent "REFERENCE_OPTIONAL; source=Model3_ETH.compact.json; json_start_position=16; conversion_policy=JSON_DIRECT";
CM_ SG_ 1376 GTW_TPMSpresent "REFERENCE_OPTIONAL; source=Model3_ETH.compact.json; json_start_position=15; conversion_policy=JSON_DIRECT";
CM_ SG_ 1376 GTW_RADCpresent "REFERENCE_OPTIONAL; source=Model3_ETH.compact.json; json_start_position=14; conversion_policy=JSON_DIRECT";
CM_ SG_ 1376 GTW_PARKpresent "REFERENCE_OPTIONAL; source=Model3_ETH.compact.json; json_start_position=13; conversion_policy=JSON_DIRECT";
CM_ SG_ 1376 GTW_IBSTpresent "REFERENCE_OPTIONAL; source=Model3_ETH.compact.json; json_start_position=12; conversion_policy=JSON_DIRECT";
CM_ SG_ 1376 GTW_ESPpresent "REFERENCE_OPTIONAL; source=Model3_ETH.compact.json; json_start_position=11; conversion_policy=JSON_DIRECT";
CM_ SG_ 1376 GTW_EPBRpresent "REFERENCE_OPTIONAL; source=Model3_ETH.compact.json; json_start_position=10; conversion_policy=JSON_DIRECT";
CM_ SG_ 1376 GTW_EPBLpresent "REFERENCE_OPTIONAL; source=Model3_ETH.compact.json; json_start_position=9; conversion_policy=JSON_DIRECT";
CM_ SG_ 1376 GTW_EPAS3Ppresent "REFERENCE_OPTIONAL; source=Model3_ETH.compact.json; json_start_position=8; conversion_policy=JSON_DIRECT";
CM_ SG_ 1376 GTW_VCSECpresent "REFERENCE_OPTIONAL; source=Model3_ETH.compact.json; json_start_position=7; conversion_policy=JSON_DIRECT";
CM_ SG_ 1376 GTW_SCCMpresent "REFERENCE_OPTIONAL; source=Model3_ETH.compact.json; json_start_position=6; conversion_policy=JSON_DIRECT";
CM_ SG_ 1376 GTW_RCMpresent "REFERENCE_OPTIONAL; source=Model3_ETH.compact.json; json_start_position=5; conversion_policy=JSON_DIRECT";
CM_ SG_ 1376 GTW_CPpresent "REFERENCE_OPTIONAL; source=Model3_ETH.compact.json; json_start_position=4; conversion_policy=JSON_DIRECT";
CM_ SG_ 1376 GTW_BMSpresent "REFERENCE_OPTIONAL; source=Model3_ETH.compact.json; json_start_position=3; conversion_policy=JSON_DIRECT";
CM_ SG_ 1376 GTW_HVPpresent "REFERENCE_OPTIONAL; source=Model3_ETH.compact.json; json_start_position=2; conversion_policy=JSON_DIRECT";
CM_ SG_ 1376 GTW_PCSpresent "REFERENCE_OPTIONAL; source=Model3_ETH.compact.json; json_start_position=1; conversion_policy=JSON_DIRECT";
CM_ SG_ 1376 GTW_OCS1Ppresent "REFERENCE_OPTIONAL; source=Model3_ETH.compact.json; json_start_position=0; conversion_policy=JSON_DIRECT";
CM_ BO_ 522 "REFERENCE_OPTIONAL converted from Model3_ETH.compact.json; product=Model3; version=3.1.2; bus=eth; not an authoritative vehicle definition";
CM_ SG_ 522 HVP_hvilDiag "REFERENCE_OPTIONAL; source=Model3_ETH.compact.json; json_start_position=40; conversion_policy=JSON_DIRECT";
CM_ BO_ 1962 "REFERENCE_OPTIONAL converted from Model3_ETH.compact.json; product=Model3; version=3.1.2; bus=eth; not an authoritative vehicle definition";
CM_ SG_ 1962 HVP_ecuLogUploadRequest "REFERENCE_OPTIONAL; source=Model3_ETH.compact.json; json_start_position=46; conversion_policy=JSON_DIRECT";
CM_ SG_ 1962 HVP_hvilOutVoltage "REFERENCE_OPTIONAL; source=Model3_ETH.compact.json; json_start_position=40; conversion_policy=JSON_DIRECT";
CM_ SG_ 1962 HVP_hvilInVoltage "REFERENCE_OPTIONAL; source=Model3_ETH.compact.json; json_start_position=28; conversion_policy=JSON_DIRECT";
CM_ SG_ 1962 HVP_debugMessageMultiplexer "REFERENCE_OPTIONAL; source=Model3_ETH.compact.json; json_start_position=0; conversion_policy=JSON_DIRECT";
CM_ BO_ 1666 "REFERENCE_OPTIONAL converted from Model3_ETH.compact.json; product=Model3; version=3.1.2; bus=eth; not an authoritative vehicle definition";
CM_ SG_ 1666 HVP_hvilStatus "REFERENCE_OPTIONAL; source=Model3_ETH.compact.json; json_start_position=30; conversion_policy=JSON_DIRECT";
CM_ SG_ 1666 HVP_fcContactorHwFault "REFERENCE_OPTIONAL; source=Model3_ETH.compact.json; json_start_position=18; conversion_policy=JSON_DIRECT";
CM_ SG_ 1666 HVP_packContactorHwFault "REFERENCE_OPTIONAL; source=Model3_ETH.compact.json; json_start_position=17; conversion_policy=JSON_DIRECT";
CM_ BO_ 1553 "REFERENCE_OPTIONAL converted from Model3_ETH.compact.json; product=Model3; version=3.1.2; bus=eth; not an authoritative vehicle definition";
CM_ SG_ 1553 HVP_udsResponseData "REFERENCE_OPTIONAL; source=Model3_ETH.compact.json; json_start_position=7; conversion_policy=LOCAL_DBC_START_BIT_ADAPTATION";
CM_ BO_ 925 "REFERENCE_OPTIONAL converted from Model3_ETH.compact.json; product=Model3; version=3.1.2; bus=eth; not an authoritative vehicle definition";
CM_ SG_ 925 IBST_driverBrakeApply "REFERENCE_OPTIONAL; source=Model3_ETH.compact.json; json_start_position=16; conversion_policy=JSON_DIRECT";
CM_ SG_ 925 IBST_iBoosterStatus "REFERENCE_OPTIONAL; source=Model3_ETH.compact.json; json_start_position=12; conversion_policy=JSON_DIRECT";
CM_ BO_ 1629 "REFERENCE_OPTIONAL converted from Model3_ETH.compact.json; product=Model3; version=3.1.2; bus=eth; not an authoritative vehicle definition";
CM_ SG_ 1629 IBST_udsResponseData "REFERENCE_OPTIONAL; source=Model3_ETH.compact.json; json_start_position=7; conversion_policy=LOCAL_DBC_START_BIT_ADAPTATION";
CM_ BO_ 1624 "REFERENCE_OPTIONAL converted from Model3_ETH.compact.json; product=Model3; version=3.1.2; bus=eth; not an authoritative vehicle definition";
CM_ SG_ 1624 ICR_udsResponseData "REFERENCE_OPTIONAL; source=Model3_ETH.compact.json; json_start_position=7; conversion_policy=JSON_BIG_ENDIAN_UNVERIFIED_START";
CM_ BO_ 771 "REFERENCE_OPTIONAL converted from Model3_ETH.compact.json; product=Model3; version=3.1.2; bus=eth; not an authoritative vehicle definition";
CM_ SG_ 771 OCS1P_occupiedState "REFERENCE_OPTIONAL; source=Model3_ETH.compact.json; json_start_position=9; conversion_policy=JSON_DIRECT";
CM_ BO_ 1619 "REFERENCE_OPTIONAL converted from Model3_ETH.compact.json; product=Model3; version=3.1.2; bus=eth; not an authoritative vehicle definition";
CM_ SG_ 1619 OCS1P_udsResponseData "REFERENCE_OPTIONAL; source=Model3_ETH.compact.json; json_start_position=0; conversion_policy=JSON_DIRECT";
CM_ BO_ 1152 "REFERENCE_OPTIONAL converted from Model3_ETH.compact.json; product=Model3; version=3.1.2; bus=eth; not an authoritative vehicle definition";
CM_ SG_ 1152 ODIN_IsoTpPipeVCSEC7 "REFERENCE_OPTIONAL; source=Model3_ETH.compact.json; json_start_position=63; conversion_policy=LOCAL_DBC_START_BIT_ADAPTATION";
CM_ SG_ 1152 ODIN_IsoTpPipeVCSEC6 "REFERENCE_OPTIONAL; source=Model3_ETH.compact.json; json_start_position=55; conversion_policy=LOCAL_DBC_START_BIT_ADAPTATION";
CM_ SG_ 1152 ODIN_IsoTpPipeVCSEC5 "REFERENCE_OPTIONAL; source=Model3_ETH.compact.json; json_start_position=47; conversion_policy=LOCAL_DBC_START_BIT_ADAPTATION";
CM_ SG_ 1152 ODIN_IsoTpPipeVCSEC4 "REFERENCE_OPTIONAL; source=Model3_ETH.compact.json; json_start_position=39; conversion_policy=LOCAL_DBC_START_BIT_ADAPTATION";
CM_ SG_ 1152 ODIN_IsoTpPipeVCSEC3 "REFERENCE_OPTIONAL; source=Model3_ETH.compact.json; json_start_position=31; conversion_policy=LOCAL_DBC_START_BIT_ADAPTATION";
CM_ SG_ 1152 ODIN_IsoTpPipeVCSEC2 "REFERENCE_OPTIONAL; source=Model3_ETH.compact.json; json_start_position=23; conversion_policy=LOCAL_DBC_START_BIT_ADAPTATION";
CM_ SG_ 1152 ODIN_IsoTpPipeVCSEC1 "REFERENCE_OPTIONAL; source=Model3_ETH.compact.json; json_start_position=15; conversion_policy=LOCAL_DBC_START_BIT_ADAPTATION";
CM_ SG_ 1152 ODIN_IsoTpPipeVCSEC0 "REFERENCE_OPTIONAL; source=Model3_ETH.compact.json; json_start_position=7; conversion_policy=LOCAL_DBC_START_BIT_ADAPTATION";
CM_ BO_ 782 "REFERENCE_OPTIONAL converted from Model3_ETH.compact.json; product=Model3; version=3.1.2; bus=eth; not an authoritative vehicle definition";
CM_ SG_ 782 PARK_sdiActive "REFERENCE_OPTIONAL; source=Model3_ETH.compact.json; json_start_position=24; conversion_policy=JSON_DIRECT";
CM_ BO_ 1630 "REFERENCE_OPTIONAL converted from Model3_ETH.compact.json; product=Model3; version=3.1.2; bus=eth; not an authoritative vehicle definition";
CM_ SG_ 1630 PARK_udsResponseData "REFERENCE_OPTIONAL; source=Model3_ETH.compact.json; json_start_position=0; conversion_policy=JSON_DIRECT";
CM_ BO_ 692 "REFERENCE_OPTIONAL converted from Model3_ETH.compact.json; product=Model3; version=3.1.2; bus=eth; not an authoritative vehicle definition";
CM_ SG_ 692 PCS_dcdcLvOutputCurrent "REFERENCE_OPTIONAL; source=Model3_ETH.compact.json; json_start_position=32; conversion_policy=JSON_DIRECT";
CM_ SG_ 692 PCS_dcdcLvBusVolt "REFERENCE_OPTIONAL; source=Model3_ETH.compact.json; json_start_position=0; conversion_policy=JSON_DIRECT";
CM_ BO_ 548 "REFERENCE_OPTIONAL converted from Model3_ETH.compact.json; product=Model3; version=3.1.2; bus=eth; not an authoritative vehicle definition";
CM_ SG_ 548 PCS_ecuLogUploadRequest "REFERENCE_OPTIONAL; source=Model3_ETH.compact.json; json_start_position=54; conversion_policy=JSON_DIRECT";
CM_ SG_ 548 PCS_dcdcLvSupportStatus "REFERENCE_OPTIONAL; source=Model3_ETH.compact.json; json_start_position=2; conversion_policy=JSON_DIRECT";
CM_ BO_ 1577 "REFERENCE_OPTIONAL converted from Model3_ETH.compact.json; product=Model3; version=3.1.2; bus=eth; not an authoritative vehicle definition";
CM_ SG_ 1577 PCS_udsResponseData "REFERENCE_OPTIONAL; source=Model3_ETH.compact.json; json_start_position=7; conversion_policy=LOCAL_DBC_START_BIT_ADAPTATION";
CM_ BO_ 1635 "REFERENCE_OPTIONAL converted from Model3_ETH.compact.json; product=Model3; version=3.1.2; bus=eth; not an authoritative vehicle definition";
CM_ SG_ 1635 PLG_udsResponseData "REFERENCE_OPTIONAL; source=Model3_ETH.compact.json; json_start_position=7; conversion_policy=JSON_BIG_ENDIAN_UNVERIFIED_START";
CM_ BO_ 469 "REFERENCE_OPTIONAL converted from Model3_ETH.compact.json; product=Model3; version=3.1.2; bus=eth; not an authoritative vehicle definition";
CM_ SG_ 469 PMF_hvilStatus "REFERENCE_OPTIONAL; source=Model3_ETH.compact.json; json_start_position=37; conversion_policy=JSON_DIRECT";
CM_ BO_ 1620 "REFERENCE_OPTIONAL converted from Model3_ETH.compact.json; product=Model3; version=3.1.2; bus=eth; not an authoritative vehicle definition";
CM_ SG_ 1620 PMF_udsResponseData "REFERENCE_OPTIONAL; source=Model3_ETH.compact.json; json_start_position=7; conversion_policy=JSON_BIG_ENDIAN_UNVERIFIED_START";
CM_ BO_ 472 "REFERENCE_OPTIONAL converted from Model3_ETH.compact.json; product=Model3; version=3.1.2; bus=eth; not an authoritative vehicle definition";
CM_ SG_ 472 PMR_hvilStatus "REFERENCE_OPTIONAL; source=Model3_ETH.compact.json; json_start_position=37; conversion_policy=JSON_DIRECT";
CM_ BO_ 1556 "REFERENCE_OPTIONAL converted from Model3_ETH.compact.json; product=Model3; version=3.1.2; bus=eth; not an authoritative vehicle definition";
CM_ SG_ 1556 PMR_udsResponseData "REFERENCE_OPTIONAL; source=Model3_ETH.compact.json; json_start_position=7; conversion_policy=JSON_BIG_ENDIAN_UNVERIFIED_START";
CM_ BO_ 463 "REFERENCE_OPTIONAL converted from Model3_ETH.compact.json; product=Model3; version=3.1.2; bus=eth; not an authoritative vehicle definition";
CM_ SG_ 463 PM_hvilSystemStatus "REFERENCE_OPTIONAL; source=Model3_ETH.compact.json; json_start_position=24; conversion_policy=JSON_DIRECT";
CM_ BO_ 1600 "REFERENCE_OPTIONAL converted from Model3_ETH.compact.json; product=Model3; version=3.1.2; bus=eth; not an authoritative vehicle definition";
CM_ SG_ 1600 PM_udsResponseData "REFERENCE_OPTIONAL; source=Model3_ETH.compact.json; json_start_position=7; conversion_policy=JSON_BIG_ENDIAN_UNVERIFIED_START";
CM_ BO_ 1750 "REFERENCE_OPTIONAL converted from Model3_ETH.compact.json; product=Model3; version=3.1.2; bus=eth; not an authoritative vehicle definition";
CM_ SG_ 1750 PTC_udsResponseData "REFERENCE_OPTIONAL; source=Model3_ETH.compact.json; json_start_position=7; conversion_policy=LOCAL_DBC_START_BIT_ADAPTATION";
CM_ BO_ 1665 "REFERENCE_OPTIONAL converted from Model3_ETH.compact.json; product=Model3; version=3.1.2; bus=eth; not an authoritative vehicle definition";
CM_ SG_ 1665 RADC_udsResponseData "REFERENCE_OPTIONAL; source=Model3_ETH.compact.json; json_start_position=7; conversion_policy=LOCAL_DBC_START_BIT_ADAPTATION";
CM_ BO_ 257 "REFERENCE_OPTIONAL converted from Model3_ETH.compact.json; product=Model3; version=3.1.2; bus=eth; not an authoritative vehicle definition";
CM_ SG_ 257 RCM_rollRate "REFERENCE_OPTIONAL; source=Model3_ETH.compact.json; json_start_position=31; conversion_policy=JSON_DIRECT";
CM_ SG_ 257 RCM_pitchRate "REFERENCE_OPTIONAL; source=Model3_ETH.compact.json; json_start_position=16; conversion_policy=JSON_DIRECT";
CM_ SG_ 257 RCM_yawRate "REFERENCE_OPTIONAL; source=Model3_ETH.compact.json; json_start_position=0; conversion_policy=JSON_DIRECT";
CM_ BO_ 278 "REFERENCE_OPTIONAL converted from Model3_ETH.compact.json; product=Model3; version=3.1.2; bus=eth; not an authoritative vehicle definition";
CM_ SG_ 278 RCM_verticalAccel "REFERENCE_OPTIONAL; source=Model3_ETH.compact.json; json_start_position=32; conversion_policy=JSON_DIRECT";
CM_ SG_ 278 RCM_lateralAccel "REFERENCE_OPTIONAL; source=Model3_ETH.compact.json; json_start_position=16; conversion_policy=JSON_DIRECT";
CM_ SG_ 278 RCM_longitudinalAccel "REFERENCE_OPTIONAL; source=Model3_ETH.compact.json; json_start_position=0; conversion_policy=JSON_DIRECT";
CM_ BO_ 529 "REFERENCE_OPTIONAL converted from Model3_ETH.compact.json; product=Model3; version=3.1.2; bus=eth; not an authoritative vehicle definition";
CM_ SG_ 529 RCM_armStatus "REFERENCE_OPTIONAL; source=Model3_ETH.compact.json; json_start_position=12; conversion_policy=JSON_DIRECT";
CM_ BO_ 1617 "REFERENCE_OPTIONAL converted from Model3_ETH.compact.json; product=Model3; version=3.1.2; bus=eth; not an authoritative vehicle definition";
CM_ SG_ 1617 RCM_udsResponseData "REFERENCE_OPTIONAL; source=Model3_ETH.compact.json; json_start_position=7; conversion_policy=LOCAL_DBC_START_BIT_ADAPTATION";
CM_ BO_ 297 "REFERENCE_OPTIONAL converted from Model3_ETH.compact.json; product=Model3; version=3.1.2; bus=eth; not an authoritative vehicle definition";
CM_ SG_ 297 SCCM_steeringAngle "REFERENCE_OPTIONAL; source=Model3_ETH.compact.json; json_start_position=16; conversion_policy=JSON_DIRECT";
CM_ BO_ 1680 "REFERENCE_OPTIONAL converted from Model3_ETH.compact.json; product=Model3; version=3.1.2; bus=eth; not an authoritative vehicle definition";
CM_ SG_ 1680 SCCM_functionalResponseData_7 "REFERENCE_OPTIONAL; source=Model3_ETH.compact.json; json_start_position=63; conversion_policy=LOCAL_DBC_START_BIT_ADAPTATION";
CM_ SG_ 1680 SCCM_functionalResponseData_6 "REFERENCE_OPTIONAL; source=Model3_ETH.compact.json; json_start_position=55; conversion_policy=LOCAL_DBC_START_BIT_ADAPTATION";
CM_ SG_ 1680 SCCM_functionalResponseData_5 "REFERENCE_OPTIONAL; source=Model3_ETH.compact.json; json_start_position=47; conversion_policy=LOCAL_DBC_START_BIT_ADAPTATION";
CM_ SG_ 1680 SCCM_functionalResponseData_4 "REFERENCE_OPTIONAL; source=Model3_ETH.compact.json; json_start_position=39; conversion_policy=LOCAL_DBC_START_BIT_ADAPTATION";
CM_ SG_ 1680 SCCM_functionalResponseData_3 "REFERENCE_OPTIONAL; source=Model3_ETH.compact.json; json_start_position=31; conversion_policy=LOCAL_DBC_START_BIT_ADAPTATION";
CM_ SG_ 1680 SCCM_functionalResponseData_2 "REFERENCE_OPTIONAL; source=Model3_ETH.compact.json; json_start_position=23; conversion_policy=LOCAL_DBC_START_BIT_ADAPTATION";
CM_ SG_ 1680 SCCM_functionalResponseData_1 "REFERENCE_OPTIONAL; source=Model3_ETH.compact.json; json_start_position=15; conversion_policy=LOCAL_DBC_START_BIT_ADAPTATION";
CM_ SG_ 1680 SCCM_functionalResponseData_0 "REFERENCE_OPTIONAL; source=Model3_ETH.compact.json; json_start_position=7; conversion_policy=LOCAL_DBC_START_BIT_ADAPTATION";
CM_ BO_ 1787 "REFERENCE_OPTIONAL converted from Model3_ETH.compact.json; product=Model3; version=3.1.2; bus=eth; not an authoritative vehicle definition";
CM_ SG_ 1787 SDCR_udsResponseData "REFERENCE_OPTIONAL; source=Model3_ETH.compact.json; json_start_position=7; conversion_policy=JSON_BIG_ENDIAN_UNVERIFIED_START";
CM_ BO_ 1627 "REFERENCE_OPTIONAL converted from Model3_ETH.compact.json; product=Model3; version=3.1.2; bus=eth; not an authoritative vehicle definition";
CM_ SG_ 1627 TAS_udsResponseData "REFERENCE_OPTIONAL; source=Model3_ETH.compact.json; json_start_position=7; conversion_policy=LOCAL_DBC_START_BIT_ADAPTATION";
CM_ BO_ 1631 "REFERENCE_OPTIONAL converted from Model3_ETH.compact.json; product=Model3; version=3.1.2; bus=eth; not an authoritative vehicle definition";
CM_ SG_ 1631 TPMS_udsResponseData "REFERENCE_OPTIONAL; source=Model3_ETH.compact.json; json_start_position=7; conversion_policy=LOCAL_DBC_START_BIT_ADAPTATION";
CM_ BO_ 1641 "REFERENCE_OPTIONAL converted from Model3_ETH.compact.json; product=Model3; version=3.1.2; bus=eth; not an authoritative vehicle definition";
CM_ SG_ 1641 UDS_KOSTIAsccmRequestData "REFERENCE_OPTIONAL; source=Model3_ETH.compact.json; json_start_position=7; conversion_policy=LOCAL_DBC_START_BIT_ADAPTATION";
CM_ BO_ 1538 "REFERENCE_OPTIONAL converted from Model3_ETH.compact.json; product=Model3; version=3.1.2; bus=eth; not an authoritative vehicle definition";
CM_ SG_ 1538 UDS_bmsRequestData "REFERENCE_OPTIONAL; source=Model3_ETH.compact.json; json_start_position=7; conversion_policy=LOCAL_DBC_START_BIT_ADAPTATION";
CM_ BO_ 1579 "REFERENCE_OPTIONAL converted from Model3_ETH.compact.json; product=Model3; version=3.1.2; bus=eth; not an authoritative vehicle definition";
CM_ SG_ 1579 UDS_ccRequestData "REFERENCE_OPTIONAL; source=Model3_ETH.compact.json; json_start_position=7; conversion_policy=LOCAL_DBC_START_BIT_ADAPTATION";
CM_ BO_ 1539 "REFERENCE_OPTIONAL converted from Model3_ETH.compact.json; product=Model3; version=3.1.2; bus=eth; not an authoritative vehicle definition";
CM_ SG_ 1539 UDS_cmpRequestData "REFERENCE_OPTIONAL; source=Model3_ETH.compact.json; json_start_position=7; conversion_policy=LOCAL_DBC_START_BIT_ADAPTATION";
CM_ BO_ 1543 "REFERENCE_OPTIONAL converted from Model3_ETH.compact.json; product=Model3; version=3.1.2; bus=eth; not an authoritative vehicle definition";
CM_ SG_ 1543 UDS_cmpdRequestData "REFERENCE_OPTIONAL; source=Model3_ETH.compact.json; json_start_position=7; conversion_policy=JSON_BIG_ENDIAN_UNVERIFIED_START";
CM_ BO_ 1550 "REFERENCE_OPTIONAL converted from Model3_ETH.compact.json; product=Model3; version=3.1.2; bus=eth; not an authoritative vehicle definition";
CM_ SG_ 1550 UDS_cpRequestData "REFERENCE_OPTIONAL; source=Model3_ETH.compact.json; json_start_position=7; conversion_policy=LOCAL_DBC_START_BIT_ADAPTATION";
CM_ BO_ 1609 "REFERENCE_OPTIONAL converted from Model3_ETH.compact.json; product=Model3; version=3.1.2; bus=eth; not an authoritative vehicle definition";
CM_ SG_ 1609 UDS_dasRequestData "REFERENCE_OPTIONAL; source=Model3_ETH.compact.json; json_start_position=7; conversion_policy=LOCAL_DBC_START_BIT_ADAPTATION";
CM_ BO_ 1589 "REFERENCE_OPTIONAL converted from Model3_ETH.compact.json; product=Model3; version=3.1.2; bus=eth; not an authoritative vehicle definition";
CM_ SG_ 1589 UDS_diRequestData "REFERENCE_OPTIONAL; source=Model3_ETH.compact.json; json_start_position=7; conversion_policy=JSON_BIG_ENDIAN_UNVERIFIED_START";
CM_ BO_ 1541 "REFERENCE_OPTIONAL converted from Model3_ETH.compact.json; product=Model3; version=3.1.2; bus=eth; not an authoritative vehicle definition";
CM_ SG_ 1541 UDS_difRequestData "REFERENCE_OPTIONAL; source=Model3_ETH.compact.json; json_start_position=7; conversion_policy=JSON_BIG_ENDIAN_UNVERIFIED_START";
CM_ BO_ 1542 "REFERENCE_OPTIONAL converted from Model3_ETH.compact.json; product=Model3; version=3.1.2; bus=eth; not an authoritative vehicle definition";
CM_ SG_ 1542 UDS_dirRequestData "REFERENCE_OPTIONAL; source=Model3_ETH.compact.json; json_start_position=7; conversion_policy=JSON_BIG_ENDIAN_UNVERIFIED_START";
CM_ BO_ 1584 "REFERENCE_OPTIONAL converted from Model3_ETH.compact.json; product=Model3; version=3.1.2; bus=eth; not an authoritative vehicle definition";
CM_ SG_ 1584 UDS_epas3pRequestData "REFERENCE_OPTIONAL; source=Model3_ETH.compact.json; json_start_position=7; conversion_policy=LOCAL_DBC_START_BIT_ADAPTATION";
CM_ BO_ 1840 "REFERENCE_OPTIONAL converted from Model3_ETH.compact.json; product=Model3; version=3.1.2; bus=eth; not an authoritative vehicle definition";
CM_ SG_ 1840 UDS_epas3sRequestData "REFERENCE_OPTIONAL; source=Model3_ETH.compact.json; json_start_position=7; conversion_policy=LOCAL_DBC_START_BIT_ADAPTATION";
CM_ BO_ 1572 "REFERENCE_OPTIONAL converted from Model3_ETH.compact.json; product=Model3; version=3.1.2; bus=eth; not an authoritative vehicle definition";
CM_ SG_ 1572 UDS_epblRequestData_L "REFERENCE_OPTIONAL; source=Model3_ETH.compact.json; json_start_position=39; conversion_policy=LOCAL_DBC_START_BIT_ADAPTATION";
CM_ SG_ 1572 UDS_epblRequestData_H "REFERENCE_OPTIONAL; source=Model3_ETH.compact.json; json_start_position=7; conversion_policy=LOCAL_DBC_START_BIT_ADAPTATION";
CM_ BO_ 1574 "REFERENCE_OPTIONAL converted from Model3_ETH.compact.json; product=Model3; version=3.1.2; bus=eth; not an authoritative vehicle definition";
CM_ SG_ 1574 UDS_epbrRequestData_L "REFERENCE_OPTIONAL; source=Model3_ETH.compact.json; json_start_position=39; conversion_policy=LOCAL_DBC_START_BIT_ADAPTATION";
CM_ SG_ 1574 UDS_epbrRequestData_H "REFERENCE_OPTIONAL; source=Model3_ETH.compact.json; json_start_position=7; conversion_policy=LOCAL_DBC_START_BIT_ADAPTATION";
CM_ BO_ 1605 "REFERENCE_OPTIONAL converted from Model3_ETH.compact.json; product=Model3; version=3.1.2; bus=eth; not an authoritative vehicle definition";
CM_ SG_ 1605 UDS_espRequestData "REFERENCE_OPTIONAL; source=Model3_ETH.compact.json; json_start_position=7; conversion_policy=LOCAL_DBC_START_BIT_ADAPTATION";
CM_ BO_ 2015 "REFERENCE_OPTIONAL converted from Model3_ETH.compact.json; product=Model3; version=3.1.2; bus=eth; not an authoritative vehicle definition";
CM_ SG_ 2015 UDS_functionalRequestData_7 "REFERENCE_OPTIONAL; source=Model3_ETH.compact.json; json_start_position=63; conversion_policy=LOCAL_DBC_START_BIT_ADAPTATION";
CM_ SG_ 2015 UDS_functionalRequestData_6 "REFERENCE_OPTIONAL; source=Model3_ETH.compact.json; json_start_position=55; conversion_policy=LOCAL_DBC_START_BIT_ADAPTATION";
CM_ SG_ 2015 UDS_functionalRequestData_5 "REFERENCE_OPTIONAL; source=Model3_ETH.compact.json; json_start_position=47; conversion_policy=LOCAL_DBC_START_BIT_ADAPTATION";
CM_ SG_ 2015 UDS_functionalRequestData_4 "REFERENCE_OPTIONAL; source=Model3_ETH.compact.json; json_start_position=39; conversion_policy=LOCAL_DBC_START_BIT_ADAPTATION";
CM_ SG_ 2015 UDS_functionalRequestData_3 "REFERENCE_OPTIONAL; source=Model3_ETH.compact.json; json_start_position=31; conversion_policy=LOCAL_DBC_START_BIT_ADAPTATION";
CM_ SG_ 2015 UDS_functionalRequestData_2 "REFERENCE_OPTIONAL; source=Model3_ETH.compact.json; json_start_position=23; conversion_policy=LOCAL_DBC_START_BIT_ADAPTATION";
CM_ SG_ 2015 UDS_functionalRequestData_1 "REFERENCE_OPTIONAL; source=Model3_ETH.compact.json; json_start_position=15; conversion_policy=LOCAL_DBC_START_BIT_ADAPTATION";
CM_ SG_ 2015 UDS_functionalRequestData_0 "REFERENCE_OPTIONAL; source=Model3_ETH.compact.json; json_start_position=7; conversion_policy=LOCAL_DBC_START_BIT_ADAPTATION";
CM_ BO_ 2014 "REFERENCE_OPTIONAL converted from Model3_ETH.compact.json; product=Model3; version=3.1.2; bus=eth; not an authoritative vehicle definition";
CM_ SG_ 2014 UDS_functionalRequestDataCH "REFERENCE_OPTIONAL; source=Model3_ETH.compact.json; json_start_position=7; conversion_policy=JSON_BIG_ENDIAN_UNVERIFIED_START";
CM_ BO_ 1552 "REFERENCE_OPTIONAL converted from Model3_ETH.compact.json; product=Model3; version=3.1.2; bus=eth; not an authoritative vehicle definition";
CM_ SG_ 1552 UDS_hvpRequestData "REFERENCE_OPTIONAL; source=Model3_ETH.compact.json; json_start_position=7; conversion_policy=LOCAL_DBC_START_BIT_ADAPTATION";
CM_ BO_ 1613 "REFERENCE_OPTIONAL converted from Model3_ETH.compact.json; product=Model3; version=3.1.2; bus=eth; not an authoritative vehicle definition";
CM_ SG_ 1613 UDS_ibstRequestData "REFERENCE_OPTIONAL; source=Model3_ETH.compact.json; json_start_position=7; conversion_policy=LOCAL_DBC_START_BIT_ADAPTATION";
CM_ BO_ 1560 "REFERENCE_OPTIONAL converted from Model3_ETH.compact.json; product=Model3; version=3.1.2; bus=eth; not an authoritative vehicle definition";
CM_ SG_ 1560 UDS_icrRequestData "REFERENCE_OPTIONAL; source=Model3_ETH.compact.json; json_start_position=7; conversion_policy=JSON_BIG_ENDIAN_UNVERIFIED_START";
CM_ BO_ 1603 "REFERENCE_OPTIONAL converted from Model3_ETH.compact.json; product=Model3; version=3.1.2; bus=eth; not an authoritative vehicle definition";
CM_ SG_ 1603 UDS_ocs1pRequestData "REFERENCE_OPTIONAL; source=Model3_ETH.compact.json; json_start_position=7; conversion_policy=LOCAL_DBC_START_BIT_ADAPTATION";
CM_ BO_ 1614 "REFERENCE_OPTIONAL converted from Model3_ETH.compact.json; product=Model3; version=3.1.2; bus=eth; not an authoritative vehicle definition";
CM_ SG_ 1614 UDS_parkRequestData "REFERENCE_OPTIONAL; source=Model3_ETH.compact.json; json_start_position=7; conversion_policy=LOCAL_DBC_START_BIT_ADAPTATION";
CM_ BO_ 1576 "REFERENCE_OPTIONAL converted from Model3_ETH.compact.json; product=Model3; version=3.1.2; bus=eth; not an authoritative vehicle definition";
CM_ SG_ 1576 UDS_pcsRequestData "REFERENCE_OPTIONAL; source=Model3_ETH.compact.json; json_start_position=7; conversion_policy=LOCAL_DBC_START_BIT_ADAPTATION";
CM_ BO_ 1634 "REFERENCE_OPTIONAL converted from Model3_ETH.compact.json; product=Model3; version=3.1.2; bus=eth; not an authoritative vehicle definition";
CM_ SG_ 1634 UDS_plgRequestData "REFERENCE_OPTIONAL; source=Model3_ETH.compact.json; json_start_position=7; conversion_policy=JSON_BIG_ENDIAN_UNVERIFIED_START";
CM_ BO_ 1568 "REFERENCE_OPTIONAL converted from Model3_ETH.compact.json; product=Model3; version=3.1.2; bus=eth; not an authoritative vehicle definition";
CM_ SG_ 1568 UDS_pmRequestData "REFERENCE_OPTIONAL; source=Model3_ETH.compact.json; json_start_position=7; conversion_policy=JSON_BIG_ENDIAN_UNVERIFIED_START";
CM_ BO_ 1604 "REFERENCE_OPTIONAL converted from Model3_ETH.compact.json; product=Model3; version=3.1.2; bus=eth; not an authoritative vehicle definition";
CM_ SG_ 1604 UDS_pmfRequestData "REFERENCE_OPTIONAL; source=Model3_ETH.compact.json; json_start_position=7; conversion_policy=JSON_BIG_ENDIAN_UNVERIFIED_START";
CM_ BO_ 1540 "REFERENCE_OPTIONAL converted from Model3_ETH.compact.json; product=Model3; version=3.1.2; bus=eth; not an authoritative vehicle definition";
CM_ SG_ 1540 UDS_pmrRequestData "REFERENCE_OPTIONAL; source=Model3_ETH.compact.json; json_start_position=7; conversion_policy=JSON_BIG_ENDIAN_UNVERIFIED_START";
CM_ BO_ 1734 "REFERENCE_OPTIONAL converted from Model3_ETH.compact.json; product=Model3; version=3.1.2; bus=eth; not an authoritative vehicle definition";
CM_ SG_ 1734 UDS_ptcRequestData "REFERENCE_OPTIONAL; source=Model3_ETH.compact.json; json_start_position=7; conversion_policy=LOCAL_DBC_START_BIT_ADAPTATION";
CM_ BO_ 1649 "REFERENCE_OPTIONAL converted from Model3_ETH.compact.json; product=Model3; version=3.1.2; bus=eth; not an authoritative vehicle definition";
CM_ SG_ 1649 UDS_radcRequestData "REFERENCE_OPTIONAL; source=Model3_ETH.compact.json; json_start_position=7; conversion_policy=LOCAL_DBC_START_BIT_ADAPTATION";
CM_ BO_ 1601 "REFERENCE_OPTIONAL converted from Model3_ETH.compact.json; product=Model3; version=3.1.2; bus=eth; not an authoritative vehicle definition";
CM_ SG_ 1601 UDS_rcmRequestData "REFERENCE_OPTIONAL; source=Model3_ETH.compact.json; json_start_position=7; conversion_policy=LOCAL_DBC_START_BIT_ADAPTATION";
CM_ BO_ 1664 "REFERENCE_OPTIONAL converted from Model3_ETH.compact.json; product=Model3; version=3.1.2; bus=eth; not an authoritative vehicle definition";
CM_ SG_ 1664 UDS_sccmRequestData "REFERENCE_OPTIONAL; source=Model3_ETH.compact.json; json_start_position=7; conversion_policy=LOCAL_DBC_START_BIT_ADAPTATION";
CM_ BO_ 1723 "REFERENCE_OPTIONAL converted from Model3_ETH.compact.json; product=Model3; version=3.1.2; bus=eth; not an authoritative vehicle definition";
CM_ SG_ 1723 UDS_sdcrRequestData "REFERENCE_OPTIONAL; source=Model3_ETH.compact.json; json_start_position=7; conversion_policy=JSON_BIG_ENDIAN_UNVERIFIED_START";
CM_ BO_ 1611 "REFERENCE_OPTIONAL converted from Model3_ETH.compact.json; product=Model3; version=3.1.2; bus=eth; not an authoritative vehicle definition";
CM_ SG_ 1611 UDS_tasRequestData "REFERENCE_OPTIONAL; source=Model3_ETH.compact.json; json_start_position=7; conversion_policy=LOCAL_DBC_START_BIT_ADAPTATION";
CM_ BO_ 1551 "REFERENCE_OPTIONAL converted from Model3_ETH.compact.json; product=Model3; version=3.1.2; bus=eth; not an authoritative vehicle definition";
CM_ SG_ 1551 UDS_thcRequestData_L "REFERENCE_OPTIONAL; source=Model3_ETH.compact.json; json_start_position=39; conversion_policy=LOCAL_DBC_START_BIT_ADAPTATION";
CM_ SG_ 1551 UDS_thcRequestData_H "REFERENCE_OPTIONAL; source=Model3_ETH.compact.json; json_start_position=7; conversion_policy=LOCAL_DBC_START_BIT_ADAPTATION";
CM_ BO_ 1615 "REFERENCE_OPTIONAL converted from Model3_ETH.compact.json; product=Model3; version=3.1.2; bus=eth; not an authoritative vehicle definition";
CM_ SG_ 1615 UDS_tpmsRequestData "REFERENCE_OPTIONAL; source=Model3_ETH.compact.json; json_start_position=7; conversion_policy=LOCAL_DBC_START_BIT_ADAPTATION";
CM_ BO_ 1536 "REFERENCE_OPTIONAL converted from Model3_ETH.compact.json; product=Model3; version=3.1.2; bus=eth; not an authoritative vehicle definition";
CM_ SG_ 1536 UDS_vcfrontRequestData "REFERENCE_OPTIONAL; source=Model3_ETH.compact.json; json_start_position=7; conversion_policy=LOCAL_DBC_START_BIT_ADAPTATION";
CM_ BO_ 1570 "REFERENCE_OPTIONAL converted from Model3_ETH.compact.json; product=Model3; version=3.1.2; bus=eth; not an authoritative vehicle definition";
CM_ SG_ 1570 UDS_vcleftRequestData_L "REFERENCE_OPTIONAL; source=Model3_ETH.compact.json; json_start_position=39; conversion_policy=LOCAL_DBC_START_BIT_ADAPTATION";
CM_ SG_ 1570 UDS_vcleftRequestData_H "REFERENCE_OPTIONAL; source=Model3_ETH.compact.json; json_start_position=7; conversion_policy=LOCAL_DBC_START_BIT_ADAPTATION";
CM_ BO_ 1544 "REFERENCE_OPTIONAL converted from Model3_ETH.compact.json; product=Model3; version=3.1.2; bus=eth; not an authoritative vehicle definition";
CM_ SG_ 1544 UDS_vcrightRequestData_L "REFERENCE_OPTIONAL; source=Model3_ETH.compact.json; json_start_position=39; conversion_policy=LOCAL_DBC_START_BIT_ADAPTATION";
CM_ SG_ 1544 UDS_vcrightRequestData_H "REFERENCE_OPTIONAL; source=Model3_ETH.compact.json; json_start_position=7; conversion_policy=LOCAL_DBC_START_BIT_ADAPTATION";
CM_ BO_ 1546 "REFERENCE_OPTIONAL converted from Model3_ETH.compact.json; product=Model3; version=3.1.2; bus=eth; not an authoritative vehicle definition";
CM_ SG_ 1546 UDS_vcsecRequestData "REFERENCE_OPTIONAL; source=Model3_ETH.compact.json; json_start_position=7; conversion_policy=LOCAL_DBC_START_BIT_ADAPTATION";
CM_ BO_ 1056 "REFERENCE_OPTIONAL converted from Model3_ETH.compact.json; product=Model3; version=3.1.2; bus=eth; not an authoritative vehicle definition";
CM_ SG_ 1056 UIS_odincefMemUsage "REFERENCE_OPTIONAL; source=Model3_ETH.compact.json; json_start_position=32; conversion_policy=JSON_DIRECT";
CM_ SG_ 1056 UIS_odincefCPUUsage "REFERENCE_OPTIONAL; source=Model3_ETH.compact.json; json_start_position=32; conversion_policy=JSON_DIRECT";
CM_ SG_ 1056 UIS_odinStatusCmdResult "REFERENCE_OPTIONAL; source=Model3_ETH.compact.json; json_start_position=32; conversion_policy=JSON_DIRECT";
CM_ SG_ 1056 UIS_odinStatusCmdDurationMs "REFERENCE_OPTIONAL; source=Model3_ETH.compact.json; json_start_position=32; conversion_policy=JSON_DIRECT";
CM_ SG_ 1056 UIS_odinProcessState "REFERENCE_OPTIONAL; source=Model3_ETH.compact.json; json_start_position=32; conversion_policy=JSON_DIRECT";
CM_ SG_ 1056 UIS_odinOrchestratorStartCount "REFERENCE_OPTIONAL; source=Model3_ETH.compact.json; json_start_position=32; conversion_policy=JSON_DIRECT";
CM_ SG_ 1056 UIS_odinOrchestratorFailCount "REFERENCE_OPTIONAL; source=Model3_ETH.compact.json; json_start_position=32; conversion_policy=JSON_DIRECT";
CM_ SG_ 1056 UIS_odinNetworkStartCount "REFERENCE_OPTIONAL; source=Model3_ETH.compact.json; json_start_position=32; conversion_policy=JSON_DIRECT";
CM_ SG_ 1056 UIS_odinNetworkFailCount "REFERENCE_OPTIONAL; source=Model3_ETH.compact.json; json_start_position=32; conversion_policy=JSON_DIRECT";
CM_ SG_ 1056 UIS_odinMemUsage "REFERENCE_OPTIONAL; source=Model3_ETH.compact.json; json_start_position=32; conversion_policy=JSON_DIRECT";
CM_ SG_ 1056 UIS_odinListTasksCmdResult "REFERENCE_OPTIONAL; source=Model3_ETH.compact.json; json_start_position=32; conversion_policy=JSON_DIRECT";
CM_ SG_ 1056 UIS_odinListTasksCmdDurationMs "REFERENCE_OPTIONAL; source=Model3_ETH.compact.json; json_start_position=32; conversion_policy=JSON_DIRECT";
CM_ SG_ 1056 UIS_odinHermesConnectionState "REFERENCE_OPTIONAL; source=Model3_ETH.compact.json; json_start_position=32; conversion_policy=JSON_DIRECT";
CM_ SG_ 1056 UIS_odinGatewayConnectionState "REFERENCE_OPTIONAL; source=Model3_ETH.compact.json; json_start_position=32; conversion_policy=JSON_DIRECT";
CM_ SG_ 1056 UIS_odinCPUUsage "REFERENCE_OPTIONAL; source=Model3_ETH.compact.json; json_start_position=32; conversion_policy=JSON_DIRECT";
CM_ SG_ 1056 UIS_odinAuthFailCount "REFERENCE_OPTIONAL; source=Model3_ETH.compact.json; json_start_position=32; conversion_policy=JSON_DIRECT";
CM_ SG_ 1056 UIS_odinAuthCount "REFERENCE_OPTIONAL; source=Model3_ETH.compact.json; json_start_position=32; conversion_policy=JSON_DIRECT";
CM_ SG_ 1056 UIS_amdSocPkgPower "REFERENCE_OPTIONAL; source=Model3_ETH.compact.json; json_start_position=32; conversion_policy=JSON_DIRECT";
CM_ SG_ 1056 UIS_logMux "REFERENCE_OPTIONAL; source=Model3_ETH.compact.json; json_start_position=0; conversion_policy=JSON_DIRECT";
CM_ BO_ 545 "REFERENCE_OPTIONAL converted from Model3_ETH.compact.json; product=Model3; version=3.1.2; bus=eth; not an authoritative vehicle definition";
CM_ SG_ 545 VCFRONT_dirLVRequest "REFERENCE_OPTIONAL; source=Model3_ETH.compact.json; json_start_position=34; conversion_policy=JSON_DIRECT";
CM_ SG_ 545 VCFRONT_vehiclePowerState "REFERENCE_OPTIONAL; source=Model3_ETH.compact.json; json_start_position=5; conversion_policy=JSON_DIRECT";
CM_ SG_ 545 VCFRONT_LVPowerStateIndex "REFERENCE_OPTIONAL; source=Model3_ETH.compact.json; json_start_position=0; conversion_policy=JSON_DIRECT";
CM_ BO_ 832 "REFERENCE_OPTIONAL converted from Model3_ETH.compact.json; product=Model3; version=3.1.2; bus=eth; not an authoritative vehicle definition";
CM_ SG_ 832 VCFRONT_a356_refrigSysLockout "REFERENCE_OPTIONAL; source=Model3_ETH.compact.json; json_start_position=59; conversion_policy=JSON_DIRECT";
CM_ SG_ 832 VCFRONT_a355_coolantSysLockout "REFERENCE_OPTIONAL; source=Model3_ETH.compact.json; json_start_position=58; conversion_policy=JSON_DIRECT";
CM_ SG_ 832 VCFRONT_a208_brakeFluidLow "REFERENCE_OPTIONAL; source=Model3_ETH.compact.json; json_start_position=31; conversion_policy=JSON_DIRECT";
CM_ SG_ 832 VCFRONT_a199_PRVCANUndertrminate "REFERENCE_OPTIONAL; source=Model3_ETH.compact.json; json_start_position=22; conversion_policy=JSON_DIRECT";
CM_ SG_ 832 VCFRONT_a128_vcrightEFuseTrip "REFERENCE_OPTIONAL; source=Model3_ETH.compact.json; json_start_position=11; conversion_policy=JSON_DIRECT";
CM_ SG_ 832 VCFRONT_a127_vcleftEFuseTrip "REFERENCE_OPTIONAL; source=Model3_ETH.compact.json; json_start_position=10; conversion_policy=JSON_DIRECT";
CM_ SG_ 832 VCFRONT_matrixIndex "REFERENCE_OPTIONAL; source=Model3_ETH.compact.json; json_start_position=0; conversion_policy=JSON_DIRECT";
CM_ BO_ 1014 "REFERENCE_OPTIONAL converted from Model3_ETH.compact.json; product=Model3; version=3.1.2; bus=eth; not an authoritative vehicle definition";
CM_ SG_ 1014 VCFRONT_turnSignalRightStatus "REFERENCE_OPTIONAL; source=Model3_ETH.compact.json; json_start_position=24; conversion_policy=JSON_DIRECT";
CM_ SG_ 1014 VCFRONT_turnSignalLeftStatus "REFERENCE_OPTIONAL; source=Model3_ETH.compact.json; json_start_position=22; conversion_policy=JSON_DIRECT";
CM_ BO_ 897 "REFERENCE_OPTIONAL converted from Model3_ETH.compact.json; product=Model3; version=3.1.2; bus=eth; not an authoritative vehicle definition";
CM_ SG_ 897 VCFRONT_radiatorFanRPMTarget "REFERENCE_OPTIONAL; source=Model3_ETH.compact.json; json_start_position=51; conversion_policy=JSON_DIRECT";
CM_ SG_ 897 VCFRONT_currentHorizPositionHCMR "REFERENCE_OPTIONAL; source=Model3_ETH.compact.json; json_start_position=36; conversion_policy=JSON_DIRECT";
CM_ SG_ 897 VCFRONT_pumpPowertrainRPMTarget "REFERENCE_OPTIONAL; source=Model3_ETH.compact.json; json_start_position=35; conversion_policy=JSON_DIRECT";
CM_ SG_ 897 VCFRONT_currentHorizPositionHCML "REFERENCE_OPTIONAL; source=Model3_ETH.compact.json; json_start_position=26; conversion_policy=JSON_DIRECT";
CM_ SG_ 897 VCFRONT_logging1HzIndex "REFERENCE_OPTIONAL; source=Model3_ETH.compact.json; json_start_position=0; conversion_policy=JSON_DIRECT";
CM_ BO_ 513 "REFERENCE_OPTIONAL converted from Model3_ETH.compact.json; product=Model3; version=3.1.2; bus=eth; not an authoritative vehicle definition";
CM_ SG_ 513 VCFRONT_activeLouverOpenPos "REFERENCE_OPTIONAL; source=Model3_ETH.compact.json; json_start_position=47; conversion_policy=JSON_DIRECT";
CM_ SG_ 513 VCFRONT_coolantValveMode "REFERENCE_OPTIONAL; source=Model3_ETH.compact.json; json_start_position=32; conversion_policy=JSON_DIRECT";
CM_ SG_ 513 VCFRONT_radiatorFanRPMActual "REFERENCE_OPTIONAL; source=Model3_ETH.compact.json; json_start_position=24; conversion_policy=JSON_DIRECT";
CM_ SG_ 513 VCFRONT_pumpPowertrainRPMActual "REFERENCE_OPTIONAL; source=Model3_ETH.compact.json; json_start_position=16; conversion_policy=JSON_DIRECT";
CM_ SG_ 513 VCFRONT_loggingAndVitals10HzInde "REFERENCE_OPTIONAL; source=Model3_ETH.compact.json; json_start_position=0; conversion_policy=JSON_DIRECT";
CM_ BO_ 801 "REFERENCE_OPTIONAL converted from Model3_ETH.compact.json; product=Model3; version=3.1.2; bus=eth; not an authoritative vehicle definition";
CM_ SG_ 801 VCFRONT_tempCoolantPTInlet "REFERENCE_OPTIONAL; source=Model3_ETH.compact.json; json_start_position=10; conversion_policy=JSON_DIRECT";
CM_ SG_ 801 VCFRONT_tempCoolantBatInlet "REFERENCE_OPTIONAL; source=Model3_ETH.compact.json; json_start_position=0; conversion_policy=JSON_DIRECT";
CM_ BO_ 737 "REFERENCE_OPTIONAL converted from Model3_ETH.compact.json; product=Model3; version=3.1.2; bus=eth; not an authoritative vehicle definition";
CM_ SG_ 737 VCFRONT_refrigFillRoutineStatus "REFERENCE_OPTIONAL; source=Model3_ETH.compact.json; json_start_position=54; conversion_policy=JSON_DIRECT";
CM_ SG_ 737 VCFRONT_coolantFillRoutineStatus "REFERENCE_OPTIONAL; source=Model3_ETH.compact.json; json_start_position=52; conversion_policy=JSON_DIRECT";
CM_ SG_ 737 VCFRONT_anyClosureOpen "REFERENCE_OPTIONAL; source=Model3_ETH.compact.json; json_start_position=49; conversion_policy=JSON_DIRECT";
CM_ SG_ 737 VCFRONT_frunkLatchStatus "REFERENCE_OPTIONAL; source=Model3_ETH.compact.json; json_start_position=3; conversion_policy=JSON_DIRECT";
CM_ SG_ 737 VCFRONT_statusIndex "REFERENCE_OPTIONAL; source=Model3_ETH.compact.json; json_start_position=0; conversion_policy=JSON_DIRECT";
CM_ BO_ 1537 "REFERENCE_OPTIONAL converted from Model3_ETH.compact.json; product=Model3; version=3.1.2; bus=eth; not an authoritative vehicle definition";
CM_ SG_ 1537 VCFRONT_udsResponseData "REFERENCE_OPTIONAL; source=Model3_ETH.compact.json; json_start_position=7; conversion_policy=LOCAL_DBC_START_BIT_ADAPTATION";
CM_ BO_ 864 "REFERENCE_OPTIONAL converted from Model3_ETH.compact.json; product=Model3; version=3.1.2; bus=eth; not an authoritative vehicle definition";
CM_ SG_ 864 VCLEFT_a254_seatUncalLift "REFERENCE_OPTIONAL; source=Model3_ETH.compact.json; json_start_position=17; conversion_policy=JSON_DIRECT";
CM_ SG_ 864 VCLEFT_a253_seatUncalTilt "REFERENCE_OPTIONAL; source=Model3_ETH.compact.json; json_start_position=16; conversion_policy=JSON_DIRECT";
CM_ SG_ 864 VCLEFT_a252_seatUncalBack "REFERENCE_OPTIONAL; source=Model3_ETH.compact.json; json_start_position=15; conversion_policy=JSON_DIRECT";
CM_ SG_ 864 VCLEFT_a251_seatUncalTrack "REFERENCE_OPTIONAL; source=Model3_ETH.compact.json; json_start_position=14; conversion_policy=JSON_DIRECT";
CM_ SG_ 864 VCLEFT_a307_handleDisconnectedR "REFERENCE_OPTIONAL; source=Model3_ETH.compact.json; json_start_position=10; conversion_policy=JSON_DIRECT";
CM_ SG_ 864 VCLEFT_a306_handleDisconnectedF "REFERENCE_OPTIONAL; source=Model3_ETH.compact.json; json_start_position=9; conversion_policy=JSON_DIRECT";
CM_ SG_ 864 VCLEFT_matrixIndex "REFERENCE_OPTIONAL; source=Model3_ETH.compact.json; json_start_position=0; conversion_policy=JSON_DIRECT";
CM_ BO_ 258 "REFERENCE_OPTIONAL converted from Model3_ETH.compact.json; product=Model3; version=3.1.2; bus=eth; not an authoritative vehicle definition";
CM_ SG_ 258 VCLEFT_rearLatchStatus "REFERENCE_OPTIONAL; source=Model3_ETH.compact.json; json_start_position=18; conversion_policy=JSON_DIRECT";
CM_ SG_ 258 VCLEFT_frontLatchStatus "REFERENCE_OPTIONAL; source=Model3_ETH.compact.json; json_start_position=14; conversion_policy=JSON_DIRECT";
CM_ BO_ 322 "REFERENCE_OPTIONAL converted from Model3_ETH.compact.json; product=Model3; version=3.1.2; bus=eth; not an authoritative vehicle definition";
CM_ SG_ 322 VCLEFT_liftgateState "REFERENCE_OPTIONAL; source=Model3_ETH.compact.json; json_start_position=3; conversion_policy=JSON_DIRECT";
CM_ SG_ 322 VCLEFT_liftgateStatusIndex "REFERENCE_OPTIONAL; source=Model3_ETH.compact.json; json_start_position=0; conversion_policy=JSON_DIRECT";
CM_ BO_ 727 "REFERENCE_OPTIONAL converted from Model3_ETH.compact.json; product=Model3; version=3.1.2; bus=eth; not an authoritative vehicle definition";
CM_ SG_ 727 VCLEFT_pitchEstimate "REFERENCE_OPTIONAL; source=Model3_ETH.compact.json; json_start_position=27; conversion_policy=JSON_DIRECT";
CM_ SG_ 727 VCLEFT_pitchEstimateArbitratedSt "REFERENCE_OPTIONAL; source=Model3_ETH.compact.json; json_start_position=8; conversion_policy=JSON_DIRECT";
CM_ SG_ 727 VCLEFT_pitchEstimateOKForAiming "REFERENCE_OPTIONAL; source=Model3_ETH.compact.json; json_start_position=7; conversion_policy=JSON_DIRECT";
CM_ BO_ 778 "REFERENCE_OPTIONAL converted from Model3_ETH.compact.json; product=Model3; version=3.1.2; bus=eth; not an authoritative vehicle definition";
CM_ SG_ 778 VCLEFT_rearRightOccupancyStatus "REFERENCE_OPTIONAL; source=Model3_ETH.compact.json; json_start_position=10; conversion_policy=JSON_DIRECT";
CM_ SG_ 778 VCLEFT_rearCenterOccupancyStatus "REFERENCE_OPTIONAL; source=Model3_ETH.compact.json; json_start_position=8; conversion_policy=JSON_DIRECT";
CM_ SG_ 778 VCLEFT_rearLeftOccupancyStatus "REFERENCE_OPTIONAL; source=Model3_ETH.compact.json; json_start_position=5; conversion_policy=JSON_DIRECT";
CM_ SG_ 778 VCLEFT_frontBuckleStatus "REFERENCE_OPTIONAL; source=Model3_ETH.compact.json; json_start_position=3; conversion_policy=JSON_DIRECT";
CM_ SG_ 778 VCLEFT_frontOccupancyStatus "REFERENCE_OPTIONAL; source=Model3_ETH.compact.json; json_start_position=0; conversion_policy=JSON_DIRECT";
CM_ BO_ 1250 "REFERENCE_OPTIONAL converted from Model3_ETH.compact.json; product=Model3; version=3.1.2; bus=eth; not an authoritative vehicle definition";
CM_ SG_ 1250 VCLEFT_frontSeatTrackPos "REFERENCE_OPTIONAL; source=Model3_ETH.compact.json; json_start_position=8; conversion_policy=JSON_DIRECT";
CM_ SG_ 1250 VCLEFT_frontSeatTiltPos "REFERENCE_OPTIONAL; source=Model3_ETH.compact.json; json_start_position=8; conversion_policy=JSON_DIRECT";
CM_ SG_ 1250 VCLEFT_frontSeatLiftPos "REFERENCE_OPTIONAL; source=Model3_ETH.compact.json; json_start_position=8; conversion_policy=JSON_DIRECT";
CM_ SG_ 1250 VCLEFT_frontSeatBackPos "REFERENCE_OPTIONAL; source=Model3_ETH.compact.json; json_start_position=8; conversion_policy=JSON_DIRECT";
CM_ SG_ 1250 VCLEFT_seatStatusIndex "REFERENCE_OPTIONAL; source=Model3_ETH.compact.json; json_start_position=0; conversion_policy=JSON_DIRECT";
CM_ BO_ 962 "REFERENCE_OPTIONAL converted from Model3_ETH.compact.json; product=Model3; version=3.1.2; bus=eth; not an authoritative vehicle definition";
CM_ SG_ 962 VCLEFT_rearCenterBuckleSwitch "REFERENCE_OPTIONAL; source=Model3_ETH.compact.json; json_start_position=62; conversion_policy=JSON_DIRECT";
CM_ SG_ 962 VCLEFT_rearRightOccupancySwitch "REFERENCE_OPTIONAL; source=Model3_ETH.compact.json; json_start_position=58; conversion_policy=JSON_DIRECT";
CM_ SG_ 962 VCLEFT_rearLeftOccupancySwitch "REFERENCE_OPTIONAL; source=Model3_ETH.compact.json; json_start_position=56; conversion_policy=JSON_DIRECT";
CM_ SG_ 962 VCLEFT_rearCenterOccupancySwitch "REFERENCE_OPTIONAL; source=Model3_ETH.compact.json; json_start_position=54; conversion_policy=JSON_DIRECT";
CM_ SG_ 962 VCLEFT_rearLeftBuckleSwitch "REFERENCE_OPTIONAL; source=Model3_ETH.compact.json; json_start_position=52; conversion_policy=JSON_DIRECT";
CM_ SG_ 962 VCLEFT_frontBuckleSwitch "REFERENCE_OPTIONAL; source=Model3_ETH.compact.json; json_start_position=48; conversion_policy=JSON_DIRECT";
CM_ SG_ 962 VCLEFT_hornSwitchPressed "REFERENCE_OPTIONAL; source=Model3_ETH.compact.json; json_start_position=2; conversion_policy=JSON_DIRECT";
CM_ SG_ 962 VCLEFT_switchStatusIndex "REFERENCE_OPTIONAL; source=Model3_ETH.compact.json; json_start_position=0; conversion_policy=JSON_DIRECT";
CM_ BO_ 1571 "REFERENCE_OPTIONAL converted from Model3_ETH.compact.json; product=Model3; version=3.1.2; bus=eth; not an authoritative vehicle definition";
CM_ SG_ 1571 VCLEFT_udsResponseData_L "REFERENCE_OPTIONAL; source=Model3_ETH.compact.json; json_start_position=39; conversion_policy=LOCAL_DBC_START_BIT_ADAPTATION";
CM_ SG_ 1571 VCLEFT_udsResponseData_H "REFERENCE_OPTIONAL; source=Model3_ETH.compact.json; json_start_position=7; conversion_policy=LOCAL_DBC_START_BIT_ADAPTATION";
CM_ BO_ 706 "REFERENCE_OPTIONAL converted from Model3_ETH.compact.json; product=Model3; version=3.1.2; bus=eth; not an authoritative vehicle definition";
CM_ SG_ 706 VCLEFT_windowCalibratedLR "REFERENCE_OPTIONAL; source=Model3_ETH.compact.json; json_start_position=63; conversion_policy=JSON_DIRECT";
CM_ SG_ 706 VCLEFT_windowPositionLR "REFERENCE_OPTIONAL; source=Model3_ETH.compact.json; json_start_position=54; conversion_policy=JSON_DIRECT";
CM_ SG_ 706 VCLEFT_windowCalibratedLF "REFERENCE_OPTIONAL; source=Model3_ETH.compact.json; json_start_position=32; conversion_policy=JSON_DIRECT";
CM_ SG_ 706 VCLEFT_windowPositionLF "REFERENCE_OPTIONAL; source=Model3_ETH.compact.json; json_start_position=22; conversion_policy=JSON_DIRECT";
CM_ SG_ 706 VCLEFT_windowStatusIndex "REFERENCE_OPTIONAL; source=Model3_ETH.compact.json; json_start_position=0; conversion_policy=JSON_DIRECT";
CM_ BO_ 960 "REFERENCE_OPTIONAL converted from Model3_ETH.compact.json; product=Model3; version=3.1.2; bus=eth; not an authoritative vehicle definition";
CM_ SG_ 960 VCRIGHT_a198_PRVCANOverterminate "REFERENCE_OPTIONAL; source=Model3_ETH.compact.json; json_start_position=21; conversion_policy=JSON_DIRECT";
CM_ SG_ 960 VCRIGHT_a196_VEHCANOverterminate "REFERENCE_OPTIONAL; source=Model3_ETH.compact.json; json_start_position=19; conversion_policy=JSON_DIRECT";
CM_ SG_ 960 VCRIGHT_a254_seatUncalLift "REFERENCE_OPTIONAL; source=Model3_ETH.compact.json; json_start_position=17; conversion_policy=JSON_DIRECT";
CM_ SG_ 960 VCRIGHT_a253_seatUncalTilt "REFERENCE_OPTIONAL; source=Model3_ETH.compact.json; json_start_position=16; conversion_policy=JSON_DIRECT";
CM_ SG_ 960 VCRIGHT_a252_seatUncalBack "REFERENCE_OPTIONAL; source=Model3_ETH.compact.json; json_start_position=15; conversion_policy=JSON_DIRECT";
CM_ SG_ 960 VCRIGHT_a251_seatUncalTrack "REFERENCE_OPTIONAL; source=Model3_ETH.compact.json; json_start_position=14; conversion_policy=JSON_DIRECT";
CM_ SG_ 960 VCRIGHT_a307_handleDisconnectedR "REFERENCE_OPTIONAL; source=Model3_ETH.compact.json; json_start_position=10; conversion_policy=JSON_DIRECT";
CM_ SG_ 960 VCRIGHT_a306_handleDisconnectedF "REFERENCE_OPTIONAL; source=Model3_ETH.compact.json; json_start_position=9; conversion_policy=JSON_DIRECT";
CM_ SG_ 960 VCRIGHT_matrixIndex "REFERENCE_OPTIONAL; source=Model3_ETH.compact.json; json_start_position=0; conversion_policy=JSON_DIRECT";
CM_ BO_ 259 "REFERENCE_OPTIONAL converted from Model3_ETH.compact.json; product=Model3; version=3.1.2; bus=eth; not an authoritative vehicle definition";
CM_ SG_ 259 VCRIGHT_trunkLatchStatus "REFERENCE_OPTIONAL; source=Model3_ETH.compact.json; json_start_position=56; conversion_policy=JSON_DIRECT";
CM_ SG_ 259 VCRIGHT_rearLatchStatus "REFERENCE_OPTIONAL; source=Model3_ETH.compact.json; json_start_position=18; conversion_policy=JSON_DIRECT";
CM_ SG_ 259 VCRIGHT_frontLatchStatus "REFERENCE_OPTIONAL; source=Model3_ETH.compact.json; json_start_position=14; conversion_policy=JSON_DIRECT";
CM_ BO_ 1251 "REFERENCE_OPTIONAL converted from Model3_ETH.compact.json; product=Model3; version=3.1.2; bus=eth; not an authoritative vehicle definition";
CM_ SG_ 1251 VCRIGHT_frontSeatTrackPos "REFERENCE_OPTIONAL; source=Model3_ETH.compact.json; json_start_position=8; conversion_policy=JSON_DIRECT";
CM_ SG_ 1251 VCRIGHT_frontSeatTiltPos "REFERENCE_OPTIONAL; source=Model3_ETH.compact.json; json_start_position=8; conversion_policy=JSON_DIRECT";
CM_ SG_ 1251 VCRIGHT_frontSeatLiftPos "REFERENCE_OPTIONAL; source=Model3_ETH.compact.json; json_start_position=8; conversion_policy=JSON_DIRECT";
CM_ SG_ 1251 VCRIGHT_frontSeatBackPos "REFERENCE_OPTIONAL; source=Model3_ETH.compact.json; json_start_position=8; conversion_policy=JSON_DIRECT";
CM_ SG_ 1251 VCRIGHT_seatStatusIndex "REFERENCE_OPTIONAL; source=Model3_ETH.compact.json; json_start_position=0; conversion_policy=JSON_DIRECT";
CM_ BO_ 963 "REFERENCE_OPTIONAL converted from Model3_ETH.compact.json; product=Model3; version=3.1.2; bus=eth; not an authoritative vehicle definition";
CM_ SG_ 963 VCRIGHT_rearRightBuckleSwitch "REFERENCE_OPTIONAL; source=Model3_ETH.compact.json; json_start_position=46; conversion_policy=JSON_DIRECT";
CM_ SG_ 963 VCRIGHT_rearCenterBuckleSwitch "REFERENCE_OPTIONAL; source=Model3_ETH.compact.json; json_start_position=44; conversion_policy=JSON_DIRECT";
CM_ SG_ 963 VCRIGHT_frontBuckleSwitch "REFERENCE_OPTIONAL; source=Model3_ETH.compact.json; json_start_position=40; conversion_policy=JSON_DIRECT";
CM_ SG_ 963 VCRIGHT_switchStatusIndex "REFERENCE_OPTIONAL; source=Model3_ETH.compact.json; json_start_position=0; conversion_policy=JSON_DIRECT";
CM_ BO_ 899 "REFERENCE_OPTIONAL converted from Model3_ETH.compact.json; product=Model3; version=3.1.2; bus=eth; not an authoritative vehicle definition";
CM_ SG_ 899 VCRIGHT_thsSolarLoadVisible "REFERENCE_OPTIONAL; source=Model3_ETH.compact.json; json_start_position=43; conversion_policy=JSON_DIRECT";
CM_ SG_ 899 VCRIGHT_thsSolarLoadInfrared "REFERENCE_OPTIONAL; source=Model3_ETH.compact.json; json_start_position=33; conversion_policy=JSON_DIRECT";
CM_ SG_ 899 VCRIGHT_thsHumidity "REFERENCE_OPTIONAL; source=Model3_ETH.compact.json; json_start_position=17; conversion_policy=JSON_DIRECT";
CM_ SG_ 899 VCRIGHT_thsDetected "REFERENCE_OPTIONAL; source=Model3_ETH.compact.json; json_start_position=16; conversion_policy=JSON_DIRECT";
CM_ SG_ 899 VCRIGHT_thsTemperature "REFERENCE_OPTIONAL; source=Model3_ETH.compact.json; json_start_position=1; conversion_policy=JSON_DIRECT";
CM_ BO_ 1545 "REFERENCE_OPTIONAL converted from Model3_ETH.compact.json; product=Model3; version=3.1.2; bus=eth; not an authoritative vehicle definition";
CM_ SG_ 1545 VCRIGHT_udsResponseData_L "REFERENCE_OPTIONAL; source=Model3_ETH.compact.json; json_start_position=39; conversion_policy=LOCAL_DBC_START_BIT_ADAPTATION";
CM_ SG_ 1545 VCRIGHT_udsResponseData_H "REFERENCE_OPTIONAL; source=Model3_ETH.compact.json; json_start_position=7; conversion_policy=LOCAL_DBC_START_BIT_ADAPTATION";
CM_ BO_ 707 "REFERENCE_OPTIONAL converted from Model3_ETH.compact.json; product=Model3; version=3.1.2; bus=eth; not an authoritative vehicle definition";
CM_ SG_ 707 VCRIGHT_windowCalibratedRR "REFERENCE_OPTIONAL; source=Model3_ETH.compact.json; json_start_position=63; conversion_policy=JSON_DIRECT";
CM_ SG_ 707 VCRIGHT_windowPositionRR "REFERENCE_OPTIONAL; source=Model3_ETH.compact.json; json_start_position=54; conversion_policy=JSON_DIRECT";
CM_ SG_ 707 VCRIGHT_windowCalibratedRF "REFERENCE_OPTIONAL; source=Model3_ETH.compact.json; json_start_position=32; conversion_policy=JSON_DIRECT";
CM_ SG_ 707 VCRIGHT_windowPositionRF "REFERENCE_OPTIONAL; source=Model3_ETH.compact.json; json_start_position=22; conversion_policy=JSON_DIRECT";
CM_ SG_ 707 VCRIGHT_windowStatusIndex "REFERENCE_OPTIONAL; source=Model3_ETH.compact.json; json_start_position=0; conversion_policy=JSON_DIRECT";
CM_ BO_ 953 "REFERENCE_OPTIONAL converted from Model3_ETH.compact.json; product=Model3; version=3.1.2; bus=eth; not an authoritative vehicle definition";
CM_ SG_ 953 VCSEC_IsoTpPipeODIN7 "REFERENCE_OPTIONAL; source=Model3_ETH.compact.json; json_start_position=56; conversion_policy=JSON_DIRECT";
CM_ SG_ 953 VCSEC_IsoTpPipeODIN6 "REFERENCE_OPTIONAL; source=Model3_ETH.compact.json; json_start_position=48; conversion_policy=JSON_DIRECT";
CM_ SG_ 953 VCSEC_IsoTpPipeODIN5 "REFERENCE_OPTIONAL; source=Model3_ETH.compact.json; json_start_position=40; conversion_policy=JSON_DIRECT";
CM_ SG_ 953 VCSEC_IsoTpPipeODIN4 "REFERENCE_OPTIONAL; source=Model3_ETH.compact.json; json_start_position=32; conversion_policy=JSON_DIRECT";
CM_ SG_ 953 VCSEC_IsoTpPipeODIN3 "REFERENCE_OPTIONAL; source=Model3_ETH.compact.json; json_start_position=24; conversion_policy=JSON_DIRECT";
CM_ SG_ 953 VCSEC_IsoTpPipeODIN2 "REFERENCE_OPTIONAL; source=Model3_ETH.compact.json; json_start_position=16; conversion_policy=JSON_DIRECT";
CM_ SG_ 953 VCSEC_IsoTpPipeODIN1 "REFERENCE_OPTIONAL; source=Model3_ETH.compact.json; json_start_position=8; conversion_policy=JSON_DIRECT";
CM_ SG_ 953 VCSEC_IsoTpPipeODIN0 "REFERENCE_OPTIONAL; source=Model3_ETH.compact.json; json_start_position=0; conversion_policy=JSON_DIRECT";
CM_ BO_ 1066 "REFERENCE_OPTIONAL converted from Model3_ETH.compact.json; product=Model3; version=3.1.2; bus=eth; not an authoritative vehicle definition";
CM_ SG_ 1066 VCSEC_TPMSSensorState3 "REFERENCE_OPTIONAL; source=Model3_ETH.compact.json; json_start_position=42; conversion_policy=JSON_DIRECT";
CM_ SG_ 1066 VCSEC_TPMSSensorState2 "REFERENCE_OPTIONAL; source=Model3_ETH.compact.json; json_start_position=28; conversion_policy=JSON_DIRECT";
CM_ SG_ 1066 VCSEC_TPMSSensorState1 "REFERENCE_OPTIONAL; source=Model3_ETH.compact.json; json_start_position=14; conversion_policy=JSON_DIRECT";
CM_ SG_ 1066 VCSEC_TPMSSensorState0 "REFERENCE_OPTIONAL; source=Model3_ETH.compact.json; json_start_position=0; conversion_policy=JSON_DIRECT";
CM_ BO_ 570 "REFERENCE_OPTIONAL converted from Model3_ETH.compact.json; product=Model3; version=3.1.2; bus=eth; not an authoritative vehicle definition";
CM_ SG_ 570 VCSEC_TPMSSensorMACAddress3 "REFERENCE_OPTIONAL; source=Model3_ETH.compact.json; json_start_position=8; conversion_policy=JSON_DIRECT";
CM_ SG_ 570 VCSEC_TPMSSensorMACAddress2 "REFERENCE_OPTIONAL; source=Model3_ETH.compact.json; json_start_position=8; conversion_policy=JSON_DIRECT";
CM_ SG_ 570 VCSEC_TPMSSensorMACAddress1 "REFERENCE_OPTIONAL; source=Model3_ETH.compact.json; json_start_position=8; conversion_policy=JSON_DIRECT";
CM_ SG_ 570 VCSEC_TPMSSensorMACAddress0 "REFERENCE_OPTIONAL; source=Model3_ETH.compact.json; json_start_position=8; conversion_policy=JSON_DIRECT";
CM_ SG_ 570 VCSEC_TPMSStatusIndex "REFERENCE_OPTIONAL; source=Model3_ETH.compact.json; json_start_position=0; conversion_policy=JSON_DIRECT";
CM_ BO_ 1547 "REFERENCE_OPTIONAL converted from Model3_ETH.compact.json; product=Model3; version=3.1.2; bus=eth; not an authoritative vehicle definition";
CM_ SG_ 1547 VCSEC_udsResponseData "REFERENCE_OPTIONAL; source=Model3_ETH.compact.json; json_start_position=7; conversion_policy=LOCAL_DBC_START_BIT_ADAPTATION";
CM_ BO_ 1655 "REFERENCE_OPTIONAL converted from Model3_ETH.compact.json; product=Model3; version=3.1.2; bus=eth; not an authoritative vehicle definition";
CM_ SG_ 1655 VC_LVBMS_packVoltage "REFERENCE_OPTIONAL; source=Model3_ETH.compact.json; json_start_position=25; conversion_policy=JSON_DIRECT";
CM_ SG_ 1655 VC_LVBMS_MOSState "REFERENCE_OPTIONAL; source=Model3_ETH.compact.json; json_start_position=10; conversion_policy=JSON_DIRECT";
CM_ SG_ 1655 VC_LVBMS_packCurrent "REFERENCE_OPTIONAL; source=Model3_ETH.compact.json; json_start_position=3; conversion_policy=JSON_DIRECT";
CM_ SG_ 1655 VC_lvbmsStatusHighIndex "REFERENCE_OPTIONAL; source=Model3_ETH.compact.json; json_start_position=0; conversion_policy=JSON_DIRECT";
CM_ BO_ 1816 "REFERENCE_OPTIONAL converted from Model3_ETH.compact.json; product=Model3; version=3.1.2; bus=eth; not an authoritative vehicle definition";
CM_ SG_ 1816 VC_LVBMS_SOC "REFERENCE_OPTIONAL; source=Model3_ETH.compact.json; json_start_position=8; conversion_policy=JSON_DIRECT";
CM_ SG_ 1816 VC_lvbmsStatusLowIndex "REFERENCE_OPTIONAL; source=Model3_ETH.compact.json; json_start_position=0; conversion_policy=JSON_DIRECT";
BA_DEF_ SG_  "SystemSignalLongSymbol" STRING ;
BA_DEF_ BO_  "GenMsgCycleTime" INT 0 65535;
BA_DEF_DEF_  "SystemSignalLongSymbol" "";
BA_DEF_DEF_  "GenMsgCycleTime" 0;
BA_ "GenMsgCycleTime" BO_ 1177 1000;
BA_ "GenMsgCycleTime" BO_ 970 500;
BA_ "GenMsgCycleTime" BO_ 818 1000;
BA_ "GenMsgCycleTime" BO_ 562 100;
BA_ "GenMsgCycleTime" BO_ 306 10;
BA_ "GenMsgCycleTime" BO_ 884 1000;
BA_ "GenMsgCycleTime" BO_ 914 1000;
BA_ "GenMsgCycleTime" BO_ 658 100;
BA_ "GenMsgCycleTime" BO_ 530 100;
BA_ "GenMsgCycleTime" BO_ 541 100;
BA_ "GenMsgCycleTime" BO_ 1885 200;
BA_ "GenMsgCycleTime" BO_ 528 100;
BA_ "GenMsgCycleTime" BO_ 858 1000;
BA_ "GenMsgCycleTime" BO_ 634 100;
BA_ "GenMsgCycleTime" BO_ 725 10;
BA_ "GenMsgCycleTime" BO_ 965 1000;
BA_ "GenMsgCycleTime" BO_ 633 100;
BA_ "GenMsgCycleTime" BO_ 598 10;
BA_ "GenMsgCycleTime" BO_ 599 20;
BA_ "GenMsgCycleTime" BO_ 280 10;
BA_ "GenMsgCycleTime" BO_ 615 1000;
BA_ "GenMsgCycleTime" BO_ 977 1000;
BA_ "GenMsgCycleTime" BO_ 883 10;
BA_ "GenMsgCycleTime" BO_ 882 10;
BA_ "GenMsgCycleTime" BO_ 681 100;
BA_ "GenMsgCycleTime" BO_ 744 100;
BA_ "GenMsgCycleTime" BO_ 325 20;
BA_ "GenMsgCycleTime" BO_ 1621 100;
BA_ "GenMsgCycleTime" BO_ 373 20;
BA_ "GenMsgCycleTime" BO_ 904 1000;
BA_ "GenMsgCycleTime" BO_ 2047 100;
BA_ "GenMsgCycleTime" BO_ 1638 250;
BA_ "GenMsgCycleTime" BO_ 1376 1000;
BA_ "GenMsgCycleTime" BO_ 522 1000;
BA_ "GenMsgCycleTime" BO_ 1962 1000;
BA_ "GenMsgCycleTime" BO_ 1666 100;
BA_ "GenMsgCycleTime" BO_ 925 40;
BA_ "GenMsgCycleTime" BO_ 771 500;
BA_ "GenMsgCycleTime" BO_ 782 250;
BA_ "GenMsgCycleTime" BO_ 692 100;
BA_ "GenMsgCycleTime" BO_ 548 100;
BA_ "GenMsgCycleTime" BO_ 469 10;
BA_ "GenMsgCycleTime" BO_ 472 10;
BA_ "GenMsgCycleTime" BO_ 463 10;
BA_ "GenMsgCycleTime" BO_ 257 20;
BA_ "GenMsgCycleTime" BO_ 278 20;
BA_ "GenMsgCycleTime" BO_ 529 100;
BA_ "GenMsgCycleTime" BO_ 297 10;
BA_ "GenMsgCycleTime" BO_ 545 50;
BA_ "GenMsgCycleTime" BO_ 832 100;
BA_ "GenMsgCycleTime" BO_ 1014 200;
BA_ "GenMsgCycleTime" BO_ 897 30;
BA_ "GenMsgCycleTime" BO_ 513 25;
BA_ "SystemSignalLongSymbol" SG_ 513 VCFRONT_loggingAndVitals10HzInde "VCFRONT_loggingAndVitals10HzIndex";
BA_ "GenMsgCycleTime" BO_ 801 1000;
BA_ "GenMsgCycleTime" BO_ 737 14;
BA_ "GenMsgCycleTime" BO_ 864 100;
BA_ "GenMsgCycleTime" BO_ 258 100;
BA_ "GenMsgCycleTime" BO_ 322 50;
BA_ "GenMsgCycleTime" BO_ 727 100;
BA_ "SystemSignalLongSymbol" SG_ 727 VCLEFT_pitchEstimateArbitratedSt "VCLEFT_pitchEstimateArbitratedState";
BA_ "GenMsgCycleTime" BO_ 778 50;
BA_ "GenMsgCycleTime" BO_ 1250 100;
BA_ "GenMsgCycleTime" BO_ 962 50;
BA_ "GenMsgCycleTime" BO_ 706 100;
BA_ "GenMsgCycleTime" BO_ 960 100;
BA_ "GenMsgCycleTime" BO_ 259 100;
BA_ "GenMsgCycleTime" BO_ 1251 100;
BA_ "GenMsgCycleTime" BO_ 963 100;
BA_ "GenMsgCycleTime" BO_ 899 100;
BA_ "GenMsgCycleTime" BO_ 707 100;
BA_ "GenMsgCycleTime" BO_ 1066 100;
BA_ "GenMsgCycleTime" BO_ 570 1000;
BA_ "GenMsgCycleTime" BO_ 1655 33;
BA_ "GenMsgCycleTime" BO_ 1816 100;
VAL_ 1177 APP_lRepeaterCameraTemperature 255 "SNA" ;
VAL_ 1177 APP_rRepeaterCameraTemperature 255 "SNA" ;
VAL_ 970 APS_canMaster 2 "CAN_MASTER_APB" 1 "CAN_MASTER_APP" 0 "CAN_MASTER_APS" 3 "CAN_MASTER_SNA" ;
VAL_ 818 BMS_bmbMinMaxMultiplexer 2 "BMB_END" 0 "BMB_THERM_MUX0" 1 "BMB_VOLT_MUX1" ;
VAL_ 562 BMS_hvilCoverVSense 65535 "SNA" ;
VAL_ 562 BMS_internalHvilSenseV 65535 "SNA" ;
VAL_ 306 BMS_packCurrent -32768 "SNA" ;
VAL_ 884 BMS_log1MuxId 10 "BMS_LOG1_BANDOLIER_MODEL_PACK_TEMPS" 11 "BMS_LOG1_BANDOLIER_MODEL_THERMISTOR_TEMPS_1" 12 "BMS_LOG1_BANDOLIER_MODEL_THERMISTOR_TEMPS_2" 20 "BMS_LOG1_CHARGE_ENERGY_1" 21 "BMS_LOG1_CHARGE_ENERGY_2" 22 "BMS_LOG1_CHARGE_ENERGY_3" 23 "BMS_LOG1_CHARGE_ENERGY_4" 8 "BMS_LOG1_CHARGE_INTERFACE_1" 9 "BMS_LOG1_CHARGE_INTERFACE_2" 24 "BMS_LOG1_CHARGE_LIMIT_1" 25 "BMS_LOG1_CHARGE_LIMIT_2" 14 "BMS_LOG1_CHARGE_REGULATION" 13 "BMS_LOG1_CHARGE_TERMINATION" 0 "BMS_LOG1_CPU_USAGE1" 1 "BMS_LOG1_CPU_USAGE2" 2 "BMS_LOG1_CPU_USAGE3" 17 "BMS_LOG1_IMPEDANCE_DEVIATION_1" 18 "BMS_LOG1_IMPEDANCE_DEVIATION_2" 6 "BMS_LOG1_NEG_CTR_HEALTH_1" 7 "BMS_LOG1_NEG_CTR_HEALTH_2" 19 "BMS_LOG1_PACK_DATA" 4 "BMS_LOG1_POS_CTR_HEALTH_1" 5 "BMS_LOG1_POS_CTR_HEALTH_2" 26 "BMS_LOG1_SLEEP_CURRENT_1" 27 "BMS_LOG1_SLEEP_CURRENT_2" 15 "BMS_LOG1_SOC_BY_DELTA_V_1" 16 "BMS_LOG1_SOC_BY_DELTA_V_2" 3 "BMS_LOG1_STATES_AND_BOOLS" ;
VAL_ 914 BMS_reservedConfig_0 0 "BMS_CONFIG_0" 1 "BMS_CONFIG_1" 10 "BMS_CONFIG_10" 11 "BMS_CONFIG_11" 12 "BMS_CONFIG_12" 13 "BMS_CONFIG_13" 14 "BMS_CONFIG_14" 15 "BMS_CONFIG_15" 16 "BMS_CONFIG_16" 17 "BMS_CONFIG_17" 18 "BMS_CONFIG_18" 19 "BMS_CONFIG_19" 2 "BMS_CONFIG_2" 20 "BMS_CONFIG_20" 21 "BMS_CONFIG_21" 22 "BMS_CONFIG_22" 23 "BMS_CONFIG_23" 24 "BMS_CONFIG_24" 25 "BMS_CONFIG_25" 26 "BMS_CONFIG_26" 27 "BMS_CONFIG_27" 28 "BMS_CONFIG_28" 29 "BMS_CONFIG_29" 3 "BMS_CONFIG_3" 30 "BMS_CONFIG_30" 31 "BMS_CONFIG_31" 4 "BMS_CONFIG_4" 5 "BMS_CONFIG_5" 6 "BMS_CONFIG_6" 7 "BMS_CONFIG_7" 8 "BMS_CONFIG_8" 9 "BMS_CONFIG_9" ;
VAL_ 914 BMS_packConfigMultiplexer 0 "Mux0" 1 "Mux1" ;
VAL_ 1170 BMS_sohTestState 8 "ABORTED" 5 "CHARGE" 7 "COMPLETE" 4 "DISCHARGE" 3 "HEAT_PACK" 0 "NOT_READY" 1 "READY" 6 "RESTING" 2 "SAMPLE_CHARGE_POWER" ;
VAL_ 1170 BMS_stateOfHealth 1023 "SNA" ;
VAL_ 530 BMS_state 3 "BMS_CHARGE" 5 "BMS_CLEAR_FAULT" 10 "BMS_DIAG" 1 "BMS_DRIVE" 6 "BMS_FAULT" 4 "BMS_FEIM" 9 "BMS_SNA" 0 "BMS_STANDBY" 2 "BMS_SUPPORT" 8 "BMS_TEST" 7 "BMS_WELD" ;
VAL_ 530 BMS_isolationResistance 1023 "SNA" ;
VAL_ 530 BMS_hvState 1 "HV_COMING_UP" 0 "HV_DOWN" 2 "HV_GOING_DOWN" 6 "HV_UP" 4 "HV_UP_FOR_CHARGE" 5 "HV_UP_FOR_DC_CHARGE" 3 "HV_UP_FOR_DRIVE" ;
VAL_ 530 BMS_ecuLogUploadRequest 1 "REQUEST_PRIORITY_1" 2 "REQUEST_PRIORITY_2" 3 "REQUEST_PRIORITY_3" 0 "REQUEST_PRIORITY_NONE" ;
VAL_ 530 BMS_userChargeStatus 2 "BMS_ABOUT_TO_CHARGE" 6 "BMS_CALIBRATING" 4 "BMS_CHARGE_COMPLETE" 5 "BMS_CHARGE_STOPPED" 3 "BMS_CHARGING" 0 "BMS_DISCONNECTED" 1 "BMS_NO_POWER" ;
VAL_ 530 BMS_contactorState 6 "BMS_CTRSET_BLOCKED" 4 "BMS_CTRSET_CLOSED" 3 "BMS_CTRSET_CLOSING" 1 "BMS_CTRSET_OPEN" 2 "BMS_CTRSET_OPENING" 0 "BMS_CTRSET_SNA" 5 "BMS_CTRSET_WELDED" ;
VAL_ 541 CP_gbState 10 "GBDC_CHARGE_DISABLING" 5 "GBDC_CHARGE_PARAM_CONFIG" 8 "GBDC_CHARGING" 2 "GBDC_COMMS_RECEIVED" 11 "GBDC_END_OF_CHARGE" 12 "GBDC_ERROR_HANDLING" 14 "GBDC_FAULTED" 3 "GBDC_HANDSHAKING_EXT_ISO" 0 "GBDC_INACTIVE" 7 "GBDC_READY_TO_CHARGE" 4 "GBDC_RECOGNITION" 13 "GBDC_RETRY_CHARGE" 9 "GBDC_STOP_CHARGE_REQUESTED" 15 "GBDC_TESTER_PRESENT" 6 "GBDC_VEH_PACK_PRECHARGE" 1 "GBDC_WAIT_FOR_COMMS" ;
VAL_ 541 CP_evseChargeType_UI 2 "AC_CHARGER_PRESENT" 1 "DC_CHARGER_PRESENT" 0 "NO_CHARGER_PRESENT" ;
VAL_ 541 CP_proximity 1 "CHG_PROXIMITY_DISCONNECTED" 3 "CHG_PROXIMITY_LATCHED" 0 "CHG_PROXIMITY_SNA" 2 "CHG_PROXIMITY_UNLATCHED" ;
VAL_ 1885 CP_chargeCablePresent 0 "CABLE_NOT_PRESENT" 1 "CABLE_PRESENT" ;
VAL_ 1885 CP_loggingFastSelect 0 "CP_LOGGING_FAST_0" 1 "CP_LOGGING_FAST_1" 2 "CP_LOGGING_FAST_2" 3 "CP_LOGGING_FAST_3" 4 "CP_LOGGING_FAST_4" ;
VAL_ 528 CP_chargeCableState 2 "CHARGE_CABLE_CONNECTED" 1 "CHARGE_CABLE_NOT_CONNECTED" 0 "CHARGE_CABLE_UNKNOWN_SNA" ;
VAL_ 634 DIF_hvilStatus 2 "CLOSED" 0 "DISABLED" 1 "OPEN" 3 "SNA" ;
VAL_ 725 DIF_wasteState 1 "DI_WASTE_AVAILABLE" 2 "DI_WASTE_ON" 3 "DI_WASTE_STATIONARY" 0 "DI_WASTE_UNAVAILABLE" ;
VAL_ 633 DIR_hvilStatus 2 "CLOSED" 0 "DISABLED" 1 "OPEN" 3 "SNA" ;
VAL_ 598 DIR_wasteState 1 "DI_WASTE_AVAILABLE" 2 "DI_WASTE_ON" 3 "DI_WASTE_STATIONARY" 0 "DI_WASTE_UNAVAILABLE" ;
VAL_ 598 DIR_state 3 "DI_STATE_ABORT" 4 "DI_STATE_ENABLE" 2 "DI_STATE_FAULT" 1 "DI_STATE_STANDBY" 0 "DI_STATE_UNAVAILABLE" ;
VAL_ 599 DI_vehicleSpeed 8191 "SNA" ;
VAL_ 280 DI_hvilSystemStatus 2 "CLOSED" 0 "DISABLED" 1 "OPEN" 3 "SNA" ;
VAL_ 280 DI_gear 4 "DI_GEAR_D" 0 "DI_GEAR_INVALID" 3 "DI_GEAR_N" 1 "DI_GEAR_P" 2 "DI_GEAR_R" 7 "DI_GEAR_SNA" ;
VAL_ 280 DI_brakePedalState 2 "INVALID" 0 "OFF" 1 "ON" ;
VAL_ 883 EPAS3P_torsionBarTorque 4095 "SNA" 4094 "UNDEFINABLE_DATA" ;
VAL_ 882 EPAS3S_torsionBarTorque 4095 "SNA" 4094 "UNDEFINABLE_DATA" ;
VAL_ 681 EPBL_systemStatus 3 "EPB_VEHICLE_STATUS_DYNAMIC" 6 "EPB_VEHICLE_STATUS_FAULT" 7 "EPB_VEHICLE_STATUS_FAULT_SECURE" 8 "EPB_VEHICLE_STATUS_MISMATCH" 2 "EPB_VEHICLE_STATUS_PARKED" 4 "EPB_VEHICLE_STATUS_PARKING" 1 "EPB_VEHICLE_STATUS_RELEASED" 5 "EPB_VEHICLE_STATUS_RELEASING" 0 "EPB_VEHICLE_STATUS_UNKNOWN" ;
VAL_ 744 EPBR_systemStatus 3 "EPB_VEHICLE_STATUS_DYNAMIC" 6 "EPB_VEHICLE_STATUS_FAULT" 7 "EPB_VEHICLE_STATUS_FAULT_SECURE" 8 "EPB_VEHICLE_STATUS_MISMATCH" 2 "EPB_VEHICLE_STATUS_PARKED" 4 "EPB_VEHICLE_STATUS_PARKING" 1 "EPB_VEHICLE_STATUS_RELEASED" 5 "EPB_VEHICLE_STATUS_RELEASING" 0 "EPB_VEHICLE_STATUS_UNKNOWN" ;
VAL_ 325 ESP_stabilityControlSts2 2 "ENGAGED" 3 "FAULTED" 0 "INIT" 1 "ON" ;
VAL_ 373 ESP_wheelSpeedReR 8191 "SNA" ;
VAL_ 373 ESP_wheelSpeedReL 8191 "SNA" ;
VAL_ 373 ESP_wheelSpeedFrR 8191 "SNA" ;
VAL_ 373 ESP_wheelSpeedFrL 8191 "SNA" ;
VAL_ 904 GTW_CH_faultConfinement 2 "BUS_OFF" 0 "ERROR_ACTIVE" 1 "ERROR_PASSIVE" ;
VAL_ 904 GTW_PARTY_faultConfinement 2 "BUS_OFF" 0 "ERROR_ACTIVE" 1 "ERROR_PASSIVE" ;
VAL_ 904 GTW_VEH_faultConfinement 2 "BUS_OFF" 0 "ERROR_ACTIVE" 1 "ERROR_PASSIVE" ;
VAL_ 2047 GTW_numberHVILNodes 0 "HVIL_NODES_0" 2 "HVIL_NODES_2" 3 "HVIL_NODES_3" ;
VAL_ 2047 GTW_headlightLevelerType 1 "GEN1" 0 "NONE" 2 "VIRTUAL_PITCH_SENSOR" ;
VAL_ 2047 GTW_drivetrainType 1 "AWD" 0 "RWD" ;
VAL_ 2047 GTW_epasType 0 "MANDO_VGR69_GEN3" 3 "MANDO_VGR69_GEN3_SINGLE_ECU" ;
VAL_ 2047 GTW_chassisType 2 "MODEL_3_CHASSIS" 3 "MODEL_Y_CHASSIS" ;
VAL_ 2047 GTW_mapRegion 4 "AU" 3 "CN" 1 "EU" 9 "HK" 5 "JP" 7 "KR" 8 "ME" 10 "MO" 2 "NONE" 11 "SE" 6 "TW" 0 "US" ;
VAL_ 2047 GTW_deliveryStatus 1 "DELIVERED" 0 "NOT_DELIVERED" ;
VAL_ 1638 GTW_diagLevel 10 "LEVEL_DIAG_LINK_ACTIVE" 0 "LEVEL_FACTORY" 100 "LEVEL_NORMAL_OPERATION" 80 "LEVEL_PARK" 25 "LEVEL_SERVICE" 50 "LEVEL_SERVICE_DRIVE" ;
VAL_ 522 HVP_hvilDiag 2 "CURRENT_SOURCE_OR_GROUND_LEAK_FAULT" 12 "DI_OPEN_FAULT" 10 "DI_STATUS_MISSING_FAULT" 3 "INTERNAL_OPEN_FAULT" 8 "NO_12V_SUPPLY" 1 "OK" 5 "PENTHOUSE_LID_OPEN_FAULT" 13 "PM_OPEN_FAULT" 11 "PM_STATUS_MISSING_FAULT" 14 "SNA" 0 "UNKNOWN" 6 "UNKNOWN_LOCATION_OPEN_FAULT" 7 "VEHICLE_NODE_FAULT" 4 "VEHICLE_OPEN_FAULT" 9 "VEHICLE_OR_PENTHOUSE_LID_OPEN_FAULT" ;
VAL_ 1962 HVP_ecuLogUploadRequest 1 "REQUEST_PRIORITY_1" 2 "REQUEST_PRIORITY_2" 3 "REQUEST_PRIORITY_3" 0 "REQUEST_PRIORITY_NONE" ;
VAL_ 1962 HVP_debugMessageMultiplexer 0 "Mux0" 1 "Mux1" 10 "Mux10" 11 "Mux11" 12 "Mux12" 2 "Mux2" 3 "Mux3" 4 "Mux4" 5 "Mux5" 6 "Mux6" 7 "Mux7" 8 "Mux8" 9 "Mux9" ;
VAL_ 1666 HVP_hvilStatus 2 "FAULT" 1 "OK" 0 "UNKNOWN" ;
VAL_ 925 IBST_driverBrakeApply 1 "BRAKES_NOT_APPLIED" 2 "DRIVER_APPLYING_BRAKES" 3 "FAULT" 0 "NOT_INIT_OR_OFF" ;
VAL_ 925 IBST_iBoosterStatus 4 "IBOOSTER_ACTIVE_GOOD_CHECK" 6 "IBOOSTER_ACTUATION" 3 "IBOOSTER_DIAGNOSTIC" 2 "IBOOSTER_FAILURE" 1 "IBOOSTER_INIT" 0 "IBOOSTER_OFF" 5 "IBOOSTER_READY" ;
VAL_ 771 OCS1P_occupiedState 1 "OCCUPIED_STATE_OCCUPIED" 3 "OCCUPIED_STATE_SNA" 0 "OCCUPIED_STATE_UNOCCUPIED" ;
VAL_ 782 PARK_sdiActive 0 "SDI_DISABLED" 1 "SDI_ENABLED" ;
VAL_ 548 PCS_ecuLogUploadRequest 1 "REQUEST_PRIORITY_1" 2 "REQUEST_PRIORITY_2" 3 "REQUEST_PRIORITY_3" 0 "REQUEST_PRIORITY_NONE" ;
VAL_ 548 PCS_dcdcLvSupportStatus 1 "PCS_DCDC_LV_SUPPORT_ACTIVE" 2 "PCS_DCDC_LV_SUPPORT_FAULTED" 0 "PCS_DCDC_LV_SUPPORT_IDLE" ;
VAL_ 469 PMF_hvilStatus 2 "CLOSED" 0 "DISABLED" 1 "OPEN" 3 "SNA" ;
VAL_ 472 PMR_hvilStatus 2 "CLOSED" 0 "DISABLED" 1 "OPEN" 3 "SNA" ;
VAL_ 463 PM_hvilSystemStatus 2 "CLOSED" 0 "DISABLED" 1 "OPEN" 3 "SNA" ;
VAL_ 257 RCM_rollRate -16384 "SNA" ;
VAL_ 257 RCM_pitchRate -16384 "SNA" ;
VAL_ 257 RCM_yawRate -32768 "SNA" ;
VAL_ 278 RCM_verticalAccel -32768 "SNA" ;
VAL_ 278 RCM_lateralAccel -32768 "SNA" ;
VAL_ 278 RCM_longitudinalAccel -32768 "SNA" ;
VAL_ 529 RCM_armStatus 2 "ARMED_WITH_NOFIRE_CAL" 1 "RCM_ARMED" 0 "RCM_UNARMED" 3 "SNA" ;
VAL_ 297 SCCM_steeringAngle 16383 "SNA" ;
VAL_ 1056 UIS_odinStatusCmdResult 2 "EXCEPTION" 1 "FAIL" 0 "PASS" ;
VAL_ 1056 UIS_odinProcessState 0 "IDLE" 1 "RUNNING_NETWORK" 3 "RUNNING_NETWORK_AND_ORCHESTRATOR" 2 "RUNNING_ORCHESTRATOR" 4 "UNKNOWN" ;
VAL_ 1056 UIS_odinListTasksCmdResult 2 "EXCEPTION" 1 "FAIL" 0 "PASS" ;
VAL_ 1056 UIS_odinHermesConnectionState 1 "HERMES_CONNECTED" 2 "HERMES_CONNECTING" 3 "HERMES_CONNECTION_ERROR" 0 "HERMES_DISCONNECTED" ;
VAL_ 1056 UIS_odinGatewayConnectionState 1 "GATEWAY_CONNECTED" 2 "GATEWAY_CONNECTION_ERROR" 0 "GATEWAY_DISCONNECTED" ;
VAL_ 1056 UIS_logMux 247 "activeAppView" 246 "amdSocPkgPower" 245 "audioA2BRediscoveryCount" 244 "audioMediaBrowsing" 243 "audioMediaPlaying" 242 "audioSource" 241 "audioState" 240 "audioType" 239 "audioVolumeLevel" 238 "bluetoothAutoConnectionState" 237 "bluetoothCPUUsage" 236 "bluetoothConnectionState" 235 "bluetoothMemUsage" 234 "bluetoothPairResult" 233 "bluetoothStackState" 232 "boardTemperature" 231 "bootCount" 230 "cameraBackupFramerate" 229 "cameraBackupLateFrames" 228 "cameraBackupMaxFrametime" 227 "cameraBackupPipeline" 226 "cameraBackupPopup" 225 "cameraBackupStream" 224 "cameraBackupStreamMissing" 223 "cameraBackupStreamQuality" 222 "cameraLRepeaterFramerate" 221 "cameraLRepeaterLateFrames" 220 "cameraLRepeaterMaxFrametime" 219 "cameraLRepeaterPipeline" 218 "cameraLRepeaterPopup" 217 "cameraLRepeaterStream" 216 "cameraLRepeaterStreamMissing" 215 "cameraRRepeaterFramerate" 214 "cameraRRepeaterLateFrames" 213 "cameraRRepeaterMaxFrametime" 212 "cameraRRepeaterPipeline" 211 "cameraRRepeaterPopup" 210 "cameraRRepeaterStream" 209 "cameraRRepeaterStreamMissing" 208 "cellularLinkManagerState" 207 "centerDispAsilA_lsb" 206 "centerDispAsilA_msb" 205 "centerDispAsilB_lsb" 204 "centerDispAsilB_msb" 203 "centerDisplayState" 202 "ceruleanx8664CPUUsage" 201 "ceruleanx8664MemUsage" 200 "clusterCPUUsage" 199 "clusterDisplayState" 198 "clusterFramesOver100Ms" 197 "clusterFramesOver200Ms" 196 "clusterMaxFrametime" 195 "clusterMeanFPS" 194 "clusterMemUsage" 193 "cobaltlinuxCPUUsage" 192 "cobaltlinuxMemUsage" 191 "compositorRenderFrameRate" 190 "compositorRenderMaxFrameTime" 189 "compositorRenderMinFrameTime" 188 "cpuTemperature" 187 "dashcamOnboardAvailableMB" 186 "dashcamOnboardMB" 185 "dashcamOnboardSavePressCount" 184 "dashcamOnboardTransferCount" 183 "dashcamSavedToOnboardCount" 182 "dashcamSavedToSavedCount" 181 "dashcamSavedToSentryCount" 180 "dashcamState" 179 "dashcamStorageAvailableMB" 178 "dashcamStorageRecentMB" 177 "dashcamStorageSavedMB" 176 "dashcamStorageSentryMB" 175 "dashcamStorageState" 174 "dashcamTransferCount" 173 "dashcamTransferFileCount" 172 "dashcamTransferRateMBps" 171 "dashcamTransferSizeMB" 170 "dashcamTransferTimeMs" 169 "dashcamviewerCPUUsage" 168 "dashcamviewerMemUsage" 167 "developerMode" 166 "dgpuTemperature" 165 "dmCenterBacklightDevExists" 164 "dmCenterBacklightDutyCycle" 163 "dmCenterBacklightFault" 162 "dmCenterBacklightPowerLevel" 161 "dmCenterLinkCheckOk" 160 "dmCenterMOsdExactCrcCheck" 159 "dmCenterMOsdVideoCrcData" 158 "dmCenterModeSettingStatus" 157 "dmCenterOsdDayNightState" 156 "dmCenterOsdDisplayedState" 155 "dmCenterPowerState" 154 "dmCenterSOsdExactCrcCheck" 153 "dmCenterSOsdVideoCrcData" 152 "dmCenterTouchDeviceExists" 151 "dmGatewayLinkWedged" 150 "dmIcuBacklightDevExists" 149 "dmIcuBacklightDutyCycle" 148 "dmIcuBacklightFault" 147 "dmIcuBacklightPowerLevel" 146 "dmIcuLinkCheckOk" 145 "dmIcuPowerState" 144 "dmRearBacklightDevExists" 143 "dmRearBacklightDutyCycle" 142 "dmRearBacklightFault" 141 "dmRearBacklightPowerLevel" 140 "dmRearLinkCheckOk" 139 "dmRearPowerState" 138 "dmRearTouchDeviceExists" 137 "embeddedGameName" 136 "embeddedGameState" 135 "godotCPUUsage" 134 "godotMemUsage" 133 "godot_MEMORY_DYNAMIC" 132 "godot_MEMORY_STATIC" 131 "godot_TIME_FPS" 130 "godot_TIME_PROCESS" 129 "gpsmanagerCPUUsage" 128 "gpsmanagerMemUsage" 127 "hermesclientCPUUsage" 126 "hermesclientMemUsage" 125 "hermesdynamicCPUUsage" 124 "hermesdynamicMemUsage" 123 "igpuTemperature" 122 "inSuperchargerGeofence" 121 "limex8664CPUUsage" 120 "limex8664MemUsage" 119 "mediaImageCacheCost" 118 "mediaImageCacheSize" 117 "mediaNeedAuthToken" 116 "mediaPlaybackStatus" 115 "mediaserveCPUUsage" 114 "mediaserveMemUsage" 113 "mounterdDashcamCapacityGB" 112 "mounterdDeviceCount" 111 "mounterdEncryptionCapacityGB" 110 "mounterdFilesystemCountExfat" 109 "mounterdFilesystemCountExt3" 108 "mounterdFilesystemCountExt4" 107 "mounterdFilesystemCountFat32" 106 "mounterdFrontHubConnected" 105 "mounterdFrontHubDisconnected" 104 "mounterdMountCountTotal" 103 "mounterdState" 102 "nuanceserverCPUUsage" 101 "nuanceserverMemUsage" 100 "numCorrMemErrorsECC" 99 "numUncorrMemErrorsECC" 98 "nvmeDataUnitsWritten100mb" 97 "nvmePercentLifetimeUsed" 96 "nvmeTemperature" 95 "odinAuthCount" 94 "odinAuthFailCount" 93 "odinCPUUsage" 92 "odinGatewayConnectionState" 91 "odinHermesConnectionState" 90 "odinListTasksCmdDurationMs" 89 "odinListTasksCmdResult" 88 "odinMemUsage" 87 "odinNetworkFailCount" 86 "odinNetworkStartCount" 85 "odinOrchestratorFailCount" 84 "odinOrchestratorStartCount" 83 "odinProcessState" 82 "odinStatusCmdDurationMs" 81 "odinStatusCmdResult" 80 "odincefCPUUsage" 79 "odincefMemUsage" 78 "polytopiax8664CPUUsage" 77 "polytopiax8664MemUsage" 76 "psiCpuFull" 75 "psiIOFull" 74 "psiIOSome" 73 "psiMemFull" 72 "psiMemSome" 71 "qtcarCPUUsage" 70 "qtcarMemUsage" 69 "radioserveCPUUsage" 68 "radioserveMemUsage" 67 "rearDisplayState" 66 "releasenotesCPUUsage" 65 "releasenotesMemUsage" 64 "sentryIncidentCount" 63 "sentryNeedsNap" 62 "sentryState" 61 "serverCPUUsage" 60 "serverMemUsage" 59 "settingsAutoTurnSignal" 58 "sleepCount" 57 "sleepState" 56 "sleepTime" 55 "sleepType" 54 "solitaireCPUUsage" 53 "solitaireMemUsage" 52 "speechrecoCPUUsage" 51 "speechrecoMemUsage" 50 "spotifyserverCPUUsage" 49 "spotifyserverMemUsage" 48 "sudokuCPUUsage" 47 "sudokuMemUsage" 46 "systemMemSwapUsage" 45 "systemUptime" 44 "tegraModemManState" 43 "teslaMediaCacheCost" 42 "teslaMediaCacheSize" 41 "teslacefgpuCPUUsage" 40 "teslacefgpuMemUsage" 39 "teslacefzygotCPUUsage" 38 "teslacefzygotMemUsage" 37 "teslachromiumCPUUsage" 36 "teslachromiumMemUsage" 35 "tmserverCPUUsage" 34 "tmserverMemUsage" 33 "touchEventsAggCount" 32 "uiFramesOver100Ms" 31 "uiFramesOver200Ms" 30 "uiMaxFrametime" 29 "uiMeanFPS" 28 "uiQtCarSwapUsage" 27 "uiQtCarUptime" 26 "valetMode" 25 "valhallaserverCPUUsage" 24 "valhallaserverMemUsage" 23 "vehicleCPUUsage" 22 "vehicleMemUsage" 21 "videodCPUUsage" 20 "videodMemUsage" 19 "vmtouchCPUUsage" 18 "vmtouchMemUsage" 17 "webbrowserCPUUsage" 16 "webbrowserMemUsage" 15 "wifiAutoJoinLowRSSI" 14 "wifiBars" 13 "wifiStackReady" 12 "wifiStackState" 11 "wifiTemperature" 10 "zramCompressedSize" 9 "zramCompressionRatio" 8 "zramFailedReads" 7 "zramFailedWrites" 6 "zramInvalidIO" 5 "zramNotifyFree" 4 "zramOriginalSize" 3 "zramReadIO" 2 "zramReadTicks" 1 "zramWriteIO" 0 "zramWriteTicks" ;
VAL_ 545 VCFRONT_dirLVRequest 3 "LV_FAULT" 2 "LV_GOING_DOWN" 0 "LV_OFF" 1 "LV_ON" ;
VAL_ 545 VCFRONT_vehiclePowerState 2 "VEHICLE_POWER_STATE_ACCESSORY" 1 "VEHICLE_POWER_STATE_CONDITIONING" 3 "VEHICLE_POWER_STATE_DRIVE" 0 "VEHICLE_POWER_STATE_OFF" ;
VAL_ 545 VCFRONT_LVPowerStateIndex 0 "Mux0" 1 "Mux1" ;
VAL_ 832 VCFRONT_matrixIndex 0 "VCFRONT_AlertMatrix0" 1 "VCFRONT_AlertMatrix1" 2 "VCFRONT_AlertMatrix2" 3 "VCFRONT_AlertMatrix3" 4 "VCFRONT_AlertMatrix4" 5 "VCFRONT_AlertMatrix5" 6 "VCFRONT_AlertMatrix6" 7 "VCFRONT_AlertMatrix7" 8 "VCFRONT_AlertMatrix8" 9 "VCFRONT_AlertMatrix9" ;
VAL_ 1014 VCFRONT_turnSignalRightStatus 2 "LIGHT_FAULT" 0 "LIGHT_OFF" 1 "LIGHT_ON" 3 "LIGHT_SNA" ;
VAL_ 1014 VCFRONT_turnSignalLeftStatus 2 "LIGHT_FAULT" 0 "LIGHT_OFF" 1 "LIGHT_ON" 3 "LIGHT_SNA" ;
VAL_ 897 VCFRONT_radiatorFanRPMTarget 255 "SNA" ;
VAL_ 897 VCFRONT_currentHorizPositionHCMR 1023 "SNA" ;
VAL_ 897 VCFRONT_pumpPowertrainRPMTarget 255 "SNA" ;
VAL_ 897 VCFRONT_currentHorizPositionHCML 1023 "SNA" ;
VAL_ 897 VCFRONT_logging1HzIndex 16 "BODY_CONTROL" 0 "COOLANT" 17 "COOLANT_2" 2 "COOLANT_VALVE" 30 "END" 1 "FAN_DEMAND_CONDENSER_AND_FET_TEMPS" 4 "HEADLAMP_AIM" 19 "HEADLAMP_AIM_2" 13 "HP_ARBITRATION" 7 "HP_CONTROL_LOOP_AND_STATE" 8 "HP_CYCLE_MODEL" 6 "HP_DATA_AND_ACCUMULATORS" 10 "HP_DISSIPATION_AND_POWER" 9 "HP_EXV_CALIBRATION" 5 "HP_EXV_RANGE" 15 "HP_MODE_OPTIONS_AND_ESTIMATES" 14 "HP_MODE_SELECT_AND_ESTIMATES" 12 "HP_PRESSURE_CONTROL" 18 "HP_PT_TARGETS" 11 "HP_TEMPS_AND_DEMANDS" 23 "HSD_CURRENTS_1" 24 "HSD_CURRENTS_2" 29 "MISC_FOUR" 3 "MISC_ONE" 25 "MISC_THREE" 20 "MISC_TWO" 21 "PART_FAILURE_CONFIDENCE" 22 "PART_FAILURE_CONFIDENCE_CONTINUED" 27 "POWER_RATIONALITY_VCLEFT" 28 "POWER_RATIONALITY_VCRIGHT" 26 "SLEEP_WAKE" ;
VAL_ 513 VCFRONT_coolantValveMode 3 "AMBIENT_SOURCE" 2 "BLEND" 1 "PARALLEL" 0 "SERIES" ;
VAL_ 513 VCFRONT_radiatorFanRPMActual 255 "SNA" ;
VAL_ 513 VCFRONT_pumpPowertrainRPMActual 255 "SNA" ;
VAL_ 513 VCFRONT_loggingAndVitals10HzInde 4 "END" 2 "EXV_FLOW" 3 "EXV_FLOW_TARGET" 1 "STATES_AND_SENSORS" 0 "TARGETS_AND_ACTUALS_0" ;
VAL_ 801 VCFRONT_tempCoolantPTInlet 2047 "SNA" ;
VAL_ 801 VCFRONT_tempCoolantBatInlet 1023 "SNA" ;
VAL_ 737 VCFRONT_refrigFillRoutineStatus 3 "FAULTED" 1 "MOVING_TO_FILL_POSITION" 0 "NOT_READY" 2 "READY_TO_FILL" ;
VAL_ 737 VCFRONT_coolantFillRoutineStatus 3 "FAULTED" 1 "MOVING_TO_FILL_POSITION" 0 "NOT_READY" 2 "READY_TO_FILL" ;
VAL_ 737 VCFRONT_frunkLatchStatus 5 "LATCH_AJAR" 2 "LATCH_CLOSED" 3 "LATCH_CLOSING" 7 "LATCH_DEFAULT" 8 "LATCH_FAULT" 1 "LATCH_OPENED" 4 "LATCH_OPENING" 0 "LATCH_SNA" 6 "LATCH_TIMEOUT" ;
VAL_ 737 VCFRONT_statusIndex 0 "VCF_STS_IDX_BODY_CONTROLS" 2 "VCF_STS_IDX_HOMELINK" 7 "VCF_STS_IDX_INVALID" 3 "VCF_STS_IDX_REFRIGERANT_SYSTEM" 4 "VCF_STS_IDX_SYSTEM_HEALTH" 5 "VCF_STS_IDX_THERMAL" 6 "VCF_STS_IDX_USER_PRESENCE" 1 "VCF_STS_IDX_VEHICLE_STATE" ;
VAL_ 864 VCLEFT_matrixIndex 0 "VCLEFT_AlertMatrix0" 1 "VCLEFT_AlertMatrix1" 2 "VCLEFT_AlertMatrix2" 3 "VCLEFT_AlertMatrix3" 4 "VCLEFT_AlertMatrix4" 5 "VCLEFT_AlertMatrix5" 6 "VCLEFT_AlertMatrix6" 7 "VCLEFT_AlertMatrix7" 8 "VCLEFT_AlertMatrix8" 9 "VCLEFT_AlertMatrix9" ;
VAL_ 258 VCLEFT_rearLatchStatus 5 "LATCH_AJAR" 2 "LATCH_CLOSED" 3 "LATCH_CLOSING" 7 "LATCH_DEFAULT" 8 "LATCH_FAULT" 1 "LATCH_OPENED" 4 "LATCH_OPENING" 0 "LATCH_SNA" 6 "LATCH_TIMEOUT" ;
VAL_ 258 VCLEFT_frontLatchStatus 5 "LATCH_AJAR" 2 "LATCH_CLOSED" 3 "LATCH_CLOSING" 7 "LATCH_DEFAULT" 8 "LATCH_FAULT" 1 "LATCH_OPENED" 4 "LATCH_OPENING" 0 "LATCH_SNA" 6 "LATCH_TIMEOUT" ;
VAL_ 322 VCLEFT_liftgateState 2 "PLG_STATE_BACKOFF" 5 "PLG_STATE_CLOSED" 4 "PLG_STATE_CLOSING" 11 "PLG_STATE_END_OF_TRAVEL" 0 "PLG_STATE_INIT" 7 "PLG_STATE_LATCH_CLOSING" 12 "PLG_STATE_LATCH_ENTRY" 10 "PLG_STATE_LATCH_EXIT" 6 "PLG_STATE_LATCH_OPENING" 8 "PLG_STATE_NOT_INSTALLED" 1 "PLG_STATE_OFF" 3 "PLG_STATE_OPENING" 13 "PLG_STATE_PARTY_DANCE" 9 "PLG_STATE_UNKNOWN" ;
VAL_ 322 VCLEFT_liftgateStatusIndex 0 "LIFTGATE_STATUS_INDEX_0" 1 "LIFTGATE_STATUS_INDEX_1" 2 "LIFTGATE_STATUS_INDEX_INVALID" ;
VAL_ 727 VCLEFT_pitchEstimate -512 "SNA" ;
VAL_ 727 VCLEFT_pitchEstimateArbitratedSt 3 "PITCHESTIMATION_ARBITRATEDSTATE_CYCLE_DELTA_CARRYOVER" 4 "PITCHESTIMATION_ARBITRATEDSTATE_CYCLE_DELTA_FROZEN" 2 "PITCHESTIMATION_ARBITRATEDSTATE_CYCLE_DELTA_LIVE" 1 "PITCHESTIMATION_ARBITRATEDSTATE_FUSION" 5 "PITCHESTIMATION_ARBITRATEDSTATE_LIVE_AX_NO_DELTA" 0 "PITCHESTIMATION_ARBITRATEDSTATE_UNAVAILABLE" 7 "PITCHESTIMATION_ARBITRATEDSTATE_UNKNOWN" ;
VAL_ 778 VCLEFT_rearRightOccupancyStatus 2 "SEAT_OCCUPANCY_FAULTED" 3 "SEAT_OCCUPANCY_SNA" 1 "SEAT_OCCUPIED" 0 "SEAT_UNOCCUPIED" ;
VAL_ 778 VCLEFT_rearCenterOccupancyStatus 2 "SEAT_OCCUPANCY_FAULTED" 3 "SEAT_OCCUPANCY_SNA" 1 "SEAT_OCCUPIED" 0 "SEAT_UNOCCUPIED" ;
VAL_ 778 VCLEFT_rearLeftOccupancyStatus 2 "SEAT_OCCUPANCY_FAULTED" 3 "SEAT_OCCUPANCY_SNA" 1 "SEAT_OCCUPIED" 0 "SEAT_UNOCCUPIED" ;
VAL_ 778 VCLEFT_frontBuckleStatus 2 "SEAT_BELT_BUCKLE_STATUS_FAULTED" 1 "SEAT_BELT_BUCKLE_STATUS_LATCHED" 3 "SEAT_BELT_BUCKLE_STATUS_SNA" 0 "SEAT_BELT_BUCKLE_STATUS_UNLATCHED" ;
VAL_ 778 VCLEFT_frontOccupancyStatus 3 "SEAT_NOT_CONFIGURED" 2 "SEAT_OCCUPANCY_FAULTED" 7 "SEAT_OCCUPANCY_SNA" 1 "SEAT_OCCUPIED" 0 "SEAT_UNOCCUPIED" ;
VAL_ 1250 VCLEFT_seatStatusIndex 1 "SEAT_STATUS_INDEX_BACK" 2 "SEAT_STATUS_INDEX_LIFT" 4 "SEAT_STATUS_INDEX_LUMBAR" 6 "SEAT_STATUS_INDEX_OFFSETS" 5 "SEAT_STATUS_INDEX_POSITION" 3 "SEAT_STATUS_INDEX_TILT" 0 "SEAT_STATUS_INDEX_TRACK" ;
VAL_ 962 VCLEFT_rearCenterBuckleSwitch 3 "SWITCH_FAULT" 1 "SWITCH_OFF" 2 "SWITCH_ON" 0 "SWITCH_SNA" ;
VAL_ 962 VCLEFT_rearRightOccupancySwitch 3 "SWITCH_FAULT" 1 "SWITCH_OFF" 2 "SWITCH_ON" 0 "SWITCH_SNA" ;
VAL_ 962 VCLEFT_rearLeftOccupancySwitch 3 "SWITCH_FAULT" 1 "SWITCH_OFF" 2 "SWITCH_ON" 0 "SWITCH_SNA" ;
VAL_ 962 VCLEFT_rearCenterOccupancySwitch 3 "SWITCH_FAULT" 1 "SWITCH_OFF" 2 "SWITCH_ON" 0 "SWITCH_SNA" ;
VAL_ 962 VCLEFT_rearLeftBuckleSwitch 3 "SWITCH_FAULT" 1 "SWITCH_OFF" 2 "SWITCH_ON" 0 "SWITCH_SNA" ;
VAL_ 962 VCLEFT_frontBuckleSwitch 3 "SWITCH_FAULT" 1 "SWITCH_OFF" 2 "SWITCH_ON" 0 "SWITCH_SNA" ;
VAL_ 962 VCLEFT_switchStatusIndex 0 "VCLEFT_SWITCH_STATUS_INDEX_0" 1 "VCLEFT_SWITCH_STATUS_INDEX_1" ;
VAL_ 706 VCLEFT_windowStatusIndex 0 "Mux0" 1 "Mux1" ;
VAL_ 960 VCRIGHT_matrixIndex 0 "VCRIGHT_AlertMatrix0" 1 "VCRIGHT_AlertMatrix1" 2 "VCRIGHT_AlertMatrix2" 3 "VCRIGHT_AlertMatrix3" 4 "VCRIGHT_AlertMatrix4" 5 "VCRIGHT_AlertMatrix5" 6 "VCRIGHT_AlertMatrix6" 7 "VCRIGHT_AlertMatrix7" 8 "VCRIGHT_AlertMatrix8" 9 "VCRIGHT_AlertMatrix9" ;
VAL_ 259 VCRIGHT_trunkLatchStatus 5 "LATCH_AJAR" 2 "LATCH_CLOSED" 3 "LATCH_CLOSING" 7 "LATCH_DEFAULT" 8 "LATCH_FAULT" 1 "LATCH_OPENED" 4 "LATCH_OPENING" 0 "LATCH_SNA" 6 "LATCH_TIMEOUT" ;
VAL_ 259 VCRIGHT_rearLatchStatus 5 "LATCH_AJAR" 2 "LATCH_CLOSED" 3 "LATCH_CLOSING" 7 "LATCH_DEFAULT" 8 "LATCH_FAULT" 1 "LATCH_OPENED" 4 "LATCH_OPENING" 0 "LATCH_SNA" 6 "LATCH_TIMEOUT" ;
VAL_ 259 VCRIGHT_frontLatchStatus 5 "LATCH_AJAR" 2 "LATCH_CLOSED" 3 "LATCH_CLOSING" 7 "LATCH_DEFAULT" 8 "LATCH_FAULT" 1 "LATCH_OPENED" 4 "LATCH_OPENING" 0 "LATCH_SNA" 6 "LATCH_TIMEOUT" ;
VAL_ 1251 VCRIGHT_seatStatusIndex 1 "SEAT_STATUS_INDEX_BACK" 2 "SEAT_STATUS_INDEX_LIFT" 4 "SEAT_STATUS_INDEX_LUMBAR" 6 "SEAT_STATUS_INDEX_OFFSETS" 5 "SEAT_STATUS_INDEX_POSITION" 3 "SEAT_STATUS_INDEX_TILT" 0 "SEAT_STATUS_INDEX_TRACK" ;
VAL_ 963 VCRIGHT_rearRightBuckleSwitch 3 "SWITCH_FAULT" 1 "SWITCH_OFF" 2 "SWITCH_ON" 0 "SWITCH_SNA" ;
VAL_ 963 VCRIGHT_rearCenterBuckleSwitch 3 "SWITCH_FAULT" 1 "SWITCH_OFF" 2 "SWITCH_ON" 0 "SWITCH_SNA" ;
VAL_ 963 VCRIGHT_frontBuckleSwitch 3 "SWITCH_FAULT" 1 "SWITCH_OFF" 2 "SWITCH_ON" 0 "SWITCH_SNA" ;
VAL_ 963 VCRIGHT_switchStatusIndex 0 "VCRIGHT_SWITCH_STATUS_INDEX_0" 1 "VCRIGHT_SWITCH_STATUS_INDEX_1" ;
VAL_ 899 VCRIGHT_thsSolarLoadVisible 1023 "SNA" ;
VAL_ 899 VCRIGHT_thsSolarLoadInfrared 1023 "SNA" ;
VAL_ 899 VCRIGHT_thsHumidity 127 "SNA" ;
VAL_ 899 VCRIGHT_thsTemperature 255 "SNA" ;
VAL_ 707 VCRIGHT_windowStatusIndex 0 "Mux0" 1 "Mux1" ;
VAL_ 1066 VCSEC_TPMSSensorState3 3 "SENSOR_CONNECTED" 4 "SENSOR_DISCONNECTING" 0 "SENSOR_NOT_PAIRED" 1 "SENSOR_WAIT_FOR_ADV" 2 "SENSOR_WAIT_FOR_CONN" 5 "SENSOR_WAIT_FOR_NEXT_ADV" ;
VAL_ 1066 VCSEC_TPMSSensorState2 3 "SENSOR_CONNECTED" 4 "SENSOR_DISCONNECTING" 0 "SENSOR_NOT_PAIRED" 1 "SENSOR_WAIT_FOR_ADV" 2 "SENSOR_WAIT_FOR_CONN" 5 "SENSOR_WAIT_FOR_NEXT_ADV" ;
VAL_ 1066 VCSEC_TPMSSensorState1 3 "SENSOR_CONNECTED" 4 "SENSOR_DISCONNECTING" 0 "SENSOR_NOT_PAIRED" 1 "SENSOR_WAIT_FOR_ADV" 2 "SENSOR_WAIT_FOR_CONN" 5 "SENSOR_WAIT_FOR_NEXT_ADV" ;
VAL_ 1066 VCSEC_TPMSSensorState0 3 "SENSOR_CONNECTED" 4 "SENSOR_DISCONNECTING" 0 "SENSOR_NOT_PAIRED" 1 "SENSOR_WAIT_FOR_ADV" 2 "SENSOR_WAIT_FOR_CONN" 5 "SENSOR_WAIT_FOR_NEXT_ADV" ;
VAL_ 570 VCSEC_TPMSStatusIndex 12 "CPUTimeSensor0" 13 "CPUTimeSensor1" 14 "CPUTimeSensor2" 15 "CPUTimeSensor3" 8 "CRCSensor0" 9 "CRCSensor1" 10 "CRCSensor2" 11 "CRCSensor3" 4 "ConnMetricsSensor0" 5 "ConnMetricsSensor1" 6 "ConnMetricsSensor2" 7 "ConnMetricsSensor3" 0 "MACAddressSensor0" 1 "MACAddressSensor1" 2 "MACAddressSensor2" 3 "MACAddressSensor3" 16 "SleepStatsSensor0" 17 "SleepStatsSensor1" 18 "SleepStatsSensor2" 19 "SleepStatsSensor3" ;
VAL_ 1655 VC_LVBMS_packVoltage 65535 "SNA" ;
VAL_ 1655 VC_LVBMS_MOSState 1 "LVBMS_MOS_STATE_CLOSED" 2 "LVBMS_MOS_STATE_INVALID" 0 "LVBMS_MOS_STATE_OPEN" 3 "LVBMS_MOS_STATE_SNA" ;
VAL_ 1655 VC_LVBMS_packCurrent 4194303 "SNA" ;
VAL_ 1655 VC_lvbmsStatusHighIndex 1 "LVBMS_STATUS_HIGH_CELL_VITALS_1" 2 "LVBMS_STATUS_HIGH_CELL_VITALS_2" 6 "LVBMS_STATUS_HIGH_INVALID" 0 "LVBMS_STATUS_HIGH_PACK_VITALS_1" 5 "LVBMS_STATUS_HIGH_PCS_INTERFACE" 4 "LVBMS_STATUS_HIGH_STATE_AND_COMMANDS" 3 "LVBMS_STATUS_HIGH_TARGETS" ;
VAL_ 1816 VC_LVBMS_SOC 127 "SNA" ;
VAL_ 1816 VC_lvbmsStatusLowIndex 5 "LVBMS_STATUS_LOW_FAULT_STATS" 6 "LVBMS_STATUS_LOW_INVALID" 4 "LVBMS_STATUS_LOW_PACK_VITALS_2" 0 "LVBMS_STATUS_LOW_STATE" 1 "LVBMS_STATUS_LOW_THROUGHPUT_1" 2 "LVBMS_STATUS_LOW_THROUGHPUT_2" 3 "LVBMS_STATUS_LOW_THROUGHPUT_3" ;
